VERSION "dbc-export 1 2025.20.8"

NS_ :

BS_:

BU_: ADSP APB APP APS APSB BB BMS CC CMP CMPD CP DAS DI DIF DIR DPB EPAS3P EPAS3S EPASTP EPASTS EPBL EPBR ESP GTW HVP IBST ICR IDB OCS1P ODIN PARK PCS PLG PM PMF PMR PTC RADC RCM RCM2 RCU SCCM SDCR TAS TCU TPMS TRCM UDS UI UIS UMC USM VC VCFRONT VCLEFT VCRIGHT VCSEC

BO_ 2013 VCLEFT_alertLog: 8 VCLEFT
 SG_ VCLEFT_alertID M : 0|10@1+ (1,0) [0|1023] "" Vector__XXX
 SG_ VCLEFT_a404_rightSteeringWheelSw m404 : 17|1@1+ (1,0) [0|1] "" Vector__XXX
 SG_ VCLEFT_a405_leftSteeringWheelSwi m405 : 16|1@1+ (1,0) [0|1] "" Vector__XXX
 SG_ VCLEFT_a405_rightSteeringWheelSw m405 : 17|1@1+ (1,0) [0|1] "" Vector__XXX
 SG_ VCLEFT_a406_leftSteeringWheelSwi m406 : 16|1@1+ (1,0) [0|1] "" Vector__XXX
 SG_ VCLEFT_a406_rightSteeringWheelSw m406 : 17|1@1+ (1,0) [0|1] "" Vector__XXX
 SG_ VCLEFT_a407_leftSteeringWheelSwi m407 : 16|1@1+ (1,0) [0|1] "" Vector__XXX
 SG_ VCLEFT_a407_rightSteeringWheelSw m407 : 17|1@1+ (1,0) [0|1] "" Vector__XXX
 SG_ VCLEFT_a409_leftScrollWheelFault m409 : 16|1@1+ (1,0) [0|1] "" Vector__XXX
 SG_ VCLEFT_a409_rightScrollWheelFaul m409 : 17|1@1+ (1,0) [0|1] "" Vector__XXX
 SG_ VCLEFT_a409_rightScrollWheelPrev m409 : 18|1@1+ (1,0) [0|1] "" Vector__XXX
 SG_ VCLEFT_a409_rightScrollWheelChal m409 : 24|16@1+ (1,0) [0|65535] "" Vector__XXX
 SG_ VCLEFT_a409_rightScrollWheelRaw0 m409 : 40|8@1+ (1,0) [0|255] "" Vector__XXX
 SG_ VCLEFT_a409_rightScrollWheelRaw1 m409 : 48|8@1+ (1,0) [0|255] "" Vector__XXX
 SG_ VCLEFT_a410_leftScrollWheelFault m410 : 16|1@1+ (1,0) [0|1] "" Vector__XXX
 SG_ VCLEFT_a410_rightScrollWheelFaul m410 : 17|1@1+ (1,0) [0|1] "" Vector__XXX
 SG_ VCLEFT_a411_leftScrollWheelFault m411 : 16|1@1+ (1,0) [0|1] "" Vector__XXX
 SG_ VCLEFT_a411_rightScrollWheelFaul m411 : 17|1@1+ (1,0) [0|1] "" Vector__XXX
 SG_ VCLEFT_a412_outputFaulted m412 : 16|1@1+ (1,0) [0|1] "" Vector__XXX
 SG_ VCLEFT_a412_currentSenseFaulted m412 : 17|1@1+ (1,0) [0|1] "" Vector__XXX
 SG_ VCLEFT_a412_tempSenseFaulted m412 : 18|1@1+ (1,0) [0|1] "" Vector__XXX
 SG_ VCLEFT_a412_underCurrent m412 : 19|1@1+ (1,0) [0|1] "" Vector__XXX
 SG_ VCLEFT_a412_overCurrent m412 : 20|1@1+ (1,0) [0|1] "" Vector__XXX
 SG_ VCLEFT_a412_overTemperature m412 : 21|1@1+ (1,0) [0|1] "" Vector__XXX
 SG_ VCLEFT_a414_leftHapticMotorFault m414 : 16|1@1+ (1,0) [0|1] "" Vector__XXX
 SG_ VCLEFT_a414_rightHapticMotorFaul m414 : 17|1@1+ (1,0) [0|1] "" Vector__XXX
 SG_ VCLEFT_a415_leftVbatUndervoltage m415 : 16|1@1+ (1,0) [0|1] "" Vector__XXX
 SG_ VCLEFT_a415_rightVbatUndervoltag m415 : 17|1@1+ (1,0) [0|1] "" Vector__XXX
 SG_ VCLEFT_a415_leftVbatOvervoltageF m415 : 18|1@1+ (1,0) [0|1] "" Vector__XXX
 SG_ VCLEFT_a415_rightVbatOvervoltage m415 : 19|1@1+ (1,0) [0|1] "" Vector__XXX
 SG_ VCLEFT_a417_leftDomeTouch m417 : 16|1@1+ (1,0) [0|1] "" Vector__XXX
 SG_ VCLEFT_a417_parkButtonTouch m417 : 17|1@1+ (1,0) [0|1] "" Vector__XXX
 SG_ VCLEFT_a417_reverseButtonTouch m417 : 18|1@1+ (1,0) [0|1] "" Vector__XXX
 SG_ VCLEFT_a417_hazardButtonTouch m417 : 19|1@1+ (1,0) [0|1] "" Vector__XXX
 SG_ VCLEFT_a417_neutralButtonTouch m417 : 20|1@1+ (1,0) [0|1] "" Vector__XXX
 SG_ VCLEFT_a417_driveButtonTouch m417 : 21|1@1+ (1,0) [0|1] "" Vector__XXX
 SG_ VCLEFT_a417_rightDomeTouch m417 : 22|1@1+ (1,0) [0|1] "" Vector__XXX
 SG_ VCLEFT_a419_leftDomeTouch m419 : 16|1@1+ (1,0) [0|1] "" Vector__XXX
 SG_ VCLEFT_a419_parkButtonTouch m419 : 17|1@1+ (1,0) [0|1] "" Vector__XXX
 SG_ VCLEFT_a419_reverseButtonTouch m419 : 18|1@1+ (1,0) [0|1] "" Vector__XXX
 SG_ VCLEFT_a419_hazardButtonTouch m419 : 19|1@1+ (1,0) [0|1] "" Vector__XXX
 SG_ VCLEFT_a419_neutralButtonTouch m419 : 20|1@1+ (1,0) [0|1] "" Vector__XXX
 SG_ VCLEFT_a419_driveButtonTouch m419 : 21|1@1+ (1,0) [0|1] "" Vector__XXX
 SG_ VCLEFT_a419_rightDomeTouch m419 : 22|1@1+ (1,0) [0|1] "" Vector__XXX
 SG_ VCLEFT_a420_leftDomeTouch m420 : 16|1@1+ (1,0) [0|1] "" Vector__XXX
 SG_ VCLEFT_a420_parkButtonTouch m420 : 17|1@1+ (1,0) [0|1] "" Vector__XXX
 SG_ VCLEFT_a420_reverseButtonTouch m420 : 18|1@1+ (1,0) [0|1] "" Vector__XXX
 SG_ VCLEFT_a420_hazardButtonTouch m420 : 19|1@1+ (1,0) [0|1] "" Vector__XXX
 SG_ VCLEFT_a420_neutralButtonTouch m420 : 20|1@1+ (1,0) [0|1] "" Vector__XXX
 SG_ VCLEFT_a420_driveButtonTouch m420 : 21|1@1+ (1,0) [0|1] "" Vector__XXX
 SG_ VCLEFT_a420_rightDomeTouch m420 : 22|1@1+ (1,0) [0|1] "" Vector__XXX
 SG_ VCLEFT_a421_parkButtonForce m421 : 16|1@1+ (1,0) [0|1] "" Vector__XXX
 SG_ VCLEFT_a421_reverseButtonForce m421 : 17|1@1+ (1,0) [0|1] "" Vector__XXX
 SG_ VCLEFT_a421_hazardButtonForce m421 : 18|1@1+ (1,0) [0|1] "" Vector__XXX
 SG_ VCLEFT_a421_neutralButtonForce m421 : 19|1@1+ (1,0) [0|1] "" Vector__XXX
 SG_ VCLEFT_a421_driveButtonForce m421 : 20|1@1+ (1,0) [0|1] "" Vector__XXX
 SG_ VCLEFT_a424_parkButtonLED m424 : 16|1@1+ (1,0) [0|1] "" Vector__XXX
 SG_ VCLEFT_a424_reverseButtonLED m424 : 17|1@1+ (1,0) [0|1] "" Vector__XXX
 SG_ VCLEFT_a424_neutralButtonLED m424 : 18|1@1+ (1,0) [0|1] "" Vector__XXX
 SG_ VCLEFT_a424_driveButtonLED m424 : 19|1@1+ (1,0) [0|1] "" Vector__XXX
 SG_ VCLEFT_a424_commonButtonLED m424 : 20|1@1+ (1,0) [0|1] "" Vector__XXX
 SG_ VCLEFT_a425_leftVisorLightStatus m425 : 16|1@1+ (1,0) [0|1] "" Vector__XXX
 SG_ VCLEFT_a425_rightVisorLightStatu m425 : 17|1@1+ (1,0) [0|1] "" Vector__XXX
 SG_ VCLEFT_a426_seatMotorCalibrated m426 : 16|1@1+ (1,0) [0|1] "" Vector__XXX
 SG_ VCLEFT_a426_seatMotorCurrent m426 : 17|12@1- (0.01,0) [-20.48|20.47] "A" Vector__XXX
 SG_ VCLEFT_a426_seatMotorPosReal m426 : 32|12@1- (1,0) [-2048|2047] "mm" Vector__XXX
 SG_ VCLEFT_a426_seatMotorState m426 : 44|3@1+ (1,0) [0|7] "" Vector__XXX
 SG_ VCLEFT_a426_seatSwitchBack m426 : 48|2@1+ (1,0) [1|3] "" Vector__XXX
 SG_ VCLEFT_a426_seatSwitchForward m426 : 50|2@1+ (1,0) [1|3] "" Vector__XXX
 SG_ VCLEFT_a426_cabinTmp m426 : 52|12@1- (0.1,0) [-204.8|204.7] "degC" Vector__XXX
 SG_ VCLEFT_a427_seatMotorCalibrated m427 : 16|1@1+ (1,0) [0|1] "" Vector__XXX
 SG_ VCLEFT_a427_seatMotorCurrent m427 : 17|12@1- (0.01,0) [-20.48|20.47] "A" Vector__XXX
 SG_ VCLEFT_a427_seatMotorPosReal m427 : 32|12@1- (1,0) [-2048|2047] "mm" Vector__XXX
 SG_ VCLEFT_a427_seatMotorState m427 : 44|3@1+ (1,0) [0|7] "" Vector__XXX
 SG_ VCLEFT_a427_seatSwitchBack m427 : 48|2@1+ (1,0) [1|3] "" Vector__XXX
 SG_ VCLEFT_a427_seatSwitchForward m427 : 50|2@1+ (1,0) [1|3] "" Vector__XXX
 SG_ VCLEFT_a427_cabinTmp m427 : 52|12@1- (0.1,0) [-204.8|204.7] "degC" Vector__XXX
 SG_ VCLEFT_a428_seatMotorCalibrated m428 : 16|1@1+ (1,0) [0|1] "" Vector__XXX
 SG_ VCLEFT_a428_seatMotorCurrent m428 : 17|12@1- (0.01,0) [-20.48|20.47] "A" Vector__XXX
 SG_ VCLEFT_a428_seatMotorPosReal m428 : 32|12@1- (1,0) [-2048|2047] "mm" Vector__XXX
 SG_ VCLEFT_a428_seatMotorState m428 : 44|3@1+ (1,0) [0|7] "" Vector__XXX
 SG_ VCLEFT_a428_seatSwitchBack m428 : 48|2@1+ (1,0) [1|3] "" Vector__XXX
 SG_ VCLEFT_a428_seatSwitchForward m428 : 50|2@1+ (1,0) [1|3] "" Vector__XXX
 SG_ VCLEFT_a428_cabinTmp m428 : 52|12@1- (0.1,0) [-204.8|204.7] "degC" Vector__XXX
 SG_ VCLEFT_a429_seatMotorCalibrated m429 : 16|1@1+ (1,0) [0|1] "" Vector__XXX
 SG_ VCLEFT_a429_seatMotorCurrent m429 : 17|12@1- (0.01,0) [-20.48|20.47] "A" Vector__XXX
 SG_ VCLEFT_a429_seatMotorPosReal m429 : 32|12@1- (1,0) [-2048|2047] "mm" Vector__XXX
 SG_ VCLEFT_a429_seatMotorState m429 : 44|3@1+ (1,0) [0|7] "" Vector__XXX
 SG_ VCLEFT_a429_seatSwitchBack m429 : 48|2@1+ (1,0) [1|3] "" Vector__XXX
 SG_ VCLEFT_a429_seatSwitchForward m429 : 50|2@1+ (1,0) [1|3] "" Vector__XXX
 SG_ VCLEFT_a429_cabinTmp m429 : 52|12@1- (0.1,0) [-204.8|204.7] "degC" Vector__XXX
 SG_ VCLEFT_a430_leftRearDomeLightPow m430 : 16|1@1+ (1,0) [0|1] "" Vector__XXX
 SG_ VCLEFT_a430_rightRearDomeLightPo m430 : 17|1@1+ (1,0) [0|1] "" Vector__XXX
 SG_ VCLEFT_a431_dcdcVoltageFailure m431 : 16|1@1+ (1,0) [0|1] "" Vector__XXX
 SG_ VCLEFT_a431_overVoltageDetected m431 : 17|1@1+ (1,0) [0|1] "" Vector__XXX
 SG_ VCLEFT_a431_underVoltageDetected m431 : 18|1@1+ (1,0) [0|1] "" Vector__XXX
 SG_ VCLEFT_a431_brownoutDetected m431 : 19|1@1+ (1,0) [0|1] "" Vector__XXX
 SG_ VCLEFT_a444_retriesAvailable m444 : 16|8@1+ (1,0) [0|255] "" Vector__XXX
 SG_ VCLEFT_a444_channel m444 : 24|8@1+ (1,0) [0|255] "" Vector__XXX
 SG_ VCLEFT_a444_watchdog m444 : 32|1@1+ (1,0) [0|1] "" Vector__XXX
 SG_ VCLEFT_a444_gateDriver m444 : 33|1@1+ (1,0) [0|1] "" Vector__XXX
 SG_ VCLEFT_a444_overcurrent m444 : 34|1@1+ (1,0) [0|1] "" Vector__XXX
 SG_ VCLEFT_a444_supplyUndervoltage m444 : 35|1@1+ (1,0) [0|1] "" Vector__XXX
 SG_ VCLEFT_a444_cpUndervoltage m444 : 36|1@1+ (1,0) [0|1] "" Vector__XXX
 SG_ VCLEFT_a444_overTempShutdown m444 : 37|1@1+ (1,0) [0|1] "" Vector__XXX
 SG_ VCLEFT_a444_overTempWarning m444 : 38|1@1+ (1,0) [0|1] "" Vector__XXX
 SG_ VCLEFT_a444_highSide2GateDriver m444 : 39|1@1+ (1,0) [0|1] "" Vector__XXX
 SG_ VCLEFT_a444_lowSide2GateDriver m444 : 40|1@1+ (1,0) [0|1] "" Vector__XXX
 SG_ VCLEFT_a444_highSide1GateDriver m444 : 41|1@1+ (1,0) [0|1] "" Vector__XXX
 SG_ VCLEFT_a444_lowSide1GateDriver m444 : 42|1@1+ (1,0) [0|1] "" Vector__XXX
 SG_ VCLEFT_a444_highSide2OverCurent m444 : 43|1@1+ (1,0) [0|1] "" Vector__XXX
 SG_ VCLEFT_a444_lowSide2OverCurent m444 : 44|1@1+ (1,0) [0|1] "" Vector__XXX
 SG_ VCLEFT_a444_highSide1OverCurent m444 : 45|1@1+ (1,0) [0|1] "" Vector__XXX
 SG_ VCLEFT_a444_lowSide1OverCurent m444 : 46|1@1+ (1,0) [0|1] "" Vector__XXX
 SG_ VCLEFT_a444_spiInit m444 : 47|1@1+ (1,0) [0|1] "" Vector__XXX
 SG_ VCLEFT_a444_spiPeriodicCheck m444 : 48|1@1+ (1,0) [0|1] "" Vector__XXX
 SG_ VCLEFT_a444_spiFault m444 : 49|1@1+ (1,0) [0|1] "" Vector__XXX
 SG_ VCLEFT_a444_voltageMonitor m444 : 50|1@1+ (1,0) [0|1] "" Vector__XXX
 SG_ VCLEFT_a444_enableLow m444 : 51|1@1+ (1,0) [0|1] "" Vector__XXX
 SG_ VCLEFT_a447_endstopPositionMM m447 : 16|16@1- (0.01,0) [-327.68|327.67] "mm" Vector__XXX
 SG_ VCLEFT_a447_motorType m447 : 32|2@1+ (1,0) [0|3] "" Vector__XXX
 SG_ VCLEFT_a448_endstopPositionMM m448 : 16|16@1- (0.01,0) [-327.68|327.67] "mm" Vector__XXX
 SG_ VCLEFT_a448_motorType m448 : 32|2@1+ (1,0) [0|3] "" Vector__XXX
 SG_ VCLEFT_a453_liftgatePosition m453 : 16|7@1- (1,43) [-21|106] "deg" Vector__XXX
 SG_ VCLEFT_a455_liftgateState m455 : 16|4@1+ (1,0) [0|15] "" Vector__XXX
 SG_ VCLEFT_a466_hvac2RLeftAirwaveVer m466 : 16|1@1+ (1,0) [0|1] "" Vector__XXX
 SG_ VCLEFT_a469_hvac2RLeftAirwaveLat m469 : 16|1@1+ (1,0) [0|1] "" Vector__XXX
 SG_ VCLEFT_a472_hvac2RRightAirwaveVe m472 : 16|1@1+ (1,0) [0|1] "" Vector__XXX
 SG_ VCLEFT_a475_hvac2RRightAirwaveLa m475 : 16|1@1+ (1,0) [0|1] "" Vector__XXX
 SG_ VCLEFT_a480_reset m480 : 16|1@1+ (1,0) [0|1] "" Vector__XXX
 SG_ VCLEFT_a480_spiError m480 : 17|1@1+ (1,0) [0|1] "" Vector__XXX
 SG_ VCLEFT_a480_autoOn m480 : 18|1@1+ (1,0) [0|1] "" Vector__XXX
 SG_ VCLEFT_a480_diagnosticBit m480 : 19|1@1+ (1,0) [0|1] "" Vector__XXX
 SG_ VCLEFT_a480_deviceError m480 : 20|1@1+ (1,0) [0|1] "" Vector__XXX
 SG_ VCLEFT_a480_overcurrent m480 : 21|1@1+ (1,0) [0|1] "" Vector__XXX
 SG_ VCLEFT_a480_unexpectedLock m480 : 22|1@1+ (1,0) [0|1] "" Vector__XXX
 SG_ VCLEFT_a480_disableOutputFault m480 : 23|1@1+ (1,0) [0|1] "" Vector__XXX
 SG_ VCLEFT_a480_vsUndervoltage m480 : 24|1@1+ (1,0) [0|1] "" Vector__XXX
 SG_ VCLEFT_a480_hardShort m480 : 25|1@1+ (1,0) [0|1] "" Vector__XXX
 SG_ VCLEFT_a480_vdsMax m480 : 26|1@1+ (1,0) [0|1] "" Vector__XXX
 SG_ VCLEFT_a480_bypassSaturation m480 : 27|1@1+ (1,0) [0|1] "" Vector__XXX
 SG_ VCLEFT_a480_fuseLatch m480 : 28|1@1+ (1,0) [0|1] "" Vector__XXX
 SG_ VCLEFT_a480_deviceOvertemperatur m480 : 29|1@1+ (1,0) [0|1] "" Vector__XXX
 SG_ VCLEFT_a480_ntcOvertemperature m480 : 30|1@1+ (1,0) [0|1] "" Vector__XXX
 SG_ VCLEFT_a480_vgsLow m480 : 31|1@1+ (1,0) [0|1] "" Vector__XXX
 SG_ VCLEFT_a480_chargePumpLow m480 : 32|1@1+ (1,0) [0|1] "" Vector__XXX
 SG_ VCLEFT_a480_watchdog m480 : 33|1@1+ (1,0) [0|1] "" Vector__XXX
 SG_ VCLEFT_a480_spiNotDone m480 : 34|1@1+ (1,0) [0|1] "" Vector__XXX
 SG_ VCLEFT_a480_configIncorrect m480 : 35|1@1+ (1,0) [0|1] "" Vector__XXX
 SG_ VCLEFT_a480_bufferFull m480 : 36|1@1+ (1,0) [0|1] "" Vector__XXX
 SG_ VCLEFT_a480_hitAlertRateLimit m480 : 37|1@1+ (1,0) [0|1] "" Vector__XXX
 SG_ VCLEFT_a480_hwlo m480 : 38|1@1+ (1,0) [0|1] "" Vector__XXX
 SG_ VCLEFT_a480_enable m480 : 39|1@1+ (1,0) [0|1] "" Vector__XXX
 SG_ VCLEFT_a482_channel m482 : 16|6@1+ (1,0) [0|63] "" Vector__XXX
 SG_ VCLEFT_a482_spiFault m482 : 22|1@1+ (1,0) [0|1] "" Vector__XXX
 SG_ VCLEFT_a482_resetBar m482 : 23|1@1+ (1,0) [0|1] "" Vector__XXX
 SG_ VCLEFT_a482_overTempShutdown m482 : 24|1@1+ (1,0) [0|1] "" Vector__XXX
 SG_ VCLEFT_a482_thermalWarning m482 : 25|1@1+ (1,0) [0|1] "" Vector__XXX
 SG_ VCLEFT_a482_underOrOverVoltageOr m482 : 26|1@1+ (1,0) [0|1] "" Vector__XXX
 SG_ VCLEFT_a482_underloadDetected m482 : 27|1@1+ (1,0) [0|1] "" Vector__XXX
 SG_ VCLEFT_a500_channel m500 : 16|8@1+ (1,0) [0|255] "" Vector__XXX
 SG_ VCLEFT_a500_mismatchedState m500 : 24|3@1+ (1,0) [0|7] "" Vector__XXX
 SG_ VCLEFT_a520_epbConfig m520 : 16|4@1+ (1,0) [0|15] "" Vector__XXX
 SG_ VCLEFT_a520_gtwEpbConfig m520 : 20|4@1+ (1,0) [0|15] "" Vector__XXX
 SG_ VCLEFT_a523_channel m523 : 16|8@1+ (1,0) [0|255] "" Vector__XXX
 SG_ VCLEFT_a523_control2Byte1 m523 : 24|8@1+ (1,0) [0|255] "" Vector__XXX
 SG_ VCLEFT_a523_control2Byte2 m523 : 32|8@1+ (1,0) [0|255] "" Vector__XXX
 SG_ VCLEFT_a523_control2Byte3 m523 : 40|8@1+ (1,0) [0|255] "" Vector__XXX
 SG_ VCLEFT_a523_control3Byte2 m523 : 48|8@1+ (1,0) [0|255] "" Vector__XXX
 SG_ VCLEFT_a523_control3Byte3 m523 : 56|8@1+ (1,0) [0|255] "" Vector__XXX
 SG_ VCLEFT_a525_GTW_twelveVBatteryTy m525 : 16|3@1+ (1,0) [0|7] "" Vector__XXX
 SG_ VCLEFT_a525_newLVBatteryType m525 : 19|3@1+ (1,0) [0|7] "" Vector__XXX
 SG_ VCLEFT_a525_initialLVBatteryType m525 : 24|3@1+ (1,0) [0|7] "" Vector__XXX
 SG_ VCLEFT_a525_serviceMode m525 : 27|1@1+ (1,0) [0|1] "" Vector__XXX
 SG_ VCLEFT_a525_factoryGated m525 : 28|1@1+ (1,0) [0|1] "" Vector__XXX
 SG_ VCLEFT_a525_frunkOpen m525 : 29|1@1+ (1,0) [0|1] "" Vector__XXX
 SG_ VCLEFT_a536_trunkFoldFlatSwitchS m536 : 16|2@1+ (1,0) [1|3] "" Vector__XXX
 SG_ VCLEFT_a536_trunkFoldFlatLeftSwi m536 : 18|10@1+ (0.00488758552819,0) [0|4.99999999534] "V" Vector__XXX
 SG_ VCLEFT_a545_GTW_twelveVBatteryTy m545 : 16|3@1+ (1,0) [0|7] "" Vector__XXX
 SG_ VCLEFT_a545_newLVBatteryType m545 : 19|3@1+ (1,0) [0|7] "" Vector__XXX
 SG_ VCLEFT_a545_serviceMode m545 : 22|1@1+ (1,0) [0|1] "" Vector__XXX
 SG_ VCLEFT_a545_factoryGated m545 : 23|1@1+ (1,0) [0|1] "" Vector__XXX
 SG_ VCLEFT_a545_frunkOpen m545 : 24|1@1+ (1,0) [0|1] "" Vector__XXX
 SG_ VCLEFT_a551_restrictDoorReleaseS m551 : 16|1@1+ (1,0) [0|1] "" Vector__XXX
 SG_ VCLEFT_a551_interiorReleaseReqCo m551 : 24|8@1+ (1,0) [0|255] "" Vector__XXX
 SG_ VCLEFT_a551_lastRequestSourceFro m551 : 32|3@1+ (1,0) [0|7] "" Vector__XXX
 SG_ VCLEFT_a551_restrictDoorRel_0001 m551 : 35|1@1+ (1,0) [0|1] "" Vector__XXX
 SG_ VCLEFT_a551_interiorRelease_0001 m551 : 40|8@1+ (1,0) [0|255] "" Vector__XXX
 SG_ VCLEFT_a551_lastRequestSourceRea m551 : 48|3@1+ (1,0) [0|7] "" Vector__XXX
 SG_ VCLEFT_a555_heaterPWMCommand m555 : 16|8@1+ (1,0) [0|255] "" Vector__XXX
 SG_ VCLEFT_a555_ntcTemperature m555 : 24|8@1+ (1,0) [0|255] "" Vector__XXX
 SG_ VCLEFT_a560_isRearwardEndstopUnc m560 : 16|1@1+ (1,0) [0|1] "" Vector__XXX
 SG_ VCLEFT_a560_isAbsPosSensorUncali m560 : 17|1@1+ (1,0) [0|1] "" Vector__XXX
 SG_ VCLEFT_a560_seatState m560 : 18|4@1+ (1,0) [0|14] "" Vector__XXX
 SG_ VCLEFT_a560_motorType m560 : 22|1@1+ (1,0) [0|1] "" Vector__XXX
 SG_ VCLEFT_a560_absPosSensState m560 : 24|2@1+ (1,0) [0|3] "" Vector__XXX
 SG_ VCLEFT_a563_calibrated m563 : 16|1@1+ (1,0) [0|1] "" Vector__XXX
 SG_ VCLEFT_a563_angle m563 : 17|8@1- (0.5,59) [-5|122.5] "deg" Vector__XXX
 SG_ VCLEFT_a563_seatStatePrev m563 : 25|4@1+ (1,0) [0|14] "" Vector__XXX
 SG_ VCLEFT_a563_obstacleDetectReason m563 : 29|4@1+ (1,0) [0|15] "" Vector__XXX
 SG_ VCLEFT_a563_accelLookbackTripDep m563 : 33|7@1+ (1,0) [0|127] "" Vector__XXX
 SG_ VCLEFT_a563_duty m563 : 40|8@1- (1,0) [-128|127] "%" Vector__XXX
 SG_ VCLEFT_a563_currentAbsFilt m563 : 48|8@1+ (0.25,0) [0|63.75] "A" Vector__XXX
 SG_ VCLEFT_a563_motorType m563 : 56|1@1+ (1,0) [0|1] "" Vector__XXX
 SG_ VCLEFT_a563_absolutePosSensorFor m563 : 57|1@1+ (1,0) [0|1] "" Vector__XXX
 SG_ VCLEFT_a563_cabinTemp m563 : 58|6@1- (2,20) [-44|82] "degC" Vector__XXX
 SG_ VCLEFT_a567_isRearwardEndstopUnc m567 : 16|1@1+ (1,0) [0|1] "" Vector__XXX
 SG_ VCLEFT_a567_isAbsPosSensorUncali m567 : 17|1@1+ (1,0) [0|1] "" Vector__XXX
 SG_ VCLEFT_a568_seatState m568 : 16|4@1+ (1,0) [0|14] "" Vector__XXX
 SG_ VCLEFT_a570_seatHeatCurrent m570 : 16|12@1+ (0.01,0) [0|40.95] "A" Vector__XXX
 SG_ VCLEFT_a570_seatHeatTmp m570 : 28|12@1- (0.05,0) [-102.4|102.35] "degC" Vector__XXX
 SG_ VCLEFT_a571_seatHeatCurrent m571 : 16|12@1+ (0.01,0) [0|40.95] "A" Vector__XXX
 SG_ VCLEFT_a571_seatHeatTmp m571 : 28|12@1- (0.05,0) [-102.4|102.35] "degC" Vector__XXX
 SG_ VCLEFT_a572_seatHeatCurrent m572 : 16|12@1+ (0.01,0) [0|40.95] "A" Vector__XXX
 SG_ VCLEFT_a572_seatHeatTmp m572 : 28|12@1- (0.05,0) [-102.4|102.35] "degC" Vector__XXX
 SG_ VCLEFT_a573_seatHeatCurrent m573 : 16|12@1+ (0.01,0) [0|40.95] "A" Vector__XXX
 SG_ VCLEFT_a573_seatHeatTmp m573 : 28|12@1- (0.05,0) [-102.4|102.35] "degC" Vector__XXX
 SG_ VCLEFT_a577_outputFaulted m577 : 16|1@1+ (1,0) [0|1] "" Vector__XXX
 SG_ VCLEFT_a577_currentSenseFaulted m577 : 17|1@1+ (1,0) [0|1] "" Vector__XXX
 SG_ VCLEFT_a577_tempSenseFaulted m577 : 18|1@1+ (1,0) [0|1] "" Vector__XXX
 SG_ VCLEFT_a577_underCurrent m577 : 19|1@1+ (1,0) [0|1] "" Vector__XXX
 SG_ VCLEFT_a577_overCurrent m577 : 20|1@1+ (1,0) [0|1] "" Vector__XXX
 SG_ VCLEFT_a577_overTemperature m577 : 21|1@1+ (1,0) [0|1] "" Vector__XXX
 SG_ VCLEFT_a578_openCircuitDashFL m578 : 16|1@1+ (1,0) [0|1] "" Vector__XXX
 SG_ VCLEFT_a578_shortCircuitDashFL m578 : 17|1@1+ (1,0) [0|1] "" Vector__XXX
 SG_ VCLEFT_a578_miaDashFL m578 : 18|1@1+ (1,0) [0|1] "" Vector__XXX
 SG_ VCLEFT_a578_openCircuitDashFR m578 : 19|1@1+ (1,0) [0|1] "" Vector__XXX
 SG_ VCLEFT_a578_shortCircuitDashFR m578 : 20|1@1+ (1,0) [0|1] "" Vector__XXX
 SG_ VCLEFT_a578_miaDashFR m578 : 21|1@1+ (1,0) [0|1] "" Vector__XXX
 SG_ VCLEFT_a578_openCircuitDoorFL m578 : 22|1@1+ (1,0) [0|1] "" Vector__XXX
 SG_ VCLEFT_a578_shortCircuitDoorFL m578 : 23|1@1+ (1,0) [0|1] "" Vector__XXX
 SG_ VCLEFT_a578_miaDoorFL m578 : 24|1@1+ (1,0) [0|1] "" Vector__XXX
 SG_ VCLEFT_a578_openCircuitDoorRL m578 : 25|1@1+ (1,0) [0|1] "" Vector__XXX
 SG_ VCLEFT_a578_shortCircuitDoorRL m578 : 26|1@1+ (1,0) [0|1] "" Vector__XXX
 SG_ VCLEFT_a578_miaDoorRL m578 : 27|1@1+ (1,0) [0|1] "" Vector__XXX
 SG_ VCLEFT_a579_gtwConfigType m579 : 16|3@1+ (1,0) [0|7] "" Vector__XXX
 SG_ VCLEFT_a579_installedHwid m579 : 24|32@1+ (1,0) [0|4294967295] "" Vector__XXX
 SG_ VCLEFT_a580_gtwConfigType m580 : 16|3@1+ (1,0) [0|7] "" Vector__XXX
 SG_ VCLEFT_a580_installedHwid m580 : 24|32@1+ (1,0) [0|4294967295] "" Vector__XXX
 SG_ VCLEFT_a581_outputFaulted m581 : 16|1@1+ (1,0) [0|1] "" Vector__XXX
 SG_ VCLEFT_a581_currentSenseFaulted m581 : 17|1@1+ (1,0) [0|1] "" Vector__XXX
 SG_ VCLEFT_a581_tempSenseFaulted m581 : 18|1@1+ (1,0) [0|1] "" Vector__XXX
 SG_ VCLEFT_a581_underCurrent m581 : 19|1@1+ (1,0) [0|1] "" Vector__XXX
 SG_ VCLEFT_a581_overCurrent m581 : 20|1@1+ (1,0) [0|1] "" Vector__XXX
 SG_ VCLEFT_a581_overTemperature m581 : 21|1@1+ (1,0) [0|1] "" Vector__XXX
 SG_ VCLEFT_a585_ambientTemp m585 : 16|8@1+ (0.5,-40) [-39.5|87.5] "degC" Vector__XXX
 SG_ VCLEFT_a586_ambientTemp m586 : 16|8@1+ (0.5,-40) [-39.5|87.5] "degC" Vector__XXX
 SG_ VCLEFT_a599_GTW_twelveVBatteryTy m599 : 16|3@1+ (1,0) [0|7] "" Vector__XXX
 SG_ VCLEFT_a599_newLVBatteryType m599 : 19|3@1+ (1,0) [0|7] "" Vector__XXX
 SG_ VCLEFT_a599_initialLVBatteryType m599 : 24|3@1+ (1,0) [0|7] "" Vector__XXX
 SG_ VCLEFT_a599_serviceMode m599 : 27|1@1+ (1,0) [0|1] "" Vector__XXX
 SG_ VCLEFT_a599_factoryGated m599 : 28|1@1+ (1,0) [0|1] "" Vector__XXX
 SG_ VCLEFT_a599_frunkOpen m599 : 29|1@1+ (1,0) [0|1] "" Vector__XXX
 SG_ VCLEFT_a617_VEH_VC_infoMessage m617 : 16|1@1+ (1,0) [0|1] "" Vector__XXX
 SG_ VCLEFT_a617_BDY_defogInfoMessage m617 : 17|1@1+ (1,0) [0|1] "" Vector__XXX
 SG_ VCLEFT_a617_VEH_defogInfoMessage m617 : 18|1@1+ (1,0) [0|1] "" Vector__XXX
 SG_ VCLEFT_a617_VEH_thermalStatus m617 : 19|1@1+ (1,0) [0|1] "" Vector__XXX

BO_ 864 VCLEFT_alertMatrix: 8 VCLEFT
 SG_ VCLEFT_matrixIndex M : 0|4@1+ (1,0) [0|15] "" Vector__XXX
 SG_ VCLEFT_a001_WatchdogReset m0 : 4|1@1+ (1,0) [0|1] "" Vector__XXX
 SG_ VCLEFT_a002_PowerLossReset m0 : 5|1@1+ (1,0) [0|1] "" Vector__XXX
 SG_ VCLEFT_a003_SWAssertion m0 : 6|1@1+ (1,0) [0|1] "" Vector__XXX
 SG_ VCLEFT_a005_CANTXError m0 : 8|1@1+ (1,0) [0|1] "" Vector__XXX
 SG_ VCLEFT_a006_CANTX_cyclicError m0 : 9|1@1+ (1,0) [0|1] "" Vector__XXX
 SG_ VCLEFT_a010_ExtSupplyVoltError m0 : 13|1@1+ (1,0) [0|1] "" Vector__XXX
 SG_ VCLEFT_a012_CPUReset m0 : 15|1@1+ (1,0) [0|1] "" Vector__XXX
 SG_ VCLEFT_a013_AlertManagerFault m0 : 16|1@1+ (1,0) [0|1] "" Vector__XXX
 SG_ VCLEFT_a015_NVMMError m0 : 18|1@1+ (1,0) [0|1] "" Vector__XXX
 SG_ VCLEFT_a016_NVMMRecordError m0 : 19|1@1+ (1,0) [0|1] "" Vector__XXX
 SG_ VCLEFT_a017_NVMMStatusDbg m0 : 20|1@1+ (1,0) [0|1] "" Vector__XXX
 SG_ VCLEFT_a021_TaskSchedulerError m0 : 24|1@1+ (1,0) [0|1] "" Vector__XXX
 SG_ VCLEFT_a022_TaskInitError m0 : 25|1@1+ (1,0) [0|1] "" Vector__XXX
 SG_ VCLEFT_a029_CoreDump m0 : 32|1@1+ (1,0) [0|1] "" Vector__XXX
 SG_ VCLEFT_a030_ECULogUploadRequest m0 : 33|1@1+ (1,0) [0|1] "" Vector__XXX
 SG_ VCLEFT_a031_UDSActive m0 : 34|1@1+ (1,0) [0|1] "" Vector__XXX
 SG_ VCLEFT_a041_HighCPULoad m0 : 44|1@1+ (1,0) [0|1] "" Vector__XXX
 SG_ VCLEFT_a042_HighStackUsage m0 : 45|1@1+ (1,0) [0|1] "" Vector__XXX
 SG_ VCLEFT_a043_Task1msError m0 : 46|1@1+ (1,0) [0|1] "" Vector__XXX
 SG_ VCLEFT_a044_Task10msError m0 : 47|1@1+ (1,0) [0|1] "" Vector__XXX
 SG_ VCLEFT_a045_Task100msError m0 : 48|1@1+ (1,0) [0|1] "" Vector__XXX
 SG_ VCLEFT_a046_Task1000msError m0 : 49|1@1+ (1,0) [0|1] "" Vector__XXX
 SG_ VCLEFT_a057_HVP_MIA m0 : 60|1@1+ (1,0) [0|1] "" Vector__XXX
 SG_ VCLEFT_a058_inputRHighSyncDebug m0 : 61|1@1+ (1,0) [0|1] "" Vector__XXX
 SG_ VCLEFT_a059_inputResistanceHigh m0 : 62|1@1+ (1,0) [0|1] "" Vector__XXX
 SG_ VCLEFT_a060_engineeringBuild m0 : 63|1@1+ (1,0) [0|1] "" Vector__XXX
 SG_ VCLEFT_a061_XCPConnected m1 : 4|1@1+ (1,0) [0|1] "" Vector__XXX
 SG_ VCLEFT_a062_XCPWasConnected m1 : 5|1@1+ (1,0) [0|1] "" Vector__XXX
 SG_ VCLEFT_a063_SwitchFault m1 : 6|1@1+ (1,0) [0|1] "" Vector__XXX
 SG_ VCLEFT_a064_busSleepReqTimeout m1 : 7|1@1+ (1,0) [0|1] "" Vector__XXX
 SG_ VCLEFT_a065_emiosIsrRateLimitedD m1 : 8|1@1+ (1,0) [0|1] "" Vector__XXX
 SG_ VCLEFT_a066_emiosIsrShortPeriodD m1 : 9|1@1+ (1,0) [0|1] "" Vector__XXX
 SG_ VCLEFT_a082_VCRIGHT_IPC_MIA m1 : 25|1@1+ (1,0) [0|1] "" Vector__XXX
 SG_ VCLEFT_a083_VCLEFT_IPC_MIA m1 : 26|1@1+ (1,0) [0|1] "" Vector__XXX
 SG_ VCLEFT_a084_TPMS_MIA m1 : 27|1@1+ (1,0) [0|1] "" Vector__XXX
 SG_ VCLEFT_a085_CCCM_MIA m1 : 28|1@1+ (1,0) [0|1] "" Vector__XXX
 SG_ VCLEFT_a086_VCBATT_MIA m1 : 29|1@1+ (1,0) [0|1] "" Vector__XXX
 SG_ VCLEFT_a087_DIREL_MIA m1 : 30|1@1+ (1,0) [0|1] "" Vector__XXX
 SG_ VCLEFT_a088_DIRER_MIA m1 : 31|1@1+ (1,0) [0|1] "" Vector__XXX
 SG_ VCLEFT_a089_IBST_MIA m1 : 32|1@1+ (1,0) [0|1] "" Vector__XXX
 SG_ VCLEFT_a090_APS_MIA m1 : 33|1@1+ (1,0) [0|1] "" Vector__XXX
 SG_ VCLEFT_a091_CMPD_MIA m1 : 34|1@1+ (1,0) [0|1] "" Vector__XXX
 SG_ VCLEFT_a092_VCSEATD_MIA m1 : 35|1@1+ (1,0) [0|1] "" Vector__XXX
 SG_ VCLEFT_a093_VCSEATP_MIA m1 : 36|1@1+ (1,0) [0|1] "" Vector__XXX
 SG_ VCLEFT_a094_EPAS3P_MIA m1 : 37|1@1+ (1,0) [0|1] "" Vector__XXX
 SG_ VCLEFT_a095_CHG_MIA m1 : 38|1@1+ (1,0) [0|1] "" Vector__XXX
 SG_ VCLEFT_a096_OCS1P_MIA m1 : 39|1@1+ (1,0) [0|1] "" Vector__XXX
 SG_ VCLEFT_a097_CMP_MIA m1 : 40|1@1+ (1,0) [0|1] "" Vector__XXX
 SG_ VCLEFT_a098_DIR_MIA m1 : 41|1@1+ (1,0) [0|1] "" Vector__XXX
 SG_ VCLEFT_a099_PARK_MIA m1 : 42|1@1+ (1,0) [0|1] "" Vector__XXX
 SG_ VCLEFT_a100_CANbus_MIA m1 : 43|1@1+ (1,0) [0|1] "" Vector__XXX
 SG_ VCLEFT_a101_PM_MIA m1 : 44|1@1+ (1,0) [0|1] "" Vector__XXX
 SG_ VCLEFT_a102_PTC_MIA m1 : 45|1@1+ (1,0) [0|1] "" Vector__XXX
 SG_ VCLEFT_a103_CP_MIA m1 : 46|1@1+ (1,0) [0|1] "" Vector__XXX
 SG_ VCLEFT_a104_DAS_MIA m1 : 47|1@1+ (1,0) [0|1] "" Vector__XXX
 SG_ VCLEFT_a105_TAS_MIA m1 : 48|1@1+ (1,0) [0|1] "" Vector__XXX
 SG_ VCLEFT_a106_PCS_MIA m1 : 49|1@1+ (1,0) [0|1] "" Vector__XXX
 SG_ VCLEFT_a107_BMS_MIA m1 : 50|1@1+ (1,0) [0|1] "" Vector__XXX
 SG_ VCLEFT_a108_DIF_MIA m1 : 51|1@1+ (1,0) [0|1] "" Vector__XXX
 SG_ VCLEFT_a109_RCM_MIA m1 : 52|1@1+ (1,0) [0|1] "" Vector__XXX
 SG_ VCLEFT_a110_GTW_MIA m1 : 53|1@1+ (1,0) [0|1] "" Vector__XXX
 SG_ VCLEFT_a111_EPBR_MIA m1 : 54|1@1+ (1,0) [0|1] "" Vector__XXX
 SG_ VCLEFT_a112_EPBL_MIA m1 : 55|1@1+ (1,0) [0|1] "" Vector__XXX
 SG_ VCLEFT_a113_UI_MIA m1 : 56|1@1+ (1,0) [0|1] "" Vector__XXX
 SG_ VCLEFT_a114_ESP_MIA m1 : 57|1@1+ (1,0) [0|1] "" Vector__XXX
 SG_ VCLEFT_a115_VCSEC_MIA m1 : 58|1@1+ (1,0) [0|1] "" Vector__XXX
 SG_ VCLEFT_a116_VCRIGHT_MIA m1 : 59|1@1+ (1,0) [0|1] "" Vector__XXX
 SG_ VCLEFT_a117_VCLEFT_MIA m1 : 60|1@1+ (1,0) [0|1] "" Vector__XXX
 SG_ VCLEFT_a118_VCFRONT_MIA m1 : 61|1@1+ (1,0) [0|1] "" Vector__XXX
 SG_ VCLEFT_a119_SCCM_MIA m1 : 62|1@1+ (1,0) [0|1] "" Vector__XXX
 SG_ VCLEFT_a120_DI_DRIVE_MIA m1 : 63|1@1+ (1,0) [0|1] "" Vector__XXX
 SG_ VCLEFT_a121_ETC_MIA m2 : 4|1@1+ (1,0) [0|1] "" Vector__XXX
 SG_ VCLEFT_a122_ICR_MIA m2 : 5|1@1+ (1,0) [0|1] "" Vector__XXX
 SG_ VCLEFT_a123_AID_MIA m2 : 6|1@1+ (1,0) [0|1] "" Vector__XXX
 SG_ VCLEFT_a124_BB_MIA m2 : 7|1@1+ (1,0) [0|1] "" Vector__XXX
 SG_ VCLEFT_a125_RCU_MIA m2 : 8|1@1+ (1,0) [0|1] "" Vector__XXX
 SG_ VCLEFT_a129_blowerICLatchFault m2 : 12|1@1+ (1,0) [0|1] "" Vector__XXX
 SG_ VCLEFT_a130_blowerICWarning m2 : 13|1@1+ (1,0) [0|1] "" Vector__XXX
 SG_ VCLEFT_a131_blowerICTransFault m2 : 14|1@1+ (1,0) [0|1] "" Vector__XXX
 SG_ VCLEFT_a132_blowerSoftStall m2 : 15|1@1+ (1,0) [0|1] "" Vector__XXX
 SG_ VCLEFT_a133_blowerLowRPMCBang m2 : 16|1@1+ (1,0) [0|1] "" Vector__XXX
 SG_ VCLEFT_a134_SteerColUpDownUnCal m2 : 17|1@1+ (1,0) [0|1] "" Vector__XXX
 SG_ VCLEFT_a135_SteerColInOutUnCal m2 : 18|1@1+ (1,0) [0|1] "" Vector__XXX
 SG_ VCLEFT_a136_brakeSwitchMismatch m2 : 19|1@1+ (1,0) [0|1] "" Vector__XXX
 SG_ VCLEFT_a137_VCSECPowerCycled m2 : 20|1@1+ (1,0) [0|1] "" Vector__XXX
 SG_ VCLEFT_a138_consoleDoorAssist m2 : 21|1@1+ (1,0) [0|1] "" Vector__XXX
 SG_ VCLEFT_a139_BLERearPowerCycled m2 : 22|1@1+ (1,0) [0|1] "" Vector__XXX
 SG_ VCLEFT_a140_BLELeftPowerCycled m2 : 23|1@1+ (1,0) [0|1] "" Vector__XXX
 SG_ VCLEFT_a141_12VAuxPowerTrip m2 : 24|1@1+ (1,0) [0|1] "" Vector__XXX
 SG_ VCLEFT_a143_mirrorManuallyFolded m2 : 26|1@1+ (1,0) [0|1] "" Vector__XXX
 SG_ VCLEFT_a145_brakeSwitchStuck m2 : 28|1@1+ (1,0) [0|1] "" Vector__XXX
 SG_ VCLEFT_a148_brakePressInputMisma m2 : 31|1@1+ (1,0) [0|1] "" Vector__XXX
 SG_ VCLEFT_a150_windowPinchFront m2 : 33|1@1+ (1,0) [0|1] "" Vector__XXX
 SG_ VCLEFT_a151_windowPinchRear m2 : 34|1@1+ (1,0) [0|1] "" Vector__XXX
 SG_ VCLEFT_a152_windowUncalFront m2 : 35|1@1+ (1,0) [0|1] "" Vector__XXX
 SG_ VCLEFT_a153_windowUncalRear m2 : 36|1@1+ (1,0) [0|1] "" Vector__XXX
 SG_ VCLEFT_a154_windowThermalFront m2 : 37|1@1+ (1,0) [0|1] "" Vector__XXX
 SG_ VCLEFT_a155_windowThermalRear m2 : 38|1@1+ (1,0) [0|1] "" Vector__XXX
 SG_ VCLEFT_a156_windowNoInputFront m2 : 39|1@1+ (1,0) [0|1] "" Vector__XXX
 SG_ VCLEFT_a157_windowNoInputRear m2 : 40|1@1+ (1,0) [0|1] "" Vector__XXX
 SG_ VCLEFT_a158_windowPinchOverideF m2 : 41|1@1+ (1,0) [0|1] "" Vector__XXX
 SG_ VCLEFT_a159_windowPinchOverideR m2 : 42|1@1+ (1,0) [0|1] "" Vector__XXX
 SG_ VCLEFT_a160_windowUndercurrentF m2 : 43|1@1+ (1,0) [0|1] "" Vector__XXX
 SG_ VCLEFT_a161_windowUndercurrentR m2 : 44|1@1+ (1,0) [0|1] "" Vector__XXX
 SG_ VCLEFT_a162_windowEncoderStallF m2 : 45|1@1+ (1,0) [0|1] "" Vector__XXX
 SG_ VCLEFT_a163_windowEncoderStallR m2 : 46|1@1+ (1,0) [0|1] "" Vector__XXX
 SG_ VCLEFT_a164_windowFactoryTest m2 : 47|1@1+ (1,0) [0|1] "" Vector__XXX
 SG_ VCLEFT_a165_windowFactoryTest2 m2 : 48|1@1+ (1,0) [0|1] "" Vector__XXX
 SG_ VCLEFT_a166_windowDebug m2 : 49|1@1+ (1,0) [0|1] "" Vector__XXX
 SG_ VCLEFT_a167_windowDebugPinchF m2 : 50|1@1+ (1,0) [0|1] "" Vector__XXX
 SG_ VCLEFT_a168_windowDebugPinchR m2 : 51|1@1+ (1,0) [0|1] "" Vector__XXX
 SG_ VCLEFT_a169_windowCurrentPeakF m2 : 52|1@1+ (1,0) [0|1] "" Vector__XXX
 SG_ VCLEFT_a170_windowCurrentPeakR m2 : 53|1@1+ (1,0) [0|1] "" Vector__XXX
 SG_ VCLEFT_a172_SPI_MIA m2 : 55|1@1+ (1,0) [0|1] "" Vector__XXX
 SG_ VCLEFT_a173_windowBtnDoorOpen m2 : 56|1@1+ (1,0) [0|1] "" Vector__XXX
 SG_ VCLEFT_a175_windowSealDefectFron m2 : 58|1@1+ (1,0) [0|1] "" Vector__XXX
 SG_ VCLEFT_a176_windowSealDefectRear m2 : 59|1@1+ (1,0) [0|1] "" Vector__XXX
 SG_ VCLEFT_a180_frontDoorLatchRehome m2 : 63|1@1+ (1,0) [0|1] "" Vector__XXX
 SG_ VCLEFT_a181_rearDoorLatchRehome m3 : 4|1@1+ (1,0) [0|1] "" Vector__XXX
 SG_ VCLEFT_a182_emergencyLatchRel m3 : 5|1@1+ (1,0) [0|1] "" Vector__XXX
 SG_ VCLEFT_a183_doorStateFactoryTest m3 : 6|1@1+ (1,0) [0|1] "" Vector__XXX
 SG_ VCLEFT_a185_summonAborted m3 : 8|1@1+ (1,0) [0|1] "" Vector__XXX
 SG_ VCLEFT_a186_latchReleaseFailedF m3 : 9|1@1+ (1,0) [0|1] "" Vector__XXX
 SG_ VCLEFT_a187_latchReleaseFailedR m3 : 10|1@1+ (1,0) [0|1] "" Vector__XXX
 SG_ VCLEFT_a188_latchUnableToRearmF m3 : 11|1@1+ (1,0) [0|1] "" Vector__XXX
 SG_ VCLEFT_a189_latchUnableToRearmR m3 : 12|1@1+ (1,0) [0|1] "" Vector__XXX
 SG_ VCLEFT_a190_eFuseMgmtVbatFused m3 : 13|1@1+ (1,0) [0|1] "" Vector__XXX
 SG_ VCLEFT_a191_TLCOvercurrent m3 : 14|1@1+ (1,0) [0|1] "" Vector__XXX
 SG_ VCLEFT_a192_blowerGeneralFault m3 : 15|1@1+ (1,0) [0|1] "" Vector__XXX
 SG_ VCLEFT_a193_blowerMIA m3 : 16|1@1+ (1,0) [0|1] "" Vector__XXX
 SG_ VCLEFT_a194_blowerUnidentified m3 : 17|1@1+ (1,0) [0|1] "" Vector__XXX
 SG_ VCLEFT_a195_blowerIdentification m3 : 18|1@1+ (1,0) [0|1] "" Vector__XXX
 SG_ VCLEFT_a196_VEHCANOverterminate m3 : 19|1@1+ (1,0) [0|1] "" Vector__XXX
 SG_ VCLEFT_a197_VEHCANUndertrminate m3 : 20|1@1+ (1,0) [0|1] "" Vector__XXX
 SG_ VCLEFT_a200_motorPhantomEncoder m3 : 23|1@1+ (1,0) [0|1] "" Vector__XXX
 SG_ VCLEFT_a201_motorDutyEncDisabl m3 : 24|1@1+ (1,0) [0|1] "" Vector__XXX
 SG_ VCLEFT_a202_epbmUnderIStatic m3 : 25|1@1+ (1,0) [0|1] "" Vector__XXX
 SG_ VCLEFT_a203_epbmOverIStatic m3 : 26|1@1+ (1,0) [0|1] "" Vector__XXX
 SG_ VCLEFT_a204_epbmUnderIDyn m3 : 27|1@1+ (1,0) [0|1] "" Vector__XXX
 SG_ VCLEFT_a205_epbmOverIDyn m3 : 28|1@1+ (1,0) [0|1] "" Vector__XXX
 SG_ VCLEFT_a206_epbWrongDirection m3 : 29|1@1+ (1,0) [0|1] "" Vector__XXX
 SG_ VCLEFT_a207_epbmEnableWrong m3 : 30|1@1+ (1,0) [0|1] "" Vector__XXX
 SG_ VCLEFT_a208_epbFaulted m3 : 31|1@1+ (1,0) [0|1] "" Vector__XXX
 SG_ VCLEFT_a209_epbStateMisTime m3 : 32|1@1+ (1,0) [0|1] "" Vector__XXX
 SG_ VCLEFT_a210_epbStateTime m3 : 33|1@1+ (1,0) [0|1] "" Vector__XXX
 SG_ VCLEFT_a211_epbmUnderIStaticNew m3 : 34|1@1+ (1,0) [0|1] "" Vector__XXX
 SG_ VCLEFT_a212_epbmOverIStaticNew m3 : 35|1@1+ (1,0) [0|1] "" Vector__XXX
 SG_ VCLEFT_a213_epbmUnderIDynNew m3 : 36|1@1+ (1,0) [0|1] "" Vector__XXX
 SG_ VCLEFT_a214_epbmOverIDynNew m3 : 37|1@1+ (1,0) [0|1] "" Vector__XXX
 SG_ VCLEFT_a215_currentDesyncWarning m3 : 38|1@1+ (1,0) [0|1] "" Vector__XXX
 SG_ VCLEFT_a216_SPI_MIA_debugData1 m3 : 39|1@1+ (1,0) [0|1] "" Vector__XXX
 SG_ VCLEFT_a217_SPI_MIA_debugData2 m3 : 40|1@1+ (1,0) [0|1] "" Vector__XXX
 SG_ VCLEFT_a218_motorDriverFault m3 : 41|1@1+ (1,0) [0|1] "" Vector__XXX
 SG_ VCLEFT_a219_motorCurrentDropout m3 : 42|1@1+ (1,0) [0|1] "" Vector__XXX
 SG_ VCLEFT_a224_seatEncStallTrack m3 : 47|1@1+ (1,0) [0|1] "" Vector__XXX
 SG_ VCLEFT_a225_seatEncStallBack m3 : 48|1@1+ (1,0) [0|1] "" Vector__XXX
 SG_ VCLEFT_a226_seatEncStallTilt m3 : 49|1@1+ (1,0) [0|1] "" Vector__XXX
 SG_ VCLEFT_a227_seatEncStallLift m3 : 50|1@1+ (1,0) [0|1] "" Vector__XXX
 SG_ VCLEFT_a228_seatEncOverTrack m3 : 51|1@1+ (1,0) [0|1] "" Vector__XXX
 SG_ VCLEFT_a229_seatEncOverBack m3 : 52|1@1+ (1,0) [0|1] "" Vector__XXX
 SG_ VCLEFT_a230_seatEncOverTilt m3 : 53|1@1+ (1,0) [0|1] "" Vector__XXX
 SG_ VCLEFT_a231_seatEncOverLift m3 : 54|1@1+ (1,0) [0|1] "" Vector__XXX
 SG_ VCLEFT_a232_seatCurrUnderTrack m3 : 55|1@1+ (1,0) [0|1] "" Vector__XXX
 SG_ VCLEFT_a233_seatCurrUnderBack m3 : 56|1@1+ (1,0) [0|1] "" Vector__XXX
 SG_ VCLEFT_a234_seatCurrUnderTilt m3 : 57|1@1+ (1,0) [0|1] "" Vector__XXX
 SG_ VCLEFT_a235_seatCurrUnderLift m3 : 58|1@1+ (1,0) [0|1] "" Vector__XXX
 SG_ VCLEFT_a236_lumbarOverPresA m3 : 59|1@1+ (1,0) [0|1] "" Vector__XXX
 SG_ VCLEFT_a237_lumbarOverPresB m3 : 60|1@1+ (1,0) [0|1] "" Vector__XXX
 SG_ VCLEFT_a238_lumbarValveMIA m3 : 61|1@1+ (1,0) [0|1] "" Vector__XXX
 SG_ VCLEFT_a239_seatHeatIFront m3 : 62|1@1+ (1,0) [0|1] "" Vector__XXX
 SG_ VCLEFT_a240_seatHeatShortFront m3 : 63|1@1+ (1,0) [0|1] "" Vector__XXX
 SG_ VCLEFT_a241_seatHeatMIAFront m4 : 4|1@1+ (1,0) [0|1] "" Vector__XXX
 SG_ VCLEFT_a242_seatHeatIRearL m4 : 5|1@1+ (1,0) [0|1] "" Vector__XXX
 SG_ VCLEFT_a243_seatHeatShortRearL m4 : 6|1@1+ (1,0) [0|1] "" Vector__XXX
 SG_ VCLEFT_a244_seatHeatMIARearL m4 : 7|1@1+ (1,0) [0|1] "" Vector__XXX
 SG_ VCLEFT_a245_seatHeatIRearC m4 : 8|1@1+ (1,0) [0|1] "" Vector__XXX
 SG_ VCLEFT_a246_seatHeatShortRearC m4 : 9|1@1+ (1,0) [0|1] "" Vector__XXX
 SG_ VCLEFT_a247_seatHeatMIARearC m4 : 10|1@1+ (1,0) [0|1] "" Vector__XXX
 SG_ VCLEFT_a248_seatHeatIRearR m4 : 11|1@1+ (1,0) [0|1] "" Vector__XXX
 SG_ VCLEFT_a249_seatHeatShortRearR m4 : 12|1@1+ (1,0) [0|1] "" Vector__XXX
 SG_ VCLEFT_a250_seatHeatMIARearR m4 : 13|1@1+ (1,0) [0|1] "" Vector__XXX
 SG_ VCLEFT_a251_seatUncalTrack m4 : 14|1@1+ (1,0) [0|1] "" Vector__XXX
 SG_ VCLEFT_a252_seatUncalBack m4 : 15|1@1+ (1,0) [0|1] "" Vector__XXX
 SG_ VCLEFT_a253_seatUncalTilt m4 : 16|1@1+ (1,0) [0|1] "" Vector__XXX
 SG_ VCLEFT_a254_seatUncalLift m4 : 17|1@1+ (1,0) [0|1] "" Vector__XXX
 SG_ VCLEFT_a257_USBMIA m4 : 20|1@1+ (1,0) [0|1] "" Vector__XXX
 SG_ VCLEFT_a259_latchDisarmDelayF m4 : 22|1@1+ (1,0) [0|1] "" Vector__XXX
 SG_ VCLEFT_a260_latchDisarmDelayR m4 : 23|1@1+ (1,0) [0|1] "" Vector__XXX
 SG_ VCLEFT_a261_emergencyLatchRelRea m4 : 24|1@1+ (1,0) [0|1] "" Vector__XXX
 SG_ VCLEFT_a263_seatTrackStallDebug m4 : 26|1@1+ (1,0) [0|1] "" Vector__XXX
 SG_ VCLEFT_a264_seatBackStallDebug m4 : 27|1@1+ (1,0) [0|1] "" Vector__XXX
 SG_ VCLEFT_a265_seatTiltStallDebug m4 : 28|1@1+ (1,0) [0|1] "" Vector__XXX
 SG_ VCLEFT_a266_seatLiftStallDebug m4 : 29|1@1+ (1,0) [0|1] "" Vector__XXX
 SG_ VCLEFT_a267_seatTrackHCEncStlDbg m4 : 30|1@1+ (1,0) [0|1] "" Vector__XXX
 SG_ VCLEFT_a268_seatBackHCEncStlDbg m4 : 31|1@1+ (1,0) [0|1] "" Vector__XXX
 SG_ VCLEFT_a269_seatTiltHCEncStlDbg m4 : 32|1@1+ (1,0) [0|1] "" Vector__XXX
 SG_ VCLEFT_a270_seatLiftHCEncStlDbg m4 : 33|1@1+ (1,0) [0|1] "" Vector__XXX
 SG_ VCLEFT_a272_vhclPwrStateMsmtch m4 : 35|1@1+ (1,0) [0|1] "" Vector__XXX
 SG_ VCLEFT_a273_handleStuckActiveF m4 : 36|1@1+ (1,0) [0|1] "" Vector__XXX
 SG_ VCLEFT_a274_handleStuckActiveR m4 : 37|1@1+ (1,0) [0|1] "" Vector__XXX
 SG_ VCLEFT_a275_leftTurnLightFault m4 : 38|1@1+ (1,0) [0|1] "" Vector__XXX
 SG_ VCLEFT_a276_mirrorDebug m4 : 39|1@1+ (1,0) [0|1] "" Vector__XXX
 SG_ VCLEFT_a277_BLELeftUnderVoltage m4 : 40|1@1+ (1,0) [0|1] "" Vector__XXX
 SG_ VCLEFT_a278_BLERearUnderVoltage m4 : 41|1@1+ (1,0) [0|1] "" Vector__XXX
 SG_ VCLEFT_a279_VCSECUnderVoltage m4 : 42|1@1+ (1,0) [0|1] "" Vector__XXX
 SG_ VCLEFT_a280_latchDidNotDisarmF m4 : 43|1@1+ (1,0) [0|1] "" Vector__XXX
 SG_ VCLEFT_a281_latchDidNotDisarmR m4 : 44|1@1+ (1,0) [0|1] "" Vector__XXX
 SG_ VCLEFT_a282_latchUnexpectedArmF m4 : 45|1@1+ (1,0) [0|1] "" Vector__XXX
 SG_ VCLEFT_a283_latchUnexpectedArmR m4 : 46|1@1+ (1,0) [0|1] "" Vector__XXX
 SG_ VCLEFT_a284_blowerFbkSanity m4 : 47|1@1+ (1,0) [0|1] "" Vector__XXX
 SG_ VCLEFT_a285_blowerChipComms m4 : 48|1@1+ (1,0) [0|1] "" Vector__XXX
 SG_ VCLEFT_a286_windowSpeedInvalidF m4 : 49|1@1+ (1,0) [0|1] "" Vector__XXX
 SG_ VCLEFT_a287_windowSpeedInvalidR m4 : 50|1@1+ (1,0) [0|1] "" Vector__XXX
 SG_ VCLEFT_a288_handlePWMPeriodF m4 : 51|1@1+ (1,0) [0|1] "" Vector__XXX
 SG_ VCLEFT_a289_handlePWMPeriodR m4 : 52|1@1+ (1,0) [0|1] "" Vector__XXX
 SG_ VCLEFT_a290_occupancyFaultedFron m4 : 53|1@1+ (1,0) [0|1] "" Vector__XXX
 SG_ VCLEFT_a291_buckleFaultedFront m4 : 54|1@1+ (1,0) [0|1] "" Vector__XXX
 SG_ VCLEFT_a292_occupancyFaultedRear m4 : 55|1@1+ (1,0) [0|1] "" Vector__XXX
 SG_ VCLEFT_a293_occupancyFaultedRear m4 : 56|1@1+ (1,0) [0|1] "" Vector__XXX
 SG_ VCLEFT_a294_occupancyFaultedRear m4 : 57|1@1+ (1,0) [0|1] "" Vector__XXX
 SG_ VCLEFT_a295_buckleFaultedRearL m4 : 58|1@1+ (1,0) [0|1] "" Vector__XXX
 SG_ VCLEFT_a296_buckleFaultedRearC m4 : 59|1@1+ (1,0) [0|1] "" Vector__XXX
 SG_ VCLEFT_a297_seatBelowMinPumpTmp m4 : 60|1@1+ (1,0) [0|1] "" Vector__XXX
 SG_ VCLEFT_a299_swcMIA m4 : 62|1@1+ (1,0) [0|1] "" Vector__XXX
 SG_ VCLEFT_a300_swcUnderVoltage m4 : 63|1@1+ (1,0) [0|1] "" Vector__XXX
 SG_ VCLEFT_a301_swcOverVoltage m5 : 4|1@1+ (1,0) [0|1] "" Vector__XXX
 SG_ VCLEFT_a302_blowerGeneralFault m5 : 5|1@1+ (1,0) [0|1] "" Vector__XXX
 SG_ VCLEFT_a303_eFuseMgmtWindowLift m5 : 6|1@1+ (1,0) [0|1] "" Vector__XXX
 SG_ VCLEFT_a304_frontIntHandleShorte m5 : 7|1@1+ (1,0) [0|1] "" Vector__XXX
 SG_ VCLEFT_a305_rearIntHandleShorted m5 : 8|1@1+ (1,0) [0|1] "" Vector__XXX
 SG_ VCLEFT_a306_handleDisconnectedF m5 : 9|1@1+ (1,0) [0|1] "" Vector__XXX
 SG_ VCLEFT_a307_handleDisconnectedR m5 : 10|1@1+ (1,0) [0|1] "" Vector__XXX
 SG_ VCLEFT_a308_sirenMIA m5 : 11|1@1+ (1,0) [0|1] "" Vector__XXX
 SG_ VCLEFT_a309_brakeSwitchFaulted m5 : 12|1@1+ (1,0) [0|1] "" Vector__XXX
 SG_ VCLEFT_a310_mirrorFoldStall m5 : 13|1@1+ (1,0) [0|1] "" Vector__XXX
 SG_ VCLEFT_a311_leftBrakeLightFault m5 : 14|1@1+ (1,0) [0|1] "" Vector__XXX
 SG_ VCLEFT_a312_leftTailLightFault m5 : 15|1@1+ (1,0) [0|1] "" Vector__XXX
 SG_ VCLEFT_a313_leftFootwellLightFau m5 : 16|1@1+ (1,0) [0|1] "" Vector__XXX
 SG_ VCLEFT_a314_leftMapPocketLightFa m5 : 17|1@1+ (1,0) [0|1] "" Vector__XXX
 SG_ VCLEFT_a315_leftInteriorTrunkLig m5 : 18|1@1+ (1,0) [0|1] "" Vector__XXX
 SG_ VCLEFT_a316_mirrorPrematureFoldS m5 : 19|1@1+ (1,0) [0|1] "" Vector__XXX
 SG_ VCLEFT_a317_epbmLimpModeEnabled m5 : 20|1@1+ (1,0) [0|1] "" Vector__XXX
 SG_ VCLEFT_a318_trailerIncorrectConf m5 : 21|1@1+ (1,0) [0|1] "" Vector__XXX
 SG_ VCLEFT_a319_brakePressPrimaryInp m5 : 22|1@1+ (1,0) [0|1] "" Vector__XXX
 SG_ VCLEFT_a320_windowReportCrackedA m5 : 23|1@1+ (1,0) [0|1] "" Vector__XXX
 SG_ VCLEFT_a321_windowRezeroedDebugF m5 : 24|1@1+ (1,0) [0|1] "" Vector__XXX
 SG_ VCLEFT_a322_windowRezeroedDebugR m5 : 25|1@1+ (1,0) [0|1] "" Vector__XXX
 SG_ VCLEFT_a323_mirrorCalibrated m5 : 26|1@1+ (1,0) [0|1] "" Vector__XXX
 SG_ VCLEFT_a324_mirrorHeatFault m5 : 27|1@1+ (1,0) [0|1] "" Vector__XXX
 SG_ VCLEFT_a325_hghtSnsrUnplgdFL m5 : 28|1@1+ (1,0) [0|1] "" Vector__XXX
 SG_ VCLEFT_a326_hghtSnsrUnplgdRL m5 : 29|1@1+ (1,0) [0|1] "" Vector__XXX
 SG_ VCLEFT_a327_hghtSnsrFaultFL m5 : 30|1@1+ (1,0) [0|1] "" Vector__XXX
 SG_ VCLEFT_a328_hghtSnsrFaultRL m5 : 31|1@1+ (1,0) [0|1] "" Vector__XXX
 SG_ VCLEFT_a329_noRideHeightCalib m5 : 32|1@1+ (1,0) [0|1] "" Vector__XXX
 SG_ VCLEFT_a330_shortDropFailedF m5 : 33|1@1+ (1,0) [0|1] "" Vector__XXX
 SG_ VCLEFT_a331_shortDropFailedR m5 : 34|1@1+ (1,0) [0|1] "" Vector__XXX
 SG_ VCLEFT_a332_intrusionSensorMIA m5 : 35|1@1+ (1,0) [0|1] "" Vector__XXX
 SG_ VCLEFT_a333_overheadConsoleMIA m5 : 36|1@1+ (1,0) [0|1] "" Vector__XXX
 SG_ VCLEFT_a334_overheadConsoleInter m5 : 37|1@1+ (1,0) [0|1] "" Vector__XXX
 SG_ VCLEFT_a335_intrusionSensorInter m5 : 38|1@1+ (1,0) [0|1] "" Vector__XXX
 SG_ VCLEFT_a336_windowDropRevThermal m5 : 39|1@1+ (1,0) [0|1] "" Vector__XXX
 SG_ VCLEFT_a337_windowDropRevThermal m5 : 40|1@1+ (1,0) [0|1] "" Vector__XXX
 SG_ VCLEFT_a338_trailerLightControll m5 : 41|1@1+ (1,0) [0|1] "" Vector__XXX
 SG_ VCLEFT_a339_trailerLeftTurnLight m5 : 42|1@1+ (1,0) [0|1] "" Vector__XXX
 SG_ VCLEFT_a340_trailerRightTurnLigh m5 : 43|1@1+ (1,0) [0|1] "" Vector__XXX
 SG_ VCLEFT_a341_trailerLightFault m5 : 44|1@1+ (1,0) [0|1] "" Vector__XXX
 SG_ VCLEFT_a342_trailerLightControll m5 : 45|1@1+ (1,0) [0|1] "" Vector__XXX
 SG_ VCLEFT_a345_chargePortPowerCycli m5 : 48|1@1+ (1,0) [0|1] "" Vector__XXX
 SG_ VCLEFT_a346_eFuseMgmtVbatFused2 m5 : 49|1@1+ (1,0) [0|1] "" Vector__XXX
 SG_ VCLEFT_a347_nonContMonitorCleare m5 : 50|1@1+ (1,0) [0|1] "" Vector__XXX
 SG_ VCLEFT_a348_CPSleepOvercurrent m5 : 51|1@1+ (1,0) [0|1] "" Vector__XXX
 SG_ VCLEFT_a349_CPSleepUndervoltage m5 : 52|1@1+ (1,0) [0|1] "" Vector__XXX
 SG_ VCLEFT_a350_ensOutOfRange m5 : 53|1@1+ (1,0) [0|1] "" Vector__XXX
 SG_ VCLEFT_a351_debugLiftgateCurrent m5 : 54|1@1+ (1,0) [0|1] "" Vector__XXX
 SG_ VCLEFT_a352_liftgateClosingLatch m5 : 55|1@1+ (1,0) [0|1] "" Vector__XXX
 SG_ VCLEFT_a353_eFuseMgmtSteeringCol m5 : 56|1@1+ (1,0) [0|1] "" Vector__XXX
 SG_ VCLEFT_a354_eFuseMgmtLiftGate m5 : 57|1@1+ (1,0) [0|1] "" Vector__XXX
 SG_ VCLEFT_a355_liftgateUnexpectedSt m5 : 58|1@1+ (1,0) [0|1] "" Vector__XXX
 SG_ VCLEFT_a356_liftgateFactoryTest m5 : 59|1@1+ (1,0) [0|1] "" Vector__XXX
 SG_ VCLEFT_a357_liftgateUncalibrated m5 : 60|1@1+ (1,0) [0|1] "" Vector__XXX
 SG_ VCLEFT_a358_debugLiftgateCurrent m5 : 61|1@1+ (1,0) [0|1] "" Vector__XXX
 SG_ VCLEFT_a359_liftgateLatchExitNoP m5 : 62|1@1+ (1,0) [0|1] "" Vector__XXX
 SG_ VCLEFT_a360_detectedStationaryWh m5 : 63|1@1+ (1,0) [0|1] "" Vector__XXX
 SG_ VCLEFT_a361_stationaryThresholds m6 : 4|1@1+ (1,0) [0|1] "" Vector__XXX
 SG_ VCLEFT_a362_movingThresholdsInco m6 : 5|1@1+ (1,0) [0|1] "" Vector__XXX
 SG_ VCLEFT_a363_liftgateOpenAngleSet m6 : 6|1@1+ (1,0) [0|1] "" Vector__XXX
 SG_ VCLEFT_a365_pitchUnlatchDisabled m6 : 8|1@1+ (1,0) [0|1] "" Vector__XXX
 SG_ VCLEFT_a366_liftgateLatchEntryDB m6 : 9|1@1+ (1,0) [0|1] "" Vector__XXX
 SG_ VCLEFT_a370_seat2RowPitchUnlatch m6 : 13|1@1+ (1,0) [0|1] "" Vector__XXX
 SG_ VCLEFT_a371_seat2RowTrackUnlatch m6 : 14|1@1+ (1,0) [0|1] "" Vector__XXX
 SG_ VCLEFT_a372_seat2RowBackrestUnla m6 : 15|1@1+ (1,0) [0|1] "" Vector__XXX
 SG_ VCLEFT_a373_windowSwOpenReqInDog m6 : 16|1@1+ (1,0) [0|1] "" Vector__XXX
 SG_ VCLEFT_a374_trailerLightFaultMod m6 : 17|1@1+ (1,0) [0|1] "" Vector__XXX
 SG_ VCLEFT_a375_windowPinchOverrideN m6 : 18|1@1+ (1,0) [0|1] "" Vector__XXX
 SG_ VCLEFT_a376_seat2RowBridgeCurren m6 : 19|1@1+ (1,0) [0|1] "" Vector__XXX
 SG_ VCLEFT_a380_steerColThermalLimit m6 : 23|1@1+ (1,0) [0|1] "" Vector__XXX
 SG_ VCLEFT_a381_pitchEstimation1 m6 : 24|1@1+ (1,0) [0|1] "" Vector__XXX
 SG_ VCLEFT_a382_pitchEstimation2 m6 : 25|1@1+ (1,0) [0|1] "" Vector__XXX
 SG_ VCLEFT_a383_steerColInOutMotorSt m6 : 26|1@1+ (1,0) [0|1] "" Vector__XXX
 SG_ VCLEFT_a384_steerColUpDownMotorS m6 : 27|1@1+ (1,0) [0|1] "" Vector__XXX
 SG_ VCLEFT_a385_steerColInOutMotorUn m6 : 28|1@1+ (1,0) [0|1] "" Vector__XXX
 SG_ VCLEFT_a386_steerColUpDownMotorU m6 : 29|1@1+ (1,0) [0|1] "" Vector__XXX
 SG_ VCLEFT_a387_steerColInOutMotorEn m6 : 30|1@1+ (1,0) [0|1] "" Vector__XXX
 SG_ VCLEFT_a388_steerColUpDownMotorE m6 : 31|1@1+ (1,0) [0|1] "" Vector__XXX
 SG_ VCLEFT_a389_steerColInOutEncoder m6 : 32|1@1+ (1,0) [0|1] "" Vector__XXX
 SG_ VCLEFT_a390_steerColUpDownEncode m6 : 33|1@1+ (1,0) [0|1] "" Vector__XXX
 SG_ VCLEFT_a391_pitchEstimationImpla m6 : 34|1@1+ (1,0) [0|1] "" Vector__XXX
 SG_ VCLEFT_a392_pitchEstimationGPSIm m6 : 35|1@1+ (1,0) [0|1] "" Vector__XXX
 SG_ VCLEFT_a393_pitchEstimationNoGPS m6 : 36|1@1+ (1,0) [0|1] "" Vector__XXX
 SG_ VCLEFT_a394_swsTouchTooNegativeD m6 : 37|1@1+ (1,0) [0|1] "" Vector__XXX
 SG_ VCLEFT_a395_swsTouchAdcCheckFail m6 : 38|1@1+ (1,0) [0|1] "" Vector__XXX
 SG_ VCLEFT_a396_swsTouchStuckFault m6 : 39|1@1+ (1,0) [0|1] "" Vector__XXX
 SG_ VCLEFT_a397_swsTouchOutOfRangeFa m6 : 40|1@1+ (1,0) [0|1] "" Vector__XXX
 SG_ VCLEFT_a398_swsTouchNvmFault m6 : 41|1@1+ (1,0) [0|1] "" Vector__XXX
 SG_ VCLEFT_a399_swsTouchNoisyBaselin m6 : 42|1@1+ (1,0) [0|1] "" Vector__XXX
 SG_ VCLEFT_a400_swsTouchDebouncedPro m6 : 43|1@1+ (1,0) [0|1] "" Vector__XXX
 SG_ VCLEFT_a401_swsForceTestPatternV m6 : 44|1@1+ (1,0) [0|1] "" Vector__XXX
 SG_ VCLEFT_a402_swsForceOutOfRange m6 : 45|1@1+ (1,0) [0|1] "" Vector__XXX
 SG_ VCLEFT_a403_swsForceAdcCheckFail m6 : 46|1@1+ (1,0) [0|1] "" Vector__XXX
 SG_ VCLEFT_a404_swsForceI2cError m6 : 47|1@1+ (1,0) [0|1] "" Vector__XXX
 SG_ VCLEFT_a405_swsForceCalibrationF m6 : 48|1@1+ (1,0) [0|1] "" Vector__XXX
 SG_ VCLEFT_a406_swsForceParametersFa m6 : 49|1@1+ (1,0) [0|1] "" Vector__XXX
 SG_ VCLEFT_a407_swsForceNvmFault m6 : 50|1@1+ (1,0) [0|1] "" Vector__XXX
 SG_ VCLEFT_a408_swsForceTouchSensorF m6 : 51|1@1+ (1,0) [0|1] "" Vector__XXX
 SG_ VCLEFT_a409_swsScrollWheelPushFa m6 : 52|1@1+ (1,0) [0|1] "" Vector__XXX
 SG_ VCLEFT_a410_swsScrollWheelTiltFa m6 : 53|1@1+ (1,0) [0|1] "" Vector__XXX
 SG_ VCLEFT_a411_swsScrollWheelScroll m6 : 54|1@1+ (1,0) [0|1] "" Vector__XXX
 SG_ VCLEFT_a412_leftBrakeTailLightFa m6 : 55|1@1+ (1,0) [0|1] "" Vector__XXX
 SG_ VCLEFT_a414_swsHapticMotorFault m6 : 57|1@1+ (1,0) [0|1] "" Vector__XXX
 SG_ VCLEFT_a415_swsMiscFault m6 : 58|1@1+ (1,0) [0|1] "" Vector__XXX
 SG_ VCLEFT_a416_fohmTouchAdcCheckFai m6 : 59|1@1+ (1,0) [0|1] "" Vector__XXX
 SG_ VCLEFT_a417_fohmTouchOutOfRangeF m6 : 60|1@1+ (1,0) [0|1] "" Vector__XXX
 SG_ VCLEFT_a418_fohmTouchVarianceFai m6 : 61|1@1+ (1,0) [0|1] "" Vector__XXX
 SG_ VCLEFT_a419_fohmTouchStuck m6 : 62|1@1+ (1,0) [0|1] "" Vector__XXX
 SG_ VCLEFT_a420_fohmTouchSensorsImpl m6 : 63|1@1+ (1,0) [0|1] "" Vector__XXX
 SG_ VCLEFT_a421_fohmForceOutOfRangeF m7 : 4|1@1+ (1,0) [0|1] "" Vector__XXX
 SG_ VCLEFT_a423_fohmForceI2cError m7 : 6|1@1+ (1,0) [0|1] "" Vector__XXX
 SG_ VCLEFT_a424_fohmAmberLEDFault m7 : 7|1@1+ (1,0) [0|1] "" Vector__XXX
 SG_ VCLEFT_a425_fohmVanityPowerSuppl m7 : 8|1@1+ (1,0) [0|1] "" Vector__XXX
 SG_ VCLEFT_a426_seatAbuseMotorWarn m7 : 9|1@1+ (1,0) [0|1] "" Vector__XXX
 SG_ VCLEFT_a427_seatAbuseMotorStop m7 : 10|1@1+ (1,0) [0|1] "" Vector__XXX
 SG_ VCLEFT_a428_seatAbuseBufferWarn m7 : 11|1@1+ (1,0) [0|1] "" Vector__XXX
 SG_ VCLEFT_a429_seatAbuseBufferFull m7 : 12|1@1+ (1,0) [0|1] "" Vector__XXX
 SG_ VCLEFT_a430_fohmRearDomeLightPow m7 : 13|1@1+ (1,0) [0|1] "" Vector__XXX
 SG_ VCLEFT_a431_fohmVbatFault m7 : 14|1@1+ (1,0) [0|1] "" Vector__XXX
 SG_ VCLEFT_a432_fohmMiscFault m7 : 15|1@1+ (1,0) [0|1] "" Vector__XXX
 SG_ VCLEFT_a433_fohmForceCalibration m7 : 16|1@1+ (1,0) [0|1] "" Vector__XXX
 SG_ VCLEFT_a434_swsScrollWheelPushDa m7 : 17|1@1+ (1,0) [0|1] "" Vector__XXX
 SG_ VCLEFT_a435_swsNoReasonTouchFaul m7 : 18|1@1+ (1,0) [0|1] "" Vector__XXX
 SG_ VCLEFT_a436_swsNoReasonForceFaul m7 : 19|1@1+ (1,0) [0|1] "" Vector__XXX
 SG_ VCLEFT_a437_hvacRearLeftVertical m7 : 20|1@1+ (1,0) [0|1] "" Vector__XXX
 SG_ VCLEFT_a438_hvacRearLeftLateralD m7 : 21|1@1+ (1,0) [0|1] "" Vector__XXX
 SG_ VCLEFT_a439_hvacRearRightVertica m7 : 22|1@1+ (1,0) [0|1] "" Vector__XXX
 SG_ VCLEFT_a440_hvacRearRightLateral m7 : 23|1@1+ (1,0) [0|1] "" Vector__XXX
 SG_ VCLEFT_a441_prndMIA m7 : 24|1@1+ (1,0) [0|1] "" Vector__XXX
 SG_ VCLEFT_a442_swsLongTouchEvent m7 : 25|1@1+ (1,0) [0|1] "" Vector__XXX
 SG_ VCLEFT_a444_drv8703Fault m7 : 27|1@1+ (1,0) [0|1] "" Vector__XXX
 SG_ VCLEFT_a445_drv8703SpiFaultDBG m7 : 28|1@1+ (1,0) [0|1] "" Vector__XXX
 SG_ VCLEFT_a446_trailerAuxReversePow m7 : 29|1@1+ (1,0) [0|1] "" Vector__XXX
 SG_ VCLEFT_a447_steeringColInOutEnds m7 : 30|1@1+ (1,0) [0|1] "" Vector__XXX
 SG_ VCLEFT_a448_steeringColUpDownEnd m7 : 31|1@1+ (1,0) [0|1] "" Vector__XXX
 SG_ VCLEFT_a451_wirelessChargerMIA m7 : 34|1@1+ (1,0) [0|1] "" Vector__XXX
 SG_ VCLEFT_a453_liftgatePinchDetecte m7 : 36|1@1+ (1,0) [0|1] "" Vector__XXX
 SG_ VCLEFT_a454_wirelessChargerFault m7 : 37|1@1+ (1,0) [0|1] "" Vector__XXX
 SG_ VCLEFT_a455_liftgateUnexpectedSh m7 : 38|1@1+ (1,0) [0|1] "" Vector__XXX
 SG_ VCLEFT_a460_etcDebug m7 : 43|1@1+ (1,0) [0|1] "" Vector__XXX
 SG_ VCLEFT_a466_hvac2RLeftAirwaveVer m7 : 49|1@1+ (1,0) [0|1] "" Vector__XXX
 SG_ VCLEFT_a467_hvac2RLeftAirwaveVer m7 : 50|1@1+ (1,0) [0|1] "" Vector__XXX
 SG_ VCLEFT_a468_hvac2RLeftAirwaveVer m7 : 51|1@1+ (1,0) [0|1] "" Vector__XXX
 SG_ VCLEFT_a469_hvac2RLeftAirwaveLat m7 : 52|1@1+ (1,0) [0|1] "" Vector__XXX
 SG_ VCLEFT_a470_hvac2RLeftAirwaveLat m7 : 53|1@1+ (1,0) [0|1] "" Vector__XXX
 SG_ VCLEFT_a471_hvac2RLeftAirwaveLat m7 : 54|1@1+ (1,0) [0|1] "" Vector__XXX
 SG_ VCLEFT_a472_hvac2RRightAirwaveVe m7 : 55|1@1+ (1,0) [0|1] "" Vector__XXX
 SG_ VCLEFT_a473_hvac2RRightAirwaveVe m7 : 56|1@1+ (1,0) [0|1] "" Vector__XXX
 SG_ VCLEFT_a474_hvac2RRightAirwaveVe m7 : 57|1@1+ (1,0) [0|1] "" Vector__XXX
 SG_ VCLEFT_a475_hvac2RRightAirwaveLa m7 : 58|1@1+ (1,0) [0|1] "" Vector__XXX
 SG_ VCLEFT_a476_hvac2RRightAirwaveLa m7 : 59|1@1+ (1,0) [0|1] "" Vector__XXX
 SG_ VCLEFT_a477_hvac2RRightAirwaveLa m7 : 60|1@1+ (1,0) [0|1] "" Vector__XXX
 SG_ VCLEFT_a478_BPillarCameraHeaterF m7 : 61|1@1+ (1,0) [0|1] "" Vector__XXX
 SG_ VCLEFT_a480_vnf1048Fault m7 : 63|1@1+ (1,0) [0|1] "" Vector__XXX
 SG_ VCLEFT_a481_vnf1048SelfTestFailu m8 : 4|1@1+ (1,0) [0|1] "" Vector__XXX
 SG_ VCLEFT_a482_NCV77XXFault m8 : 5|1@1+ (1,0) [0|1] "" Vector__XXX
 SG_ VCLEFT_a490_vehicleOccupiedOnOTA m8 : 13|1@1+ (1,0) [0|1] "" Vector__XXX
 SG_ VCLEFT_a498_canAuthenticationFai m8 : 21|1@1+ (1,0) [0|1] "" Vector__XXX
 SG_ VCLEFT_a499_epbmInvalidateCdp m8 : 22|1@1+ (1,0) [0|1] "" Vector__XXX
 SG_ VCLEFT_a500_eFuseASICStateMismat m8 : 23|1@1+ (1,0) [0|1] "" Vector__XXX
 SG_ VCLEFT_a501_vnf1048Configuration m8 : 24|1@1+ (1,0) [0|1] "" Vector__XXX
 SG_ VCLEFT_a520_configMismatch m8 : 43|1@1+ (1,0) [0|1] "" Vector__XXX
 SG_ VCLEFT_a521_seatHeatPadUnexpecte m8 : 44|1@1+ (1,0) [0|1] "" Vector__XXX
 SG_ VCLEFT_a522_trailerLightUnexpect m8 : 45|1@1+ (1,0) [0|1] "" Vector__XXX
 SG_ VCLEFT_a523_eFuseThresholdsIncor m8 : 46|1@1+ (1,0) [0|1] "" Vector__XXX
 SG_ VCLEFT_a525_LVBatterySWMisconfig m8 : 48|1@1+ (1,0) [0|1] "" Vector__XXX
 SG_ VCLEFT_a526_pcbaOverTemperature m8 : 49|1@1+ (1,0) [0|1] "" Vector__XXX
 SG_ VCLEFT_a527_continuousFeedUnexpe m8 : 50|1@1+ (1,0) [0|1] "" Vector__XXX
 SG_ VCLEFT_a528_unableToRunStuckOnTe m8 : 51|1@1+ (1,0) [0|1] "" Vector__XXX
 SG_ VCLEFT_a536_trunkFoldFlatSwitchF m8 : 59|1@1+ (1,0) [0|1] "" Vector__XXX
 SG_ VCLEFT_a545_LVBatteryTypeUnknown m9 : 8|1@1+ (1,0) [0|1] "" Vector__XXX
 SG_ VCLEFT_a546_mirrorFoldTypeChange m9 : 9|1@1+ (1,0) [0|1] "" Vector__XXX
 SG_ VCLEFT_a550_ambientTempDelta m9 : 13|1@1+ (1,0) [0|1] "" Vector__XXX
 SG_ VCLEFT_a551_interiorDoorRequestI m9 : 14|1@1+ (1,0) [0|1] "" Vector__XXX
 SG_ VCLEFT_a554_RCM2_MIA m9 : 17|1@1+ (1,0) [0|1] "" Vector__XXX
 SG_ VCLEFT_a555_steeringWheelHeaterC m9 : 18|1@1+ (1,0) [0|1] "" Vector__XXX
 SG_ VCLEFT_a560_2RowSeatUncalibrated m9 : 23|1@1+ (1,0) [0|1] "" Vector__XXX
 SG_ VCLEFT_a561_2RowSeatPositionNons m9 : 24|1@1+ (1,0) [0|1] "" Vector__XXX
 SG_ VCLEFT_a562_2RowSeatAbsPosOffset m9 : 25|1@1+ (1,0) [0|1] "" Vector__XXX
 SG_ VCLEFT_a563_2RowSeatObstacleDete m9 : 26|1@1+ (1,0) [0|1] "" Vector__XXX
 SG_ VCLEFT_a564_2RowSeatTempHigh m9 : 27|1@1+ (1,0) [0|1] "" Vector__XXX
 SG_ VCLEFT_a565_2RowSeatAbsPosSensor m9 : 28|1@1+ (1,0) [0|1] "" Vector__XXX
 SG_ VCLEFT_a566_2RowSeatStatsFromLas m9 : 29|1@1+ (1,0) [0|1] "" Vector__XXX
 SG_ VCLEFT_a567_2RowSeatRequestWhile m9 : 30|1@1+ (1,0) [0|1] "" Vector__XXX
 SG_ VCLEFT_a568_2RowSeatClashAvoidan m9 : 31|1@1+ (1,0) [0|1] "" Vector__XXX
 SG_ VCLEFT_a569_2RowSeatOverfolded m9 : 32|1@1+ (1,0) [0|1] "" Vector__XXX
 SG_ VCLEFT_a570_seatHeatDisabledF m9 : 33|1@1+ (1,0) [0|1] "" Vector__XXX
 SG_ VCLEFT_a571_seatHeatDisabledRear m9 : 34|1@1+ (1,0) [0|1] "" Vector__XXX
 SG_ VCLEFT_a572_seatHeatDisabledRear m9 : 35|1@1+ (1,0) [0|1] "" Vector__XXX
 SG_ VCLEFT_a573_seatHeatDisabledRear m9 : 36|1@1+ (1,0) [0|1] "" Vector__XXX
 SG_ VCLEFT_a576_liftgateStrutPositio m9 : 39|1@1+ (1,0) [0|1] "" Vector__XXX
 SG_ VCLEFT_a577_bsiHardwareIssue m9 : 40|1@1+ (1,0) [0|1] "" Vector__XXX
 SG_ VCLEFT_a578_RGBLightFault m9 : 41|1@1+ (1,0) [0|1] "" Vector__XXX
 SG_ VCLEFT_a579_leftSteeringWheelCtr m9 : 42|1@1+ (1,0) [0|1] "" Vector__XXX
 SG_ VCLEFT_a580_rightSteeringWheelCt m9 : 43|1@1+ (1,0) [0|1] "" Vector__XXX
 SG_ VCLEFT_a581_reverseLightFault m9 : 44|1@1+ (1,0) [0|1] "" Vector__XXX
 SG_ VCLEFT_a583_doorRemoteUnlatchedF m9 : 46|1@1+ (1,0) [0|1] "" Vector__XXX
 SG_ VCLEFT_a584_doorRemoteUnlatchedR m9 : 47|1@1+ (1,0) [0|1] "" Vector__XXX
 SG_ VCLEFT_a585_doorRemoteUnlatchFai m9 : 48|1@1+ (1,0) [0|1] "" Vector__XXX
 SG_ VCLEFT_a586_doorRemoteUnlatchFai m9 : 49|1@1+ (1,0) [0|1] "" Vector__XXX
 SG_ VCLEFT_a599_LVBatteryTypeUnsuppo m9 : 62|1@1+ (1,0) [0|1] "" Vector__XXX
 SG_ VCLEFT_a617_APP_MIA m10 : 20|1@1+ (1,0) [0|1] "" Vector__XXX

BO_ 258 VCLEFT_doorStatus: 8 VCLEFT
 SG_ VCLEFT_doorClosureStatusFront : 0|4@1+ (1,0) [1|15] "" Vector__XXX
 SG_ VCLEFT_doorClosureStatusRear : 4|4@1+ (1,0) [1|15] "" Vector__XXX
 SG_ VCLEFT_frontLatchSwitch : 8|1@1+ (1,0) [0|1] "" Vector__XXX
 SG_ VCLEFT_rearLatchSwitch : 9|1@1+ (1,0) [0|1] "" Vector__XXX
 SG_ VCLEFT_frontHandlePulled : 10|1@1+ (1,0) [0|1] "" Vector__XXX
 SG_ VCLEFT_rearHandlePulled : 11|1@1+ (1,0) [0|1] "" Vector__XXX
 SG_ VCLEFT_frontRelActuatorSwitch : 12|1@1+ (1,0) [0|1] "" Vector__XXX
 SG_ VCLEFT_rearRelActuatorSwitch : 13|1@1+ (1,0) [0|1] "" Vector__XXX
 SG_ VCLEFT_frontLatchStatus : 14|4@1+ (1,0) [1|15] "" Vector__XXX
 SG_ VCLEFT_rearLatchStatus : 18|4@1+ (1,0) [1|15] "" Vector__XXX
 SG_ VCLEFT_lastDoorReqSourceFront : 22|3@1+ (1,0) [0|7] "" Vector__XXX
 SG_ VCLEFT_lastDoorReqSourceRear : 25|3@1+ (1,0) [0|7] "" Vector__XXX
 SG_ VCLEFT_frontIntSwitchPressed : 31|1@1+ (1,0) [0|1] "" Vector__XXX
 SG_ VCLEFT_rearIntSwitchPressed : 32|1@1+ (1,0) [0|1] "" Vector__XXX
 SG_ VCLEFT_mirrorTiltXPosition : 33|8@1+ (0.02,0) [0|5] "V" Vector__XXX
 SG_ VCLEFT_mirrorTiltYPosition : 41|8@1+ (0.02,0) [0|5] "V" Vector__XXX
 SG_ VCLEFT_mirrorState : 49|3@1+ (1,0) [0|7] "" Vector__XXX
 SG_ VCLEFT_mirrorFoldState : 52|3@1+ (1,0) [0|7] "" Vector__XXX
 SG_ VCLEFT_mirrorRecallState : 55|3@1+ (1,0) [0|7] "" Vector__XXX
 SG_ VCLEFT_mirrorHeatState : 58|3@1+ (1,0) [1|7] "" Vector__XXX
 SG_ VCLEFT_rearHandlePulledPersist : 61|1@1+ (1,0) [0|1] "" Vector__XXX
 SG_ VCLEFT_frontHandlePulledPersist : 62|1@1+ (1,0) [0|1] "" Vector__XXX
 SG_ VCLEFT_mirrorDipped : 63|1@1+ (1,0) [0|1] "" Vector__XXX

BO_ 626 VCLEFT_epbmDebug: 8 VCLEFT
 SG_ VCLEFT_epbmDebugIndex M : 0|1@1+ (1,0) [0|1] "" Vector__XXX
 SG_ VCLEFT_epbmCaliperState m0 : 1|3@1+ (1,0) [0|7] "" Vector__XXX
 SG_ VCLEFT_epbmMotorEnabled m0 : 4|1@1+ (1,0) [0|1] "" Vector__XXX
 SG_ VCLEFT_epbMotorCurrent m0 : 5|11@1+ (0.01,0) [0|20.47] "A" Vector__XXX
 SG_ VCLEFT_epbmApplyVoltage m0 : 16|11@1+ (0.01,0) [0|20.47] "A" Vector__XXX
 SG_ VCLEFT_epbmReleaseVoltage m0 : 27|11@1+ (0.01,0) [0|20.47] "A" Vector__XXX
 SG_ VCLEFT_summonFaultReason m0 : 40|5@1+ (1,0) [0|31] "" Vector__XXX
 SG_ VCLEFT_epbSummonState m0 : 45|3@1+ (1,0) [0|7] "" Vector__XXX
 SG_ VCLEFT_epbmSummonState m0 : 48|3@1+ (1,0) [0|7] "" Vector__XXX
 SG_ VCLEFT_epbUnitStatus m0 : 51|5@1+ (1,0) [0|31] "" Vector__XXX
 SG_ VCLEFT_epbmFaultStatus m0 : 56|2@1+ (1,0) [0|3] "" Vector__XXX
 SG_ VCLEFT_epbFaultStatus m0 : 58|2@1+ (1,0) [0|3] "" Vector__XXX
 SG_ VCLEFT_epbmSystemStatus m0 : 60|4@1+ (1,0) [0|15] "" Vector__XXX

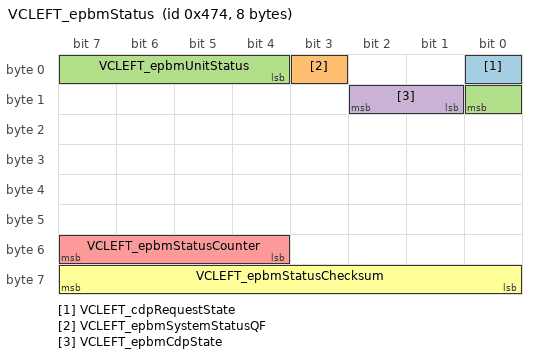
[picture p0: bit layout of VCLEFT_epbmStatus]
BO_ 1140 VCLEFT_epbmStatus: 8 VCLEFT
 SG_ VCLEFT_cdpRequestState : 0|1@1+ (1,0) [0|1] "" Vector__XXX
 SG_ VCLEFT_epbmSystemStatusQF : 3|1@1+ (1,0) [0|1] "" Vector__XXX
 SG_ VCLEFT_epbmUnitStatus : 4|5@1+ (1,0) [0|31] "" Vector__XXX
 SG_ VCLEFT_epbmCdpState : 9|2@1+ (1,0) [0|3] "" Vector__XXX
 SG_ VCLEFT_epbmStatusCounter : 52|4@1+ (1,0) [0|15] "" Vector__XXX
 SG_ VCLEFT_epbmStatusChecksum : 56|8@1+ (1,0) [0|255] "" Vector__XXX

BO_ 770 VCLEFT_info: 8 VCLEFT
 SG_ VCLEFT_infoIndex M : 0|8@1+ (1,0) [0|255] "" Vector__XXX
 SG_ VCLEFT_infoBuildType m10 : 8|3@1+ (1,0) [0|7] "" Vector__XXX
 SG_ VCLEFT_infoBuildConfigId m10 : 16|16@1+ (1,0) [0|65535] "" Vector__XXX
 SG_ VCLEFT_infoHardwareId m10 : 32|16@1+ (1,0) [0|65535] "" Vector__XXX
 SG_ VCLEFT_infoComponentId m10 : 48|16@1+ (1,0) [0|65535] "" Vector__XXX
 SG_ VCLEFT_infoPcbaId m11 : 8|8@1+ (1,0) [0|255] "" Vector__XXX
 SG_ VCLEFT_infoAssemblyId m11 : 16|8@1+ (1,0) [0|254] "" Vector__XXX
 SG_ VCLEFT_infoUsageId m11 : 24|16@1+ (1,0) [0|65535] "" Vector__XXX
 SG_ VCLEFT_infoSubUsageId m11 : 40|16@1+ (1,0) [0|65535] "" Vector__XXX
 SG_ VCLEFT_infoAppCrc m13 : 8|32@1+ (1,0) [0|4294967295] "" Vector__XXX
 SG_ VCLEFT_infoAppGitHash m17 : 8|56@1+ (1,0) [0|7.20575940379e+16] "" Vector__XXX
 SG_ VCLEFT_infoBootGitHash m18 : 8|56@1+ (1,0) [0|7.20575940379e+16] "" Vector__XXX
 SG_ VCLEFT_infoPlatformType m19 : 8|8@1+ (1,0) [0|255] "" Vector__XXX
 SG_ VCLEFT_infoBootUdsProtoVersion m20 : 8|16@1+ (1,0) [0|65535] "" Vector__XXX
 SG_ VCLEFT_infoBootCrc m20 : 24|32@1+ (1,0) [0|4294967295] "" Vector__XXX

BO_TX_BU_ 864 : VCLEFT;
BO_TX_BU_ 258 : VCLEFT;
BO_TX_BU_ 626 : VCLEFT;
BO_TX_BU_ 1140 : VCLEFT;
BO_TX_BU_ 770 : VCLEFT;
CM_ SG_ 2013 VCLEFT_a404_rightSteeringWheelSw "Left body controller: a404 right steering wheel switch";
CM_ SG_ 2013 VCLEFT_a405_leftSteeringWheelSwi "Left body controller: a405 left steering wheel switch";
CM_ SG_ 2013 VCLEFT_a405_rightSteeringWheelSw "Left body controller: a405 right steering wheel switch";
CM_ SG_ 2013 VCLEFT_a406_leftSteeringWheelSwi "Left body controller: a406 left steering wheel switch";
CM_ SG_ 2013 VCLEFT_a406_rightSteeringWheelSw "Left body controller: a406 right steering wheel switch";
CM_ SG_ 2013 VCLEFT_a407_leftSteeringWheelSwi "Left body controller: a407 left steering wheel switch";
CM_ SG_ 2013 VCLEFT_a407_rightSteeringWheelSw "Left body controller: a407 right steering wheel switch";
CM_ SG_ 2013 VCLEFT_a409_leftScrollWheelFault "Left body controller: a409 left scroll wheel fault";
CM_ SG_ 2013 VCLEFT_a409_rightScrollWheelFaul "Left body controller: a409 right scroll wheel fault";
CM_ SG_ 2013 VCLEFT_a409_rightScrollWheelPrev "Left body controller: a409 right scroll wheel previous";
CM_ SG_ 2013 VCLEFT_a409_rightScrollWheelChal "Left body controller: a409 right scroll wheel challenge";
CM_ SG_ 2013 VCLEFT_a409_rightScrollWheelRaw0 "Left body controller: a409 right scroll wheel raw0";
CM_ SG_ 2013 VCLEFT_a409_rightScrollWheelRaw1 "Left body controller: a409 right scroll wheel raw1";
CM_ SG_ 2013 VCLEFT_a410_leftScrollWheelFault "Left body controller: a410 left scroll wheel fault";
CM_ SG_ 2013 VCLEFT_a410_rightScrollWheelFaul "Left body controller: a410 right scroll wheel fault";
CM_ SG_ 2013 VCLEFT_a411_leftScrollWheelFault "Left body controller: a411 left scroll wheel fault";
CM_ SG_ 2013 VCLEFT_a411_rightScrollWheelFaul "Left body controller: a411 right scroll wheel fault";
CM_ SG_ 2013 VCLEFT_a412_outputFaulted "Left body controller: a412 output faulted";
CM_ SG_ 2013 VCLEFT_a412_currentSenseFaulted "Left body controller: a412 current sense faulted";
CM_ SG_ 2013 VCLEFT_a412_tempSenseFaulted "Left body controller: a412 temp sense faulted";
CM_ SG_ 2013 VCLEFT_a412_underCurrent "Left body controller: a412 under current";
CM_ SG_ 2013 VCLEFT_a412_overCurrent "Left body controller: a412 over current";
CM_ SG_ 2013 VCLEFT_a412_overTemperature "Left body controller: a412 over temperature";
CM_ SG_ 2013 VCLEFT_a414_leftHapticMotorFault "Left body controller: a414 left haptic motor fault";
CM_ SG_ 2013 VCLEFT_a414_rightHapticMotorFaul "Left body controller: a414 right haptic motor fault";
CM_ SG_ 2013 VCLEFT_a415_leftVbatUndervoltage "Left body controller: a415 left vbat undervoltage fault";
CM_ SG_ 2013 VCLEFT_a415_rightVbatUndervoltag "Left body controller: a415 right vbat undervoltage fault";
CM_ SG_ 2013 VCLEFT_a415_leftVbatOvervoltageF "Left body controller: a415 left vbat overvoltage fault";
CM_ SG_ 2013 VCLEFT_a415_rightVbatOvervoltage "Left body controller: a415 right vbat overvoltage fault";
CM_ SG_ 2013 VCLEFT_a417_leftDomeTouch "Left body controller: a417 left dome touch";
CM_ SG_ 2013 VCLEFT_a417_parkButtonTouch "Left body controller: a417 park button touch";
CM_ SG_ 2013 VCLEFT_a417_reverseButtonTouch "Left body controller: a417 reverse button touch";
CM_ SG_ 2013 VCLEFT_a417_hazardButtonTouch "Left body controller: a417 hazard button touch";
CM_ SG_ 2013 VCLEFT_a417_neutralButtonTouch "Left body controller: a417 neutral button touch";
CM_ SG_ 2013 VCLEFT_a417_driveButtonTouch "Left body controller: a417 drive button touch";
CM_ SG_ 2013 VCLEFT_a417_rightDomeTouch "Left body controller: a417 right dome touch";
CM_ SG_ 2013 VCLEFT_a419_leftDomeTouch "Left body controller: a419 left dome touch";
CM_ SG_ 2013 VCLEFT_a419_parkButtonTouch "Left body controller: a419 park button touch";
CM_ SG_ 2013 VCLEFT_a419_reverseButtonTouch "Left body controller: a419 reverse button touch";
CM_ SG_ 2013 VCLEFT_a419_hazardButtonTouch "Left body controller: a419 hazard button touch";
CM_ SG_ 2013 VCLEFT_a419_neutralButtonTouch "Left body controller: a419 neutral button touch";
CM_ SG_ 2013 VCLEFT_a419_driveButtonTouch "Left body controller: a419 drive button touch";
CM_ SG_ 2013 VCLEFT_a419_rightDomeTouch "Left body controller: a419 right dome touch";
CM_ SG_ 2013 VCLEFT_a420_leftDomeTouch "Left body controller: a420 left dome touch";
CM_ SG_ 2013 VCLEFT_a420_parkButtonTouch "Left body controller: a420 park button touch";
CM_ SG_ 2013 VCLEFT_a420_reverseButtonTouch "Left body controller: a420 reverse button touch";
CM_ SG_ 2013 VCLEFT_a420_hazardButtonTouch "Left body controller: a420 hazard button touch";
CM_ SG_ 2013 VCLEFT_a420_neutralButtonTouch "Left body controller: a420 neutral button touch";
CM_ SG_ 2013 VCLEFT_a420_driveButtonTouch "Left body controller: a420 drive button touch";
CM_ SG_ 2013 VCLEFT_a420_rightDomeTouch "Left body controller: a420 right dome touch";
CM_ SG_ 2013 VCLEFT_a421_parkButtonForce "Left body controller: a421 park button force";
CM_ SG_ 2013 VCLEFT_a421_reverseButtonForce "Left body controller: a421 reverse button force";
CM_ SG_ 2013 VCLEFT_a421_hazardButtonForce "Left body controller: a421 hazard button force";
CM_ SG_ 2013 VCLEFT_a421_neutralButtonForce "Left body controller: a421 neutral button force";
CM_ SG_ 2013 VCLEFT_a421_driveButtonForce "Left body controller: a421 drive button force";
CM_ SG_ 2013 VCLEFT_a424_parkButtonLED "Left body controller: a424 park button LED";
CM_ SG_ 2013 VCLEFT_a424_reverseButtonLED "Left body controller: a424 reverse button LED";
CM_ SG_ 2013 VCLEFT_a424_neutralButtonLED "Left body controller: a424 neutral button LED";
CM_ SG_ 2013 VCLEFT_a424_driveButtonLED "Left body controller: a424 drive button LED";
CM_ SG_ 2013 VCLEFT_a424_commonButtonLED "Left body controller: a424 common button LED";
CM_ SG_ 2013 VCLEFT_a425_leftVisorLightStatus "Left body controller: a425 left visor light status";
CM_ SG_ 2013 VCLEFT_a425_rightVisorLightStatu "Left body controller: a425 right visor light status";
CM_ SG_ 2013 VCLEFT_a426_seatMotorCalibrated "Left body controller: a426 seat motor calibrated";
CM_ SG_ 2013 VCLEFT_a426_seatMotorCurrent "Left body controller: a426 seat motor current";
CM_ SG_ 2013 VCLEFT_a426_seatMotorPosReal "Left body controller: a426 seat motor pos real";
CM_ SG_ 2013 VCLEFT_a426_seatMotorState "Left body controller: a426 seat motor state";
CM_ SG_ 2013 VCLEFT_a426_seatSwitchBack "Left body controller: a426 seat switch back; raw 0 = signal not available (SNA)";
CM_ SG_ 2013 VCLEFT_a426_seatSwitchForward "Left body controller: a426 seat switch forward; raw 0 = signal not available (SNA)";
CM_ SG_ 2013 VCLEFT_a426_cabinTmp "Left body controller: a426 cabin tmp";
CM_ SG_ 2013 VCLEFT_a427_seatMotorCalibrated "Left body controller: a427 seat motor calibrated";
CM_ SG_ 2013 VCLEFT_a427_seatMotorCurrent "Left body controller: a427 seat motor current";
CM_ SG_ 2013 VCLEFT_a427_seatMotorPosReal "Left body controller: a427 seat motor pos real";
CM_ SG_ 2013 VCLEFT_a427_seatMotorState "Left body controller: a427 seat motor state";
CM_ SG_ 2013 VCLEFT_a427_seatSwitchBack "Left body controller: a427 seat switch back; raw 0 = signal not available (SNA)";
CM_ SG_ 2013 VCLEFT_a427_seatSwitchForward "Left body controller: a427 seat switch forward; raw 0 = signal not available (SNA)";
CM_ SG_ 2013 VCLEFT_a427_cabinTmp "Left body controller: a427 cabin tmp";
CM_ SG_ 2013 VCLEFT_a428_seatMotorCalibrated "Left body controller: a428 seat motor calibrated";
CM_ SG_ 2013 VCLEFT_a428_seatMotorCurrent "Left body controller: a428 seat motor current";
CM_ SG_ 2013 VCLEFT_a428_seatMotorPosReal "Left body controller: a428 seat motor pos real";
CM_ SG_ 2013 VCLEFT_a428_seatMotorState "Left body controller: a428 seat motor state";
CM_ SG_ 2013 VCLEFT_a428_seatSwitchBack "Left body controller: a428 seat switch back; raw 0 = signal not available (SNA)";
CM_ SG_ 2013 VCLEFT_a428_seatSwitchForward "Left body controller: a428 seat switch forward; raw 0 = signal not available (SNA)";
CM_ SG_ 2013 VCLEFT_a428_cabinTmp "Left body controller: a428 cabin tmp";
CM_ SG_ 2013 VCLEFT_a429_seatMotorCalibrated "Left body controller: a429 seat motor calibrated";
CM_ SG_ 2013 VCLEFT_a429_seatMotorCurrent "Left body controller: a429 seat motor current";
CM_ SG_ 2013 VCLEFT_a429_seatMotorPosReal "Left body controller: a429 seat motor pos real";
CM_ SG_ 2013 VCLEFT_a429_seatMotorState "Left body controller: a429 seat motor state";
CM_ SG_ 2013 VCLEFT_a429_seatSwitchBack "Left body controller: a429 seat switch back; raw 0 = signal not available (SNA)";
CM_ SG_ 2013 VCLEFT_a429_seatSwitchForward "Left body controller: a429 seat switch forward; raw 0 = signal not available (SNA)";
CM_ SG_ 2013 VCLEFT_a429_cabinTmp "Left body controller: a429 cabin tmp";
CM_ SG_ 2013 VCLEFT_a430_leftRearDomeLightPow "Left body controller: a430 left rear dome light power supply status";
CM_ SG_ 2013 VCLEFT_a430_rightRearDomeLightPo "Left body controller: a430 right rear dome light power supply status";
CM_ SG_ 2013 VCLEFT_a431_dcdcVoltageFailure "Left body controller: a431 dcdc voltage failure";
CM_ SG_ 2013 VCLEFT_a431_overVoltageDetected "Left body controller: a431 over voltage detected";
CM_ SG_ 2013 VCLEFT_a431_underVoltageDetected "Left body controller: a431 under voltage detected";
CM_ SG_ 2013 VCLEFT_a431_brownoutDetected "Left body controller: a431 brownout detected";
CM_ SG_ 2013 VCLEFT_a444_retriesAvailable "Left body controller: a444 retries available";
CM_ SG_ 2013 VCLEFT_a444_channel "Left body controller: a444 channel";
CM_ SG_ 2013 VCLEFT_a444_watchdog "Left body controller: a444 watchdog";
CM_ SG_ 2013 VCLEFT_a444_gateDriver "Left body controller: a444 gate driver";
CM_ SG_ 2013 VCLEFT_a444_overcurrent "Left body controller: a444 overcurrent";
CM_ SG_ 2013 VCLEFT_a444_supplyUndervoltage "Left body controller: a444 supply undervoltage";
CM_ SG_ 2013 VCLEFT_a444_cpUndervoltage "Left body controller: a444 cp undervoltage";
CM_ SG_ 2013 VCLEFT_a444_overTempShutdown "Left body controller: a444 over temp shutdown";
CM_ SG_ 2013 VCLEFT_a444_overTempWarning "Left body controller: a444 over temp warning";
CM_ SG_ 2013 VCLEFT_a444_highSide2GateDriver "Left body controller: a444 high side2 gate driver";
CM_ SG_ 2013 VCLEFT_a444_lowSide2GateDriver "Left body controller: a444 low side2 gate driver";
CM_ SG_ 2013 VCLEFT_a444_highSide1GateDriver "Left body controller: a444 high side1 gate driver";
CM_ SG_ 2013 VCLEFT_a444_lowSide1GateDriver "Left body controller: a444 low side1 gate driver";
CM_ SG_ 2013 VCLEFT_a444_highSide2OverCurent "Left body controller: a444 high side2 over curent";
CM_ SG_ 2013 VCLEFT_a444_lowSide2OverCurent "Left body controller: a444 low side2 over curent";
CM_ SG_ 2013 VCLEFT_a444_highSide1OverCurent "Left body controller: a444 high side1 over curent";
CM_ SG_ 2013 VCLEFT_a444_lowSide1OverCurent "Left body controller: a444 low side1 over curent";
CM_ SG_ 2013 VCLEFT_a444_spiInit "Left body controller: a444 spi init";
CM_ SG_ 2013 VCLEFT_a444_spiPeriodicCheck "Left body controller: a444 spi periodic check";
CM_ SG_ 2013 VCLEFT_a444_spiFault "Left body controller: a444 spi fault";
CM_ SG_ 2013 VCLEFT_a444_voltageMonitor "Left body controller: a444 voltage monitor";
CM_ SG_ 2013 VCLEFT_a444_enableLow "Left body controller: a444 enable low";
CM_ SG_ 2013 VCLEFT_a447_endstopPositionMM "Left body controller: a447 endstop position MM";
CM_ SG_ 2013 VCLEFT_a447_motorType "Left body controller: a447 motor type";
CM_ SG_ 2013 VCLEFT_a448_endstopPositionMM "Left body controller: a448 endstop position MM";
CM_ SG_ 2013 VCLEFT_a448_motorType "Left body controller: a448 motor type";
CM_ SG_ 2013 VCLEFT_a453_liftgatePosition "Left body controller: a453 liftgate position";
CM_ SG_ 2013 VCLEFT_a455_liftgateState "Left body controller: a455 liftgate state";
CM_ SG_ 2013 VCLEFT_a466_hvac2RLeftAirwaveVer "Left body controller: a466 hvac2 r left airwave vertical stall";
CM_ SG_ 2013 VCLEFT_a469_hvac2RLeftAirwaveLat "Left body controller: a469 hvac2 r left airwave lateral stall";
CM_ SG_ 2013 VCLEFT_a472_hvac2RRightAirwaveVe "Left body controller: a472 hvac2 r right airwave vertical stall";
CM_ SG_ 2013 VCLEFT_a475_hvac2RRightAirwaveLa "Left body controller: a475 hvac2 r right airwave lateral stall";
CM_ SG_ 2013 VCLEFT_a480_reset "Left body controller: a480 reset";
CM_ SG_ 2013 VCLEFT_a480_spiError "Left body controller: a480 spi error";
CM_ SG_ 2013 VCLEFT_a480_autoOn "Left body controller: a480 auto on";
CM_ SG_ 2013 VCLEFT_a480_diagnosticBit "Left body controller: a480 diagnostic bit";
CM_ SG_ 2013 VCLEFT_a480_deviceError "Left body controller: a480 device error";
CM_ SG_ 2013 VCLEFT_a480_overcurrent "Left body controller: a480 overcurrent";
CM_ SG_ 2013 VCLEFT_a480_unexpectedLock "Left body controller: a480 unexpected lock";
CM_ SG_ 2013 VCLEFT_a480_disableOutputFault "Left body controller: a480 disable output fault";
CM_ SG_ 2013 VCLEFT_a480_vsUndervoltage "Left body controller: a480 vs undervoltage";
CM_ SG_ 2013 VCLEFT_a480_hardShort "Left body controller: a480 hard short";
CM_ SG_ 2013 VCLEFT_a480_vdsMax "Left body controller: a480 vds max";
CM_ SG_ 2013 VCLEFT_a480_bypassSaturation "Left body controller: a480 bypass saturation";
CM_ SG_ 2013 VCLEFT_a480_fuseLatch "Left body controller: a480 fuse latch";
CM_ SG_ 2013 VCLEFT_a480_deviceOvertemperatur "Left body controller: a480 device overtemperature";
CM_ SG_ 2013 VCLEFT_a480_ntcOvertemperature "Left body controller: a480 ntc overtemperature";
CM_ SG_ 2013 VCLEFT_a480_vgsLow "Left body controller: a480 vgs low";
CM_ SG_ 2013 VCLEFT_a480_chargePumpLow "Left body controller: a480 charge pump low";
CM_ SG_ 2013 VCLEFT_a480_watchdog "Left body controller: a480 watchdog";
CM_ SG_ 2013 VCLEFT_a480_spiNotDone "Left body controller: a480 spi not done";
CM_ SG_ 2013 VCLEFT_a480_configIncorrect "Left body controller: a480 config incorrect";
CM_ SG_ 2013 VCLEFT_a480_bufferFull "Left body controller: a480 buffer full";
CM_ SG_ 2013 VCLEFT_a480_hitAlertRateLimit "Left body controller: a480 hit alert rate limit";
CM_ SG_ 2013 VCLEFT_a480_hwlo "Left body controller: a480 hwlo";
CM_ SG_ 2013 VCLEFT_a480_enable "Left body controller: a480 enable";
CM_ SG_ 2013 VCLEFT_a482_channel "Left body controller: a482 channel";
CM_ SG_ 2013 VCLEFT_a482_spiFault "Left body controller: a482 spi fault";
CM_ SG_ 2013 VCLEFT_a482_resetBar "Left body controller: a482 reset bar";
CM_ SG_ 2013 VCLEFT_a482_overTempShutdown "Left body controller: a482 over temp shutdown";
CM_ SG_ 2013 VCLEFT_a482_thermalWarning "Left body controller: a482 thermal warning";
CM_ SG_ 2013 VCLEFT_a482_underOrOverVoltageOr "Left body controller: a482 under or over voltage or over current";
CM_ SG_ 2013 VCLEFT_a482_underloadDetected "Left body controller: a482 underload detected";
CM_ SG_ 2013 VCLEFT_a500_channel "Left body controller: a500 channel";
CM_ SG_ 2013 VCLEFT_a500_mismatchedState "Left body controller: a500 mismatched state";
CM_ SG_ 2013 VCLEFT_a520_epbConfig "Left body controller: a520 epb config";
CM_ SG_ 2013 VCLEFT_a520_gtwEpbConfig "Left body controller: a520 gtw epb config";
CM_ SG_ 2013 VCLEFT_a523_channel "Left body controller: a523 channel";
CM_ SG_ 2013 VCLEFT_a523_control2Byte1 "Left body controller: a523 control2 byte1";
CM_ SG_ 2013 VCLEFT_a523_control2Byte2 "Left body controller: a523 control2 byte2";
CM_ SG_ 2013 VCLEFT_a523_control2Byte3 "Left body controller: a523 control2 byte3";
CM_ SG_ 2013 VCLEFT_a523_control3Byte2 "Left body controller: a523 control3 byte2";
CM_ SG_ 2013 VCLEFT_a523_control3Byte3 "Left body controller: a523 control3 byte3";
CM_ SG_ 2013 VCLEFT_a525_GTW_twelveVBatteryTy "Left body controller: a525 GTW twelve v battery type";
CM_ SG_ 2013 VCLEFT_a525_newLVBatteryType "Left body controller: a525 new LV battery type";
CM_ SG_ 2013 VCLEFT_a525_initialLVBatteryType "Left body controller: a525 initial LV battery type";
CM_ SG_ 2013 VCLEFT_a525_serviceMode "Signal reported by Left body controller";
CM_ SG_ 2013 VCLEFT_a525_factoryGated "Left body controller: a525 factory gated";
CM_ SG_ 2013 VCLEFT_a525_frunkOpen "Left body controller: a525 frunk open";
CM_ SG_ 2013 VCLEFT_a536_trunkFoldFlatSwitchS "Left body controller: a536 trunk fold flat switch state; raw 0 = signal not available (SNA)";
CM_ SG_ 2013 VCLEFT_a536_trunkFoldFlatLeftSwi "Left body controller: a536 trunk fold flat left switch voltage";
CM_ SG_ 2013 VCLEFT_a545_GTW_twelveVBatteryTy "Left body controller: a545 GTW twelve v battery type";
CM_ SG_ 2013 VCLEFT_a545_newLVBatteryType "Left body controller: a545 new LV battery type";
CM_ SG_ 2013 VCLEFT_a545_serviceMode "Signal reported by Left body controller";
CM_ SG_ 2013 VCLEFT_a545_factoryGated "Left body controller: a545 factory gated";
CM_ SG_ 2013 VCLEFT_a545_frunkOpen "Left body controller: a545 frunk open";
CM_ SG_ 2013 VCLEFT_a551_restrictDoorReleaseS "Left body controller: a551 restrict door release signal front";
CM_ SG_ 2013 VCLEFT_a551_interiorReleaseReqCo "Left body controller: a551 interior release req count front";
CM_ SG_ 2013 VCLEFT_a551_lastRequestSourceFro "Left body controller: a551 last request source front";
CM_ SG_ 2013 VCLEFT_a551_restrictDoorRel_0001 "Left body controller: a551 restrict door release signal rear";
CM_ SG_ 2013 VCLEFT_a551_interiorRelease_0001 "Left body controller: a551 interior release req count rear";
CM_ SG_ 2013 VCLEFT_a551_lastRequestSourceRea "Left body controller: a551 last request source rear";
CM_ SG_ 2013 VCLEFT_a555_heaterPWMCommand "Left body controller: a555 heater PWM command";
CM_ SG_ 2013 VCLEFT_a555_ntcTemperature "Left body controller: a555 ntc temperature";
CM_ SG_ 2013 VCLEFT_a560_isRearwardEndstopUnc "Left body controller: a560 is rearward endstop uncalibrated";
CM_ SG_ 2013 VCLEFT_a560_isAbsPosSensorUncali "Left body controller: a560 is abs pos sensor uncalibrated";
CM_ SG_ 2013 VCLEFT_a560_seatState "Left body controller: a560 seat state; raw 15 = signal not available (SNA)";
CM_ SG_ 2013 VCLEFT_a560_motorType "Left body controller: a560 motor type";
CM_ SG_ 2013 VCLEFT_a560_absPosSensState "Left body controller: a560 abs pos sens state";
CM_ SG_ 2013 VCLEFT_a563_calibrated "Left body controller: a563 calibrated";
CM_ SG_ 2013 VCLEFT_a563_angle "Left body controller: a563 angle";
CM_ SG_ 2013 VCLEFT_a563_seatStatePrev "Left body controller: a563 seat state prev; raw 15 = signal not available (SNA)";
CM_ SG_ 2013 VCLEFT_a563_obstacleDetectReason "Left body controller: a563 obstacle detect reason";
CM_ SG_ 2013 VCLEFT_a563_accelLookbackTripDep "Left body controller: a563 accel lookback trip depth";
CM_ SG_ 2013 VCLEFT_a563_duty "Left body controller: a563 duty";
CM_ SG_ 2013 VCLEFT_a563_currentAbsFilt "Left body controller: a563 current abs filt";
CM_ SG_ 2013 VCLEFT_a563_motorType "Left body controller: a563 motor type";
CM_ SG_ 2013 VCLEFT_a563_absolutePosSensorFor "Left body controller: a563 absolute pos sensor forward";
CM_ SG_ 2013 VCLEFT_a563_cabinTemp "Left body controller: a563 cabin temp";
CM_ SG_ 2013 VCLEFT_a567_isRearwardEndstopUnc "Left body controller: a567 is rearward endstop uncalibrated";
CM_ SG_ 2013 VCLEFT_a567_isAbsPosSensorUncali "Left body controller: a567 is abs pos sensor uncalibrated";
CM_ SG_ 2013 VCLEFT_a568_seatState "Left body controller: a568 seat state; raw 15 = signal not available (SNA)";
CM_ SG_ 2013 VCLEFT_a570_seatHeatCurrent "Left body controller: a570 seat heat current";
CM_ SG_ 2013 VCLEFT_a570_seatHeatTmp "Left body controller: a570 seat heat tmp";
CM_ SG_ 2013 VCLEFT_a571_seatHeatCurrent "Left body controller: a571 seat heat current";
CM_ SG_ 2013 VCLEFT_a571_seatHeatTmp "Left body controller: a571 seat heat tmp";
CM_ SG_ 2013 VCLEFT_a572_seatHeatCurrent "Left body controller: a572 seat heat current";
CM_ SG_ 2013 VCLEFT_a572_seatHeatTmp "Left body controller: a572 seat heat tmp";
CM_ SG_ 2013 VCLEFT_a573_seatHeatCurrent "Left body controller: a573 seat heat current";
CM_ SG_ 2013 VCLEFT_a573_seatHeatTmp "Left body controller: a573 seat heat tmp";
CM_ SG_ 2013 VCLEFT_a577_outputFaulted "Left body controller: a577 output faulted";
CM_ SG_ 2013 VCLEFT_a577_currentSenseFaulted "Left body controller: a577 current sense faulted";
CM_ SG_ 2013 VCLEFT_a577_tempSenseFaulted "Left body controller: a577 temp sense faulted";
CM_ SG_ 2013 VCLEFT_a577_underCurrent "Left body controller: a577 under current";
CM_ SG_ 2013 VCLEFT_a577_overCurrent "Left body controller: a577 over current";
CM_ SG_ 2013 VCLEFT_a577_overTemperature "Left body controller: a577 over temperature";
CM_ SG_ 2013 VCLEFT_a578_openCircuitDashFL "Left body controller: a578 open circuit dash FL";
CM_ SG_ 2013 VCLEFT_a578_shortCircuitDashFL "Left body controller: a578 short circuit dash FL";
CM_ SG_ 2013 VCLEFT_a578_miaDashFL "Left body controller: a578 mia dash FL";
CM_ SG_ 2013 VCLEFT_a578_openCircuitDashFR "Left body controller: a578 open circuit dash FR";
CM_ SG_ 2013 VCLEFT_a578_shortCircuitDashFR "Left body controller: a578 short circuit dash FR";
CM_ SG_ 2013 VCLEFT_a578_miaDashFR "Left body controller: a578 mia dash FR";
CM_ SG_ 2013 VCLEFT_a578_openCircuitDoorFL "Left body controller: a578 open circuit door FL";
CM_ SG_ 2013 VCLEFT_a578_shortCircuitDoorFL "Left body controller: a578 short circuit door FL";
CM_ SG_ 2013 VCLEFT_a578_miaDoorFL "Left body controller: a578 mia door FL";
CM_ SG_ 2013 VCLEFT_a578_openCircuitDoorRL "Left body controller: a578 open circuit door RL";
CM_ SG_ 2013 VCLEFT_a578_shortCircuitDoorRL "Left body controller: a578 short circuit door RL";
CM_ SG_ 2013 VCLEFT_a578_miaDoorRL "Left body controller: a578 mia door RL";
CM_ SG_ 2013 VCLEFT_a579_gtwConfigType "Left body controller: a579 gtw config type";
CM_ SG_ 2013 VCLEFT_a579_installedHwid "Left body controller: a579 installed hwid";
CM_ SG_ 2013 VCLEFT_a580_gtwConfigType "Left body controller: a580 gtw config type";
CM_ SG_ 2013 VCLEFT_a580_installedHwid "Left body controller: a580 installed hwid";
CM_ SG_ 2013 VCLEFT_a581_outputFaulted "Left body controller: a581 output faulted";
CM_ SG_ 2013 VCLEFT_a581_currentSenseFaulted "Left body controller: a581 current sense faulted";
CM_ SG_ 2013 VCLEFT_a581_tempSenseFaulted "Left body controller: a581 temp sense faulted";
CM_ SG_ 2013 VCLEFT_a581_underCurrent "Left body controller: a581 under current";
CM_ SG_ 2013 VCLEFT_a581_overCurrent "Left body controller: a581 over current";
CM_ SG_ 2013 VCLEFT_a581_overTemperature "Left body controller: a581 over temperature";
CM_ SG_ 2013 VCLEFT_a585_ambientTemp "Left body controller: a585 ambient temp; raw 0 = signal not available (SNA)";
CM_ SG_ 2013 VCLEFT_a586_ambientTemp "Left body controller: a586 ambient temp; raw 0 = signal not available (SNA)";
CM_ SG_ 2013 VCLEFT_a599_GTW_twelveVBatteryTy "Left body controller: a599 GTW twelve v battery type";
CM_ SG_ 2013 VCLEFT_a599_newLVBatteryType "Left body controller: a599 new LV battery type";
CM_ SG_ 2013 VCLEFT_a599_initialLVBatteryType "Left body controller: a599 initial LV battery type";
CM_ SG_ 2013 VCLEFT_a599_serviceMode "Signal reported by Left body controller";
CM_ SG_ 2013 VCLEFT_a599_factoryGated "Left body controller: a599 factory gated";
CM_ SG_ 2013 VCLEFT_a599_frunkOpen "Left body controller: a599 frunk open";
CM_ SG_ 2013 VCLEFT_a617_VEH_VC_infoMessage "Left body controller: a617 VEH VC info message";
CM_ SG_ 2013 VCLEFT_a617_BDY_defogInfoMessage "Left body controller: a617 BDY defog info message";
CM_ SG_ 2013 VCLEFT_a617_VEH_defogInfoMessage "Left body controller: a617 VEH defog info message";
CM_ SG_ 2013 VCLEFT_a617_VEH_thermalStatus "Left body controller: a617 VEH thermal status";
CM_ BO_ 864 "Left body controller message: alert matrix";
CM_ SG_ 864 VCLEFT_matrixIndex "Left body controller: matrix index";
CM_ SG_ 864 VCLEFT_a001_WatchdogReset "Left body controller: a001 watchdog reset";
CM_ SG_ 864 VCLEFT_a002_PowerLossReset "Left body controller: a002 power loss reset";
CM_ SG_ 864 VCLEFT_a003_SWAssertion "Left body controller: a003 SW assertion";
CM_ SG_ 864 VCLEFT_a005_CANTXError "Left body controller: a005 CANTX error";
CM_ SG_ 864 VCLEFT_a006_CANTX_cyclicError "Left body controller: a006 CANTX cyclic error";
CM_ SG_ 864 VCLEFT_a010_ExtSupplyVoltError "Left body controller: a010 ext supply volt error";
CM_ SG_ 864 VCLEFT_a012_CPUReset "Left body controller: a012 CPU reset";
CM_ SG_ 864 VCLEFT_a013_AlertManagerFault "Left body controller: a013 alert manager fault";
CM_ SG_ 864 VCLEFT_a015_NVMMError "Left body controller: a015 NVMM error";
CM_ SG_ 864 VCLEFT_a016_NVMMRecordError "Left body controller: a016 NVMM record error";
CM_ SG_ 864 VCLEFT_a017_NVMMStatusDbg "Left body controller: a017 NVMM status dbg";
CM_ SG_ 864 VCLEFT_a021_TaskSchedulerError "Left body controller: a021 task scheduler error";
CM_ SG_ 864 VCLEFT_a022_TaskInitError "Left body controller: a022 task init error";
CM_ SG_ 864 VCLEFT_a029_CoreDump "Left body controller: a029 core dump";
CM_ SG_ 864 VCLEFT_a030_ECULogUploadRequest "Left body controller: a030 ECU log upload request";
CM_ SG_ 864 VCLEFT_a031_UDSActive "Left body controller: a031 UDS active";
CM_ SG_ 864 VCLEFT_a041_HighCPULoad "Left body controller: a041 high CPU load";
CM_ SG_ 864 VCLEFT_a042_HighStackUsage "Left body controller: a042 high stack usage";
CM_ SG_ 864 VCLEFT_a043_Task1msError "Left body controller: a043 task1ms error";
CM_ SG_ 864 VCLEFT_a044_Task10msError "Left body controller: a044 task10ms error";
CM_ SG_ 864 VCLEFT_a045_Task100msError "Left body controller: a045 task100ms error";
CM_ SG_ 864 VCLEFT_a046_Task1000msError "Left body controller: a046 task1000ms error";
CM_ SG_ 864 VCLEFT_a057_HVP_MIA "Left body controller: a057 HVP MIA";
CM_ SG_ 864 VCLEFT_a058_inputRHighSyncDebug "Left body controller: a058 input r high sync debug";
CM_ SG_ 864 VCLEFT_a059_inputResistanceHigh "Left body controller: a059 input resistance high";
CM_ SG_ 864 VCLEFT_a060_engineeringBuild "Left body controller: a060 engineering build";
CM_ SG_ 864 VCLEFT_a061_XCPConnected "Left body controller: a061 XCP connected";
CM_ SG_ 864 VCLEFT_a062_XCPWasConnected "Left body controller: a062 XCP was connected";
CM_ SG_ 864 VCLEFT_a063_SwitchFault "Left body controller: a063 switch fault";
CM_ SG_ 864 VCLEFT_a064_busSleepReqTimeout "Left body controller: a064 bus sleep req timeout";
CM_ SG_ 864 VCLEFT_a065_emiosIsrRateLimitedD "Left body controller: a065 emios isr rate limited dbg";
CM_ SG_ 864 VCLEFT_a066_emiosIsrShortPeriodD "Left body controller: a066 emios isr short period detected dbg";
CM_ SG_ 864 VCLEFT_a082_VCRIGHT_IPC_MIA "Left body controller: a082 VCRIGHT IPC MIA";
CM_ SG_ 864 VCLEFT_a083_VCLEFT_IPC_MIA "Left body controller: a083 VCLEFT IPC MIA";
CM_ SG_ 864 VCLEFT_a084_TPMS_MIA "Left body controller: a084 TPMS MIA";
CM_ SG_ 864 VCLEFT_a085_CCCM_MIA "Left body controller: a085 CCCM MIA";
CM_ SG_ 864 VCLEFT_a086_VCBATT_MIA "Left body controller: a086 VCBATT MIA";
CM_ SG_ 864 VCLEFT_a087_DIREL_MIA "Left body controller: a087 DIREL MIA";
CM_ SG_ 864 VCLEFT_a088_DIRER_MIA "Left body controller: a088 DIRER MIA";
CM_ SG_ 864 VCLEFT_a089_IBST_MIA "Left body controller: a089 IBST MIA";
CM_ SG_ 864 VCLEFT_a090_APS_MIA "Left body controller: a090 APS MIA";
CM_ SG_ 864 VCLEFT_a091_CMPD_MIA "Left body controller: a091 CMPD MIA";
CM_ SG_ 864 VCLEFT_a092_VCSEATD_MIA "Left body controller: a092 VCSEATD MIA";
CM_ SG_ 864 VCLEFT_a093_VCSEATP_MIA "Left body controller: a093 VCSEATP MIA";
CM_ SG_ 864 VCLEFT_a094_EPAS3P_MIA "Left body controller: a094 EPAS3 p MIA";
CM_ SG_ 864 VCLEFT_a095_CHG_MIA "Left body controller: a095 CHG MIA";
CM_ SG_ 864 VCLEFT_a096_OCS1P_MIA "Left body controller: a096 OCS1 p MIA";
CM_ SG_ 864 VCLEFT_a097_CMP_MIA "Left body controller: a097 CMP MIA";
CM_ SG_ 864 VCLEFT_a098_DIR_MIA "Left body controller: a098 DIR MIA";
CM_ SG_ 864 VCLEFT_a099_PARK_MIA "Left body controller: a099 PARK MIA";
CM_ SG_ 864 VCLEFT_a100_CANbus_MIA "Left body controller: a100 CA nbus MIA";
CM_ SG_ 864 VCLEFT_a101_PM_MIA "Left body controller: a101 PM MIA";
CM_ SG_ 864 VCLEFT_a102_PTC_MIA "Left body controller: a102 PTC MIA";
CM_ SG_ 864 VCLEFT_a103_CP_MIA "Left body controller: a103 CP MIA";
CM_ SG_ 864 VCLEFT_a104_DAS_MIA "Left body controller: a104 DAS MIA";
CM_ SG_ 864 VCLEFT_a105_TAS_MIA "Left body controller: a105 TAS MIA";
CM_ SG_ 864 VCLEFT_a106_PCS_MIA "Left body controller: a106 PCS MIA";
CM_ SG_ 864 VCLEFT_a107_BMS_MIA "Left body controller: a107 BMS MIA";
CM_ SG_ 864 VCLEFT_a108_DIF_MIA "Left body controller: a108 DIF MIA";
CM_ SG_ 864 VCLEFT_a109_RCM_MIA "Left body controller: a109 RCM MIA";
CM_ SG_ 864 VCLEFT_a110_GTW_MIA "Left body controller: a110 GTW MIA";
CM_ SG_ 864 VCLEFT_a111_EPBR_MIA "Left body controller: a111 EPBR MIA";
CM_ SG_ 864 VCLEFT_a112_EPBL_MIA "Left body controller: a112 EPBL MIA";
CM_ SG_ 864 VCLEFT_a113_UI_MIA "Left body controller: a113 UI MIA";
CM_ SG_ 864 VCLEFT_a114_ESP_MIA "Left body controller: a114 ESP MIA";
CM_ SG_ 864 VCLEFT_a115_VCSEC_MIA "Left body controller: a115 VCSEC MIA";
CM_ SG_ 864 VCLEFT_a116_VCRIGHT_MIA "Left body controller: a116 VCRIGHT MIA";
CM_ SG_ 864 VCLEFT_a117_VCLEFT_MIA "Left body controller: a117 VCLEFT MIA";
CM_ SG_ 864 VCLEFT_a118_VCFRONT_MIA "Left body controller: a118 VCFRONT MIA";
CM_ SG_ 864 VCLEFT_a119_SCCM_MIA "Left body controller: a119 SCCM MIA";
CM_ SG_ 864 VCLEFT_a120_DI_DRIVE_MIA "Left body controller: a120 DI DRIVE MIA";
CM_ SG_ 864 VCLEFT_a121_ETC_MIA "Left body controller: a121 ETC MIA";
CM_ SG_ 864 VCLEFT_a122_ICR_MIA "Left body controller: a122 ICR MIA";
CM_ SG_ 864 VCLEFT_a123_AID_MIA "Left body controller: a123 AID MIA";
CM_ SG_ 864 VCLEFT_a124_BB_MIA "Left body controller: a124 BB MIA";
CM_ SG_ 864 VCLEFT_a125_RCU_MIA "Left body controller: a125 RCU MIA";
CM_ SG_ 864 VCLEFT_a129_blowerICLatchFault "Left body controller: a129 blower IC latch fault";
CM_ SG_ 864 VCLEFT_a130_blowerICWarning "Left body controller: a130 blower IC warning";
CM_ SG_ 864 VCLEFT_a131_blowerICTransFault "Left body controller: a131 blower IC trans fault";
CM_ SG_ 864 VCLEFT_a132_blowerSoftStall "Left body controller: a132 blower soft stall";
CM_ SG_ 864 VCLEFT_a133_blowerLowRPMCBang "Left body controller: a133 blower low RPMC bang";
CM_ SG_ 864 VCLEFT_a134_SteerColUpDownUnCal "Left body controller: a134 steer col up down un cal";
CM_ SG_ 864 VCLEFT_a135_SteerColInOutUnCal "Left body controller: a135 steer col in out un cal";
CM_ SG_ 864 VCLEFT_a136_brakeSwitchMismatch "Left body controller: a136 brake switch mismatch";
CM_ SG_ 864 VCLEFT_a137_VCSECPowerCycled "Left body controller: a137 VCSEC power cycled";
CM_ SG_ 864 VCLEFT_a138_consoleDoorAssist "Left body controller: a138 console door assist";
CM_ SG_ 864 VCLEFT_a139_BLERearPowerCycled "Left body controller: a139 BLE rear power cycled";
CM_ SG_ 864 VCLEFT_a140_BLELeftPowerCycled "Left body controller: a140 BLE left power cycled";
CM_ SG_ 864 VCLEFT_a141_12VAuxPowerTrip "Left body controller: a141 12 v aux power trip";
CM_ SG_ 864 VCLEFT_a143_mirrorManuallyFolded "Left body controller: a143 mirror manually folded";
CM_ SG_ 864 VCLEFT_a145_brakeSwitchStuck "Left body controller: a145 brake switch stuck";
CM_ SG_ 864 VCLEFT_a148_brakePressInputMisma "Left body controller: a148 brake press input mismatch";
CM_ SG_ 864 VCLEFT_a150_windowPinchFront "Left body controller: a150 window pinch front";
CM_ SG_ 864 VCLEFT_a151_windowPinchRear "Left body controller: a151 window pinch rear";
CM_ SG_ 864 VCLEFT_a152_windowUncalFront "Left body controller: a152 window uncal front";
CM_ SG_ 864 VCLEFT_a153_windowUncalRear "Left body controller: a153 window uncal rear";
CM_ SG_ 864 VCLEFT_a154_windowThermalFront "Left body controller: a154 window thermal front";
CM_ SG_ 864 VCLEFT_a155_windowThermalRear "Left body controller: a155 window thermal rear";
CM_ SG_ 864 VCLEFT_a156_windowNoInputFront "Left body controller: a156 window no input front";
CM_ SG_ 864 VCLEFT_a157_windowNoInputRear "Left body controller: a157 window no input rear";
CM_ SG_ 864 VCLEFT_a158_windowPinchOverideF "Left body controller: a158 window pinch overide f";
CM_ SG_ 864 VCLEFT_a159_windowPinchOverideR "Left body controller: a159 window pinch overide r";
CM_ SG_ 864 VCLEFT_a160_windowUndercurrentF "Left body controller: a160 window undercurrent f";
CM_ SG_ 864 VCLEFT_a161_windowUndercurrentR "Left body controller: a161 window undercurrent r";
CM_ SG_ 864 VCLEFT_a162_windowEncoderStallF "Left body controller: a162 window encoder stall f";
CM_ SG_ 864 VCLEFT_a163_windowEncoderStallR "Left body controller: a163 window encoder stall r";
CM_ SG_ 864 VCLEFT_a164_windowFactoryTest "Left body controller: a164 window factory test";
CM_ SG_ 864 VCLEFT_a165_windowFactoryTest2 "Left body controller: a165 window factory test2";
CM_ SG_ 864 VCLEFT_a166_windowDebug "Left body controller: a166 window debug";
CM_ SG_ 864 VCLEFT_a167_windowDebugPinchF "Left body controller: a167 window debug pinch f";
CM_ SG_ 864 VCLEFT_a168_windowDebugPinchR "Left body controller: a168 window debug pinch r";
CM_ SG_ 864 VCLEFT_a169_windowCurrentPeakF "Left body controller: a169 window current peak f";
CM_ SG_ 864 VCLEFT_a170_windowCurrentPeakR "Left body controller: a170 window current peak r";
CM_ SG_ 864 VCLEFT_a172_SPI_MIA "Left body controller: a172 SPI MIA";
CM_ SG_ 864 VCLEFT_a173_windowBtnDoorOpen "Left body controller: a173 window btn door open";
CM_ SG_ 864 VCLEFT_a175_windowSealDefectFron "Left body controller: a175 window seal defect front";
CM_ SG_ 864 VCLEFT_a176_windowSealDefectRear "Left body controller: a176 window seal defect rear";
CM_ SG_ 864 VCLEFT_a180_frontDoorLatchRehome "Left body controller: a180 front door latch rehome";
CM_ SG_ 864 VCLEFT_a181_rearDoorLatchRehome "Left body controller: a181 rear door latch rehome";
CM_ SG_ 864 VCLEFT_a182_emergencyLatchRel "Left body controller: a182 emergency latch rel";
CM_ SG_ 864 VCLEFT_a183_doorStateFactoryTest "Left body controller: a183 door state factory test";
CM_ SG_ 864 VCLEFT_a185_summonAborted "Left body controller: a185 summon aborted";
CM_ SG_ 864 VCLEFT_a186_latchReleaseFailedF "Left body controller: a186 latch release failed f";
CM_ SG_ 864 VCLEFT_a187_latchReleaseFailedR "Left body controller: a187 latch release failed r";
CM_ SG_ 864 VCLEFT_a188_latchUnableToRearmF "Left body controller: a188 latch unable to rearm f";
CM_ SG_ 864 VCLEFT_a189_latchUnableToRearmR "Left body controller: a189 latch unable to rearm r";
CM_ SG_ 864 VCLEFT_a190_eFuseMgmtVbatFused "Left body controller: a190 e fuse mgmt vbat fused";
CM_ SG_ 864 VCLEFT_a191_TLCOvercurrent "Left body controller: a191 TLC overcurrent";
CM_ SG_ 864 VCLEFT_a192_blowerGeneralFault "Left body controller: a192 blower general fault";
CM_ SG_ 864 VCLEFT_a193_blowerMIA "Left body controller: a193 blower MIA";
CM_ SG_ 864 VCLEFT_a194_blowerUnidentified "Left body controller: a194 blower unidentified";
CM_ SG_ 864 VCLEFT_a195_blowerIdentification "Left body controller: a195 blower identification failed";
CM_ SG_ 864 VCLEFT_a196_VEHCANOverterminate "Left body controller: a196 VEHCAN overterminate";
CM_ SG_ 864 VCLEFT_a197_VEHCANUndertrminate "Left body controller: a197 VEHCAN undertrminate";
CM_ SG_ 864 VCLEFT_a200_motorPhantomEncoder "Left body controller: a200 motor phantom encoder";
CM_ SG_ 864 VCLEFT_a201_motorDutyEncDisabl "Left body controller: a201 motor duty enc disabl";
CM_ SG_ 864 VCLEFT_a202_epbmUnderIStatic "Left body controller: a202 epbm under i static";
CM_ SG_ 864 VCLEFT_a203_epbmOverIStatic "Left body controller: a203 epbm over i static";
CM_ SG_ 864 VCLEFT_a204_epbmUnderIDyn "Left body controller: a204 epbm under i dyn";
CM_ SG_ 864 VCLEFT_a205_epbmOverIDyn "Left body controller: a205 epbm over i dyn";
CM_ SG_ 864 VCLEFT_a206_epbWrongDirection "Left body controller: a206 epb wrong direction";
CM_ SG_ 864 VCLEFT_a207_epbmEnableWrong "Left body controller: a207 epbm enable wrong";
CM_ SG_ 864 VCLEFT_a208_epbFaulted "Left body controller: a208 epb faulted";
CM_ SG_ 864 VCLEFT_a209_epbStateMisTime "Left body controller: a209 epb state mis time";
CM_ SG_ 864 VCLEFT_a210_epbStateTime "Left body controller: a210 epb state time";
CM_ SG_ 864 VCLEFT_a211_epbmUnderIStaticNew "Left body controller: a211 epbm under i static new";
CM_ SG_ 864 VCLEFT_a212_epbmOverIStaticNew "Left body controller: a212 epbm over i static new";
CM_ SG_ 864 VCLEFT_a213_epbmUnderIDynNew "Left body controller: a213 epbm under i dyn new";
CM_ SG_ 864 VCLEFT_a214_epbmOverIDynNew "Left body controller: a214 epbm over i dyn new";
CM_ SG_ 864 VCLEFT_a215_currentDesyncWarning "Left body controller: a215 current desync warning";
CM_ SG_ 864 VCLEFT_a216_SPI_MIA_debugData1 "Left body controller: a216 SPI MIA debug data1";
CM_ SG_ 864 VCLEFT_a217_SPI_MIA_debugData2 "Left body controller: a217 SPI MIA debug data2";
CM_ SG_ 864 VCLEFT_a218_motorDriverFault "Left body controller: a218 motor driver fault";
CM_ SG_ 864 VCLEFT_a219_motorCurrentDropout "Left body controller: a219 motor current dropout";
CM_ SG_ 864 VCLEFT_a224_seatEncStallTrack "Left body controller: a224 seat enc stall track";
CM_ SG_ 864 VCLEFT_a225_seatEncStallBack "Left body controller: a225 seat enc stall back";
CM_ SG_ 864 VCLEFT_a226_seatEncStallTilt "Left body controller: a226 seat enc stall tilt";
CM_ SG_ 864 VCLEFT_a227_seatEncStallLift "Left body controller: a227 seat enc stall lift";
CM_ SG_ 864 VCLEFT_a228_seatEncOverTrack "Left body controller: a228 seat enc over track";
CM_ SG_ 864 VCLEFT_a229_seatEncOverBack "Left body controller: a229 seat enc over back";
CM_ SG_ 864 VCLEFT_a230_seatEncOverTilt "Left body controller: a230 seat enc over tilt";
CM_ SG_ 864 VCLEFT_a231_seatEncOverLift "Left body controller: a231 seat enc over lift";
CM_ SG_ 864 VCLEFT_a232_seatCurrUnderTrack "Left body controller: a232 seat curr under track";
CM_ SG_ 864 VCLEFT_a233_seatCurrUnderBack "Left body controller: a233 seat curr under back";
CM_ SG_ 864 VCLEFT_a234_seatCurrUnderTilt "Left body controller: a234 seat curr under tilt";
CM_ SG_ 864 VCLEFT_a235_seatCurrUnderLift "Left body controller: a235 seat curr under lift";
CM_ SG_ 864 VCLEFT_a236_lumbarOverPresA "Left body controller: a236 lumbar over pres a";
CM_ SG_ 864 VCLEFT_a237_lumbarOverPresB "Left body controller: a237 lumbar over pres b";
CM_ SG_ 864 VCLEFT_a238_lumbarValveMIA "Left body controller: a238 lumbar valve MIA";
CM_ SG_ 864 VCLEFT_a239_seatHeatIFront "Left body controller: a239 seat heat i front";
CM_ SG_ 864 VCLEFT_a240_seatHeatShortFront "Left body controller: a240 seat heat short front";
CM_ SG_ 864 VCLEFT_a241_seatHeatMIAFront "Left body controller: a241 seat heat MIA front";
CM_ SG_ 864 VCLEFT_a242_seatHeatIRearL "Left body controller: a242 seat heat i rear l";
CM_ SG_ 864 VCLEFT_a243_seatHeatShortRearL "Left body controller: a243 seat heat short rear l";
CM_ SG_ 864 VCLEFT_a244_seatHeatMIARearL "Left body controller: a244 seat heat MIA rear l";
CM_ SG_ 864 VCLEFT_a245_seatHeatIRearC "Left body controller: a245 seat heat i rear c";
CM_ SG_ 864 VCLEFT_a246_seatHeatShortRearC "Left body controller: a246 seat heat short rear c";
CM_ SG_ 864 VCLEFT_a247_seatHeatMIARearC "Left body controller: a247 seat heat MIA rear c";
CM_ SG_ 864 VCLEFT_a248_seatHeatIRearR "Left body controller: a248 seat heat i rear r";
CM_ SG_ 864 VCLEFT_a249_seatHeatShortRearR "Left body controller: a249 seat heat short rear r";
CM_ SG_ 864 VCLEFT_a250_seatHeatMIARearR "Left body controller: a250 seat heat MIA rear r";
CM_ SG_ 864 VCLEFT_a251_seatUncalTrack "Left body controller: a251 seat uncal track";
CM_ SG_ 864 VCLEFT_a252_seatUncalBack "Left body controller: a252 seat uncal back";
CM_ SG_ 864 VCLEFT_a253_seatUncalTilt "Left body controller: a253 seat uncal tilt";
CM_ SG_ 864 VCLEFT_a254_seatUncalLift "Left body controller: a254 seat uncal lift";
CM_ SG_ 864 VCLEFT_a257_USBMIA "Left body controller: a257 USBMIA";
CM_ SG_ 864 VCLEFT_a259_latchDisarmDelayF "Left body controller: a259 latch disarm delay f";
CM_ SG_ 864 VCLEFT_a260_latchDisarmDelayR "Left body controller: a260 latch disarm delay r";
CM_ SG_ 864 VCLEFT_a261_emergencyLatchRelRea "Left body controller: a261 emergency latch rel rear";
CM_ SG_ 864 VCLEFT_a263_seatTrackStallDebug "Left body controller: a263 seat track stall debug";
CM_ SG_ 864 VCLEFT_a264_seatBackStallDebug "Left body controller: a264 seat back stall debug";
CM_ SG_ 864 VCLEFT_a265_seatTiltStallDebug "Left body controller: a265 seat tilt stall debug";
CM_ SG_ 864 VCLEFT_a266_seatLiftStallDebug "Left body controller: a266 seat lift stall debug";
CM_ SG_ 864 VCLEFT_a267_seatTrackHCEncStlDbg "Left body controller: a267 seat track HC enc stl dbg";
CM_ SG_ 864 VCLEFT_a268_seatBackHCEncStlDbg "Left body controller: a268 seat back HC enc stl dbg";
CM_ SG_ 864 VCLEFT_a269_seatTiltHCEncStlDbg "Left body controller: a269 seat tilt HC enc stl dbg";
CM_ SG_ 864 VCLEFT_a270_seatLiftHCEncStlDbg "Left body controller: a270 seat lift HC enc stl dbg";
CM_ SG_ 864 VCLEFT_a272_vhclPwrStateMsmtch "Left body controller: a272 vhcl pwr state msmtch";
CM_ SG_ 864 VCLEFT_a273_handleStuckActiveF "Left body controller: a273 handle stuck active f";
CM_ SG_ 864 VCLEFT_a274_handleStuckActiveR "Left body controller: a274 handle stuck active r";
CM_ SG_ 864 VCLEFT_a275_leftTurnLightFault "Left body controller: a275 left turn light fault";
CM_ SG_ 864 VCLEFT_a276_mirrorDebug "Left body controller: a276 mirror debug";
CM_ SG_ 864 VCLEFT_a277_BLELeftUnderVoltage "Left body controller: a277 BLE left under voltage";
CM_ SG_ 864 VCLEFT_a278_BLERearUnderVoltage "Left body controller: a278 BLE rear under voltage";
CM_ SG_ 864 VCLEFT_a279_VCSECUnderVoltage "Left body controller: a279 VCSEC under voltage";
CM_ SG_ 864 VCLEFT_a280_latchDidNotDisarmF "Left body controller: a280 latch did not disarm f";
CM_ SG_ 864 VCLEFT_a281_latchDidNotDisarmR "Left body controller: a281 latch did not disarm r";
CM_ SG_ 864 VCLEFT_a282_latchUnexpectedArmF "Left body controller: a282 latch unexpected arm f";
CM_ SG_ 864 VCLEFT_a283_latchUnexpectedArmR "Left body controller: a283 latch unexpected arm r";
CM_ SG_ 864 VCLEFT_a284_blowerFbkSanity "Left body controller: a284 blower fbk sanity";
CM_ SG_ 864 VCLEFT_a285_blowerChipComms "Left body controller: a285 blower chip comms";
CM_ SG_ 864 VCLEFT_a286_windowSpeedInvalidF "Left body controller: a286 window speed invalid f";
CM_ SG_ 864 VCLEFT_a287_windowSpeedInvalidR "Left body controller: a287 window speed invalid r";
CM_ SG_ 864 VCLEFT_a288_handlePWMPeriodF "Left body controller: a288 handle PWM period f";
CM_ SG_ 864 VCLEFT_a289_handlePWMPeriodR "Left body controller: a289 handle PWM period r";
CM_ SG_ 864 VCLEFT_a290_occupancyFaultedFron "Left body controller: a290 occupancy faulted front";
CM_ SG_ 864 VCLEFT_a291_buckleFaultedFront "Left body controller: a291 buckle faulted front";
CM_ SG_ 864 VCLEFT_a292_occupancyFaultedRear "Left body controller: a292 occupancy faulted rear l";
CM_ SG_ 864 VCLEFT_a293_occupancyFaultedRear "Left body controller: a293 occupancy faulted rear c";
CM_ SG_ 864 VCLEFT_a294_occupancyFaultedRear "Left body controller: a294 occupancy faulted rear r";
CM_ SG_ 864 VCLEFT_a295_buckleFaultedRearL "Left body controller: a295 buckle faulted rear l";
CM_ SG_ 864 VCLEFT_a296_buckleFaultedRearC "Left body controller: a296 buckle faulted rear c";
CM_ SG_ 864 VCLEFT_a297_seatBelowMinPumpTmp "Left body controller: a297 seat below min pump tmp";
CM_ SG_ 864 VCLEFT_a299_swcMIA "Left body controller: a299 swc MIA";
CM_ SG_ 864 VCLEFT_a300_swcUnderVoltage "Left body controller: a300 swc under voltage";
CM_ SG_ 864 VCLEFT_a301_swcOverVoltage "Left body controller: a301 swc over voltage";
CM_ SG_ 864 VCLEFT_a302_blowerGeneralFault "Left body controller: a302 blower general fault";
CM_ SG_ 864 VCLEFT_a303_eFuseMgmtWindowLift "Left body controller: a303 e fuse mgmt window lift";
CM_ SG_ 864 VCLEFT_a304_frontIntHandleShorte "Left body controller: a304 front int handle shorted";
CM_ SG_ 864 VCLEFT_a305_rearIntHandleShorted "Left body controller: a305 rear int handle shorted";
CM_ SG_ 864 VCLEFT_a306_handleDisconnectedF "Left body controller: a306 handle disconnected f";
CM_ SG_ 864 VCLEFT_a307_handleDisconnectedR "Left body controller: a307 handle disconnected r";
CM_ SG_ 864 VCLEFT_a308_sirenMIA "Left body controller: a308 siren MIA";
CM_ SG_ 864 VCLEFT_a309_brakeSwitchFaulted "Left body controller: a309 brake switch faulted";
CM_ SG_ 864 VCLEFT_a310_mirrorFoldStall "Left body controller: a310 mirror fold stall";
CM_ SG_ 864 VCLEFT_a311_leftBrakeLightFault "Left body controller: a311 left brake light fault";
CM_ SG_ 864 VCLEFT_a312_leftTailLightFault "Left body controller: a312 left tail light fault";
CM_ SG_ 864 VCLEFT_a313_leftFootwellLightFau "Left body controller: a313 left footwell light fault";
CM_ SG_ 864 VCLEFT_a314_leftMapPocketLightFa "Left body controller: a314 left map pocket light fault";
CM_ SG_ 864 VCLEFT_a315_leftInteriorTrunkLig "Left body controller: a315 left interior trunk light fault";
CM_ SG_ 864 VCLEFT_a316_mirrorPrematureFoldS "Left body controller: a316 mirror premature fold stall";
CM_ SG_ 864 VCLEFT_a317_epbmLimpModeEnabled "Left body controller: a317 epbm limp mode enabled";
CM_ SG_ 864 VCLEFT_a318_trailerIncorrectConf "Left body controller: a318 trailer incorrect config";
CM_ SG_ 864 VCLEFT_a319_brakePressPrimaryInp "Left body controller: a319 brake press primary input faulted";
CM_ SG_ 864 VCLEFT_a320_windowReportCrackedA "Left body controller: a320 window report cracked at trim clear";
CM_ SG_ 864 VCLEFT_a321_windowRezeroedDebugF "Left body controller: a321 window rezeroed debug f";
CM_ SG_ 864 VCLEFT_a322_windowRezeroedDebugR "Left body controller: a322 window rezeroed debug r";
CM_ SG_ 864 VCLEFT_a323_mirrorCalibrated "Left body controller: a323 mirror calibrated";
CM_ SG_ 864 VCLEFT_a324_mirrorHeatFault "Left body controller: a324 mirror heat fault";
CM_ SG_ 864 VCLEFT_a325_hghtSnsrUnplgdFL "Left body controller: a325 hght snsr unplgd FL";
CM_ SG_ 864 VCLEFT_a326_hghtSnsrUnplgdRL "Left body controller: a326 hght snsr unplgd RL";
CM_ SG_ 864 VCLEFT_a327_hghtSnsrFaultFL "Left body controller: a327 hght snsr fault FL";
CM_ SG_ 864 VCLEFT_a328_hghtSnsrFaultRL "Left body controller: a328 hght snsr fault RL";
CM_ SG_ 864 VCLEFT_a329_noRideHeightCalib "Left body controller: a329 no ride height calib";
CM_ SG_ 864 VCLEFT_a330_shortDropFailedF "Left body controller: a330 short drop failed f";
CM_ SG_ 864 VCLEFT_a331_shortDropFailedR "Left body controller: a331 short drop failed r";
CM_ SG_ 864 VCLEFT_a332_intrusionSensorMIA "Left body controller: a332 intrusion sensor MIA";
CM_ SG_ 864 VCLEFT_a333_overheadConsoleMIA "Left body controller: a333 overhead console MIA";
CM_ SG_ 864 VCLEFT_a334_overheadConsoleInter "Left body controller: a334 overhead console internal fault";
CM_ SG_ 864 VCLEFT_a335_intrusionSensorInter "Left body controller: a335 intrusion sensor internal fault";
CM_ SG_ 864 VCLEFT_a336_windowDropRevThermal "Left body controller: a336 window drop rev thermal f";
CM_ SG_ 864 VCLEFT_a337_windowDropRevThermal "Left body controller: a337 window drop rev thermal r";
CM_ SG_ 864 VCLEFT_a338_trailerLightControll "Left body controller: a338 trailer light controller MIA";
CM_ SG_ 864 VCLEFT_a339_trailerLeftTurnLight "Left body controller: a339 trailer left turn light not detected";
CM_ SG_ 864 VCLEFT_a340_trailerRightTurnLigh "Left body controller: a340 trailer right turn light not detected";
CM_ SG_ 864 VCLEFT_a341_trailerLightFault "Left body controller: a341 trailer light fault";
CM_ SG_ 864 VCLEFT_a342_trailerLightControll "Left body controller: a342 trailer light controller fault";
CM_ SG_ 864 VCLEFT_a345_chargePortPowerCycli "Left body controller: a345 charge port power cycling";
CM_ SG_ 864 VCLEFT_a346_eFuseMgmtVbatFused2 "Left body controller: a346 e fuse mgmt vbat fused2";
CM_ SG_ 864 VCLEFT_a347_nonContMonitorCleare "Left body controller: a347 non cont monitor cleared DBG";
CM_ SG_ 864 VCLEFT_a348_CPSleepOvercurrent "Left body controller: a348 CP sleep overcurrent";
CM_ SG_ 864 VCLEFT_a349_CPSleepUndervoltage "Left body controller: a349 CP sleep undervoltage";
CM_ SG_ 864 VCLEFT_a350_ensOutOfRange "Left body controller: a350 ens out of range";
CM_ SG_ 864 VCLEFT_a351_debugLiftgateCurrent "Left body controller: a351 debug liftgate current spike";
CM_ SG_ 864 VCLEFT_a352_liftgateClosingLatch "Left body controller: a352 liftgate closing latch entry failed";
CM_ SG_ 864 VCLEFT_a353_eFuseMgmtSteeringCol "Left body controller: a353 e fuse mgmt steering column";
CM_ SG_ 864 VCLEFT_a354_eFuseMgmtLiftGate "Left body controller: a354 e fuse mgmt lift gate";
CM_ SG_ 864 VCLEFT_a355_liftgateUnexpectedSt "Left body controller: a355 liftgate unexpected stop";
CM_ SG_ 864 VCLEFT_a356_liftgateFactoryTest "Left body controller: a356 liftgate factory test";
CM_ SG_ 864 VCLEFT_a357_liftgateUncalibrated "Left body controller: a357 liftgate uncalibrated";
CM_ SG_ 864 VCLEFT_a358_debugLiftgateCurrent "Left body controller: a358 debug liftgate current dropout";
CM_ SG_ 864 VCLEFT_a359_liftgateLatchExitNoP "Left body controller: a359 liftgate latch exit no position change";
CM_ SG_ 864 VCLEFT_a360_detectedStationaryWh "Left body controller: a360 detected stationary while moving";
CM_ SG_ 864 VCLEFT_a361_stationaryThresholds "Left body controller: a361 stationary thresholds incorrect";
CM_ SG_ 864 VCLEFT_a362_movingThresholdsInco "Left body controller: a362 moving thresholds incorrect";
CM_ SG_ 864 VCLEFT_a363_liftgateOpenAngleSet "Left body controller: a363 liftgate open angle set req";
CM_ SG_ 864 VCLEFT_a365_pitchUnlatchDisabled "Left body controller: a365 pitch unlatch disabled";
CM_ SG_ 864 VCLEFT_a366_liftgateLatchEntryDB "Left body controller: a366 liftgate latch entry DBG";
CM_ SG_ 864 VCLEFT_a370_seat2RowPitchUnlatch "Left body controller: a370 seat2 row pitch unlatched";
CM_ SG_ 864 VCLEFT_a371_seat2RowTrackUnlatch "Left body controller: a371 seat2 row track unlatched";
CM_ SG_ 864 VCLEFT_a372_seat2RowBackrestUnla "Left body controller: a372 seat2 row backrest unlatched";
CM_ SG_ 864 VCLEFT_a373_windowSwOpenReqInDog "Left body controller: a373 window sw open req in dog mode";
CM_ SG_ 864 VCLEFT_a374_trailerLightFaultMod "Left body controller: a374 trailer light fault model y";
CM_ SG_ 864 VCLEFT_a375_windowPinchOverrideN "Left body controller: a375 window pinch override nudge";
CM_ SG_ 864 VCLEFT_a376_seat2RowBridgeCurren "Left body controller: a376 seat2 row bridge current exceeded";
CM_ SG_ 864 VCLEFT_a380_steerColThermalLimit "Left body controller: a380 steer col thermal limited";
CM_ SG_ 864 VCLEFT_a381_pitchEstimation1 "Left body controller: a381 pitch estimation1";
CM_ SG_ 864 VCLEFT_a382_pitchEstimation2 "Left body controller: a382 pitch estimation2";
CM_ SG_ 864 VCLEFT_a383_steerColInOutMotorSt "Left body controller: a383 steer col in out motor stall current";
CM_ SG_ 864 VCLEFT_a384_steerColUpDownMotorS "Left body controller: a384 steer col up down motor stall current";
CM_ SG_ 864 VCLEFT_a385_steerColInOutMotorUn "Left body controller: a385 steer col in out motor under current";
CM_ SG_ 864 VCLEFT_a386_steerColUpDownMotorU "Left body controller: a386 steer col up down motor under current";
CM_ SG_ 864 VCLEFT_a387_steerColInOutMotorEn "Left body controller: a387 steer col in out motor encoder stalled";
CM_ SG_ 864 VCLEFT_a388_steerColUpDownMotorE "Left body controller: a388 steer col up down motor encoder stalled";
CM_ SG_ 864 VCLEFT_a389_steerColInOutEncoder "Left body controller: a389 steer col in out encoder out of range";
CM_ SG_ 864 VCLEFT_a390_steerColUpDownEncode "Left body controller: a390 steer col up down encoder out of range";
CM_ SG_ 864 VCLEFT_a391_pitchEstimationImpla "Left body controller: a391 pitch estimation implausible";
CM_ SG_ 864 VCLEFT_a392_pitchEstimationGPSIm "Left body controller: a392 pitch estimation GPS improved reinit";
CM_ SG_ 864 VCLEFT_a393_pitchEstimationNoGPS "Left body controller: a393 pitch estimation no GPS fusion";
CM_ SG_ 864 VCLEFT_a394_swsTouchTooNegativeD "Left body controller: a394 sws touch too negative delta";
CM_ SG_ 864 VCLEFT_a395_swsTouchAdcCheckFail "Left body controller: a395 sws touch adc check fail";
CM_ SG_ 864 VCLEFT_a396_swsTouchStuckFault "Left body controller: a396 sws touch stuck fault";
CM_ SG_ 864 VCLEFT_a397_swsTouchOutOfRangeFa "Left body controller: a397 sws touch out of range fault";
CM_ SG_ 864 VCLEFT_a398_swsTouchNvmFault "Left body controller: a398 sws touch nvm fault";
CM_ SG_ 864 VCLEFT_a399_swsTouchNoisyBaselin "Left body controller: a399 sws touch noisy baseline initialization";
CM_ SG_ 864 VCLEFT_a400_swsTouchDebouncedPro "Left body controller: a400 sws touch debounced processing error";
CM_ SG_ 864 VCLEFT_a401_swsForceTestPatternV "Left body controller: a401 sws force test pattern violation";
CM_ SG_ 864 VCLEFT_a402_swsForceOutOfRange "Left body controller: a402 sws force out of range";
CM_ SG_ 864 VCLEFT_a403_swsForceAdcCheckFail "Left body controller: a403 sws force adc check fail";
CM_ SG_ 864 VCLEFT_a404_swsForceI2cError "Left body controller: a404 sws force i2c error";
CM_ SG_ 864 VCLEFT_a405_swsForceCalibrationF "Left body controller: a405 sws force calibration fault";
CM_ SG_ 864 VCLEFT_a406_swsForceParametersFa "Left body controller: a406 sws force parameters fault";
CM_ SG_ 864 VCLEFT_a407_swsForceNvmFault "Left body controller: a407 sws force nvm fault";
CM_ SG_ 864 VCLEFT_a408_swsForceTouchSensorF "Left body controller: a408 sws force touch sensor fault";
CM_ SG_ 864 VCLEFT_a409_swsScrollWheelPushFa "Left body controller: a409 sws scroll wheel push fault";
CM_ SG_ 864 VCLEFT_a410_swsScrollWheelTiltFa "Left body controller: a410 sws scroll wheel tilt fault";
CM_ SG_ 864 VCLEFT_a411_swsScrollWheelScroll "Left body controller: a411 sws scroll wheel scroll fault";
CM_ SG_ 864 VCLEFT_a412_leftBrakeTailLightFa "Left body controller: a412 left brake tail light fault";
CM_ SG_ 864 VCLEFT_a414_swsHapticMotorFault "Left body controller: a414 sws haptic motor fault";
CM_ SG_ 864 VCLEFT_a415_swsMiscFault "Left body controller: a415 sws misc fault";
CM_ SG_ 864 VCLEFT_a416_fohmTouchAdcCheckFai "Left body controller: a416 fohm touch adc check fail";
CM_ SG_ 864 VCLEFT_a417_fohmTouchOutOfRangeF "Left body controller: a417 fohm touch out of range fault";
CM_ SG_ 864 VCLEFT_a418_fohmTouchVarianceFai "Left body controller: a418 fohm touch variance fail";
CM_ SG_ 864 VCLEFT_a419_fohmTouchStuck "Left body controller: a419 fohm touch stuck";
CM_ SG_ 864 VCLEFT_a420_fohmTouchSensorsImpl "Left body controller: a420 fohm touch sensors implausible";
CM_ SG_ 864 VCLEFT_a421_fohmForceOutOfRangeF "Left body controller: a421 fohm force out of range fault";
CM_ SG_ 864 VCLEFT_a423_fohmForceI2cError "Left body controller: a423 fohm force i2c error";
CM_ SG_ 864 VCLEFT_a424_fohmAmberLEDFault "Left body controller: a424 fohm amber LED fault";
CM_ SG_ 864 VCLEFT_a425_fohmVanityPowerSuppl "Left body controller: a425 fohm vanity power supply fault";
CM_ SG_ 864 VCLEFT_a426_seatAbuseMotorWarn "Left body controller: a426 seat abuse motor warn";
CM_ SG_ 864 VCLEFT_a427_seatAbuseMotorStop "Left body controller: a427 seat abuse motor stop";
CM_ SG_ 864 VCLEFT_a428_seatAbuseBufferWarn "Left body controller: a428 seat abuse buffer warn";
CM_ SG_ 864 VCLEFT_a429_seatAbuseBufferFull "Left body controller: a429 seat abuse buffer full";
CM_ SG_ 864 VCLEFT_a430_fohmRearDomeLightPow "Left body controller: a430 fohm rear dome light power supply fault";
CM_ SG_ 864 VCLEFT_a431_fohmVbatFault "Left body controller: a431 fohm vbat fault";
CM_ SG_ 864 VCLEFT_a432_fohmMiscFault "Left body controller: a432 fohm misc fault";
CM_ SG_ 864 VCLEFT_a433_fohmForceCalibration "Left body controller: a433 fohm force calibration invalid";
CM_ SG_ 864 VCLEFT_a434_swsScrollWheelPushDa "Left body controller: a434 sws scroll wheel push data";
CM_ SG_ 864 VCLEFT_a435_swsNoReasonTouchFaul "Left body controller: a435 sws no reason touch fault";
CM_ SG_ 864 VCLEFT_a436_swsNoReasonForceFaul "Left body controller: a436 sws no reason force fault";
CM_ SG_ 864 VCLEFT_a437_hvacRearLeftVertical "Left body controller: a437 hvac rear left vertical driver faulted";
CM_ SG_ 864 VCLEFT_a438_hvacRearLeftLateralD "Left body controller: a438 hvac rear left lateral driver faulted";
CM_ SG_ 864 VCLEFT_a439_hvacRearRightVertica "Left body controller: a439 hvac rear right vertical driver faulted";
CM_ SG_ 864 VCLEFT_a440_hvacRearRightLateral "Left body controller: a440 hvac rear right lateral driver faulted";
CM_ SG_ 864 VCLEFT_a441_prndMIA "Left body controller: a441 prnd MIA";
CM_ SG_ 864 VCLEFT_a442_swsLongTouchEvent "Left body controller: a442 sws long touch event";
CM_ SG_ 864 VCLEFT_a444_drv8703Fault "Left body controller: a444 drv8703 fault";
CM_ SG_ 864 VCLEFT_a445_drv8703SpiFaultDBG "Left body controller: a445 drv8703 spi fault DBG";
CM_ SG_ 864 VCLEFT_a446_trailerAuxReversePow "Left body controller: a446 trailer aux reverse power";
CM_ SG_ 864 VCLEFT_a447_steeringColInOutEnds "Left body controller: a447 steering col in out endstop cal";
CM_ SG_ 864 VCLEFT_a448_steeringColUpDownEnd "Left body controller: a448 steering col up down endstop cal";
CM_ SG_ 864 VCLEFT_a451_wirelessChargerMIA "Left body controller: a451 wireless charger MIA";
CM_ SG_ 864 VCLEFT_a453_liftgatePinchDetecte "Left body controller: a453 liftgate pinch detected";
CM_ SG_ 864 VCLEFT_a454_wirelessChargerFault "Left body controller: a454 wireless charger fault";
CM_ SG_ 864 VCLEFT_a455_liftgateUnexpectedSh "Left body controller: a455 liftgate unexpected shutface sw pressed";
CM_ SG_ 864 VCLEFT_a460_etcDebug "Left body controller: a460 etc debug";
CM_ SG_ 864 VCLEFT_a466_hvac2RLeftAirwaveVer "Left body controller: a466 hvac2 r left airwave vertical fault";
CM_ SG_ 864 VCLEFT_a467_hvac2RLeftAirwaveVer "Left body controller: a467 hvac2 r left airwave vertical warning";
CM_ SG_ 864 VCLEFT_a468_hvac2RLeftAirwaveVer "Left body controller: a468 hvac2 r left airwave vertical uncalib";
CM_ SG_ 864 VCLEFT_a469_hvac2RLeftAirwaveLat "Left body controller: a469 hvac2 r left airwave lateral fault";
CM_ SG_ 864 VCLEFT_a470_hvac2RLeftAirwaveLat "Left body controller: a470 hvac2 r left airwave lateral warning";
CM_ SG_ 864 VCLEFT_a471_hvac2RLeftAirwaveLat "Left body controller: a471 hvac2 r left airwave lateral uncalib";
CM_ SG_ 864 VCLEFT_a472_hvac2RRightAirwaveVe "Left body controller: a472 hvac2 r right airwave vertical fault";
CM_ SG_ 864 VCLEFT_a473_hvac2RRightAirwaveVe "Left body controller: a473 hvac2 r right airwave vertical warning";
CM_ SG_ 864 VCLEFT_a474_hvac2RRightAirwaveVe "Left body controller: a474 hvac2 r right airwave vertical uncalib";
CM_ SG_ 864 VCLEFT_a475_hvac2RRightAirwaveLa "Left body controller: a475 hvac2 r right airwave lateral fault";
CM_ SG_ 864 VCLEFT_a476_hvac2RRightAirwaveLa "Left body controller: a476 hvac2 r right airwave lateral warning";
CM_ SG_ 864 VCLEFT_a477_hvac2RRightAirwaveLa "Left body controller: a477 hvac2 r right airwave lateral uncalib";
CM_ SG_ 864 VCLEFT_a478_BPillarCameraHeaterF "Left body controller: a478 b pillar camera heater fault";
CM_ SG_ 864 VCLEFT_a480_vnf1048Fault "Left body controller: a480 vnf1048 fault";
CM_ SG_ 864 VCLEFT_a481_vnf1048SelfTestFailu "Left body controller: a481 vnf1048 self test failure";
CM_ SG_ 864 VCLEFT_a482_NCV77XXFault "Left body controller: a482 NCV77 XX fault";
CM_ SG_ 864 VCLEFT_a490_vehicleOccupiedOnOTA "Left body controller: a490 vehicle occupied on OTA start";
CM_ SG_ 864 VCLEFT_a498_canAuthenticationFai "Left body controller: a498 can authentication failure";
CM_ SG_ 864 VCLEFT_a499_epbmInvalidateCdp "Left body controller: a499 epbm invalidate cdp";
CM_ SG_ 864 VCLEFT_a500_eFuseASICStateMismat "Left body controller: a500 e fuse ASIC state mismatch";
CM_ SG_ 864 VCLEFT_a501_vnf1048Configuration "Left body controller: a501 vnf1048 configuration mismatch";
CM_ SG_ 864 VCLEFT_a520_configMismatch "Left body controller: a520 config mismatch";
CM_ SG_ 864 VCLEFT_a521_seatHeatPadUnexpecte "Left body controller: a521 seat heat pad unexpected voltage";
CM_ SG_ 864 VCLEFT_a522_trailerLightUnexpect "Left body controller: a522 trailer light unexpected voltage";
CM_ SG_ 864 VCLEFT_a523_eFuseThresholdsIncor "Left body controller: a523 e fuse thresholds incorrect";
CM_ SG_ 864 VCLEFT_a525_LVBatterySWMisconfig "Left body controller: a525 LV battery SW misconfiguration";
CM_ SG_ 864 VCLEFT_a526_pcbaOverTemperature "Left body controller: a526 pcba over temperature";
CM_ SG_ 864 VCLEFT_a527_continuousFeedUnexpe "Left body controller: a527 continuous feed unexpected voltage";
CM_ SG_ 864 VCLEFT_a528_unableToRunStuckOnTe "Left body controller: a528 unable to run stuck on test";
CM_ SG_ 864 VCLEFT_a536_trunkFoldFlatSwitchF "Left body controller: a536 trunk fold flat switch fault";
CM_ SG_ 864 VCLEFT_a545_LVBatteryTypeUnknown "Left body controller: a545 LV battery type unknown";
CM_ SG_ 864 VCLEFT_a546_mirrorFoldTypeChange "Left body controller: a546 mirror fold type changed";
CM_ SG_ 864 VCLEFT_a550_ambientTempDelta "Left body controller: a550 ambient temp delta";
CM_ SG_ 864 VCLEFT_a551_interiorDoorRequestI "Left body controller: a551 interior door request inhibited";
CM_ SG_ 864 VCLEFT_a554_RCM2_MIA "Left body controller: a554 RCM2 MIA";
CM_ SG_ 864 VCLEFT_a555_steeringWheelHeaterC "Left body controller: a555 steering wheel heater compromised";
CM_ SG_ 864 VCLEFT_a560_2RowSeatUncalibrated "Left body controller: a560 2 row seat uncalibrated";
CM_ SG_ 864 VCLEFT_a561_2RowSeatPositionNons "Left body controller: a561 2 row seat position nonsensical";
CM_ SG_ 864 VCLEFT_a562_2RowSeatAbsPosOffset "Left body controller: a562 2 row seat abs pos offset applied";
CM_ SG_ 864 VCLEFT_a563_2RowSeatObstacleDete "Left body controller: a563 2 row seat obstacle detected";
CM_ SG_ 864 VCLEFT_a564_2RowSeatTempHigh "Left body controller: a564 2 row seat temp high";
CM_ SG_ 864 VCLEFT_a565_2RowSeatAbsPosSensor "Left body controller: a565 2 row seat abs pos sensor transition dbg";
CM_ SG_ 864 VCLEFT_a566_2RowSeatStatsFromLas "Left body controller: a566 2 row seat stats from last state dbg";
CM_ SG_ 864 VCLEFT_a567_2RowSeatRequestWhile "Left body controller: a567 2 row seat request while uncalibrated";
CM_ SG_ 864 VCLEFT_a568_2RowSeatClashAvoidan "Left body controller: a568 2 row seat clash avoidance blocked";
CM_ SG_ 864 VCLEFT_a569_2RowSeatOverfolded "Left body controller: a569 2 row seat overfolded";
CM_ SG_ 864 VCLEFT_a570_seatHeatDisabledF "Left body controller: a570 seat heat disabled f";
CM_ SG_ 864 VCLEFT_a571_seatHeatDisabledRear "Left body controller: a571 seat heat disabled rear l";
CM_ SG_ 864 VCLEFT_a572_seatHeatDisabledRear "Left body controller: a572 seat heat disabled rear c";
CM_ SG_ 864 VCLEFT_a573_seatHeatDisabledRear "Left body controller: a573 seat heat disabled rear r";
CM_ SG_ 864 VCLEFT_a576_liftgateStrutPositio "Left body controller: a576 liftgate strut position mismatch";
CM_ SG_ 864 VCLEFT_a577_bsiHardwareIssue "Left body controller: a577 bsi hardware issue";
CM_ SG_ 864 VCLEFT_a578_RGBLightFault "Left body controller: a578 RGB light fault";
CM_ SG_ 864 VCLEFT_a579_leftSteeringWheelCtr "Left body controller: a579 left steering wheel ctrl type mismatch";
CM_ SG_ 864 VCLEFT_a580_rightSteeringWheelCt "Left body controller: a580 right steering wheel ctrl type mismatch";
CM_ SG_ 864 VCLEFT_a581_reverseLightFault "Left body controller: a581 reverse light fault";
CM_ SG_ 864 VCLEFT_a583_doorRemoteUnlatchedF "Left body controller: a583 door remote unlatched front";
CM_ SG_ 864 VCLEFT_a584_doorRemoteUnlatchedR "Left body controller: a584 door remote unlatched rear";
CM_ SG_ 864 VCLEFT_a585_doorRemoteUnlatchFai "Left body controller: a585 door remote unlatch failed front";
CM_ SG_ 864 VCLEFT_a586_doorRemoteUnlatchFai "Left body controller: a586 door remote unlatch failed rear";
CM_ SG_ 864 VCLEFT_a599_LVBatteryTypeUnsuppo "Left body controller: a599 LV battery type unsupported";
CM_ SG_ 864 VCLEFT_a617_APP_MIA "Left body controller: a617 APP MIA";
CM_ BO_ 258 "Left body controller message: door status";
CM_ SG_ 258 VCLEFT_doorClosureStatusFront "Status of the door from a closures perspective; raw 0 = signal not available (SNA)";
CM_ SG_ 258 VCLEFT_doorClosureStatusRear "Status of the door from a closures perspective; raw 0 = signal not available (SNA)";
CM_ SG_ 258 VCLEFT_frontLatchSwitch "State of front left door latch switch representing door open/closed. 0 is open and 1 is closed";
CM_ SG_ 258 VCLEFT_rearLatchSwitch "State of rear left door latch switch representing door open/closed. 0 is open and 1 is closed";
CM_ SG_ 258 VCLEFT_frontHandlePulled "Left body controller: front handle pulled";
CM_ SG_ 258 VCLEFT_rearHandlePulled "Left body controller: rear handle pulled";
CM_ SG_ 258 VCLEFT_frontRelActuatorSwitch "State of front left door latch switch representing latch arm/unarmed. Disarms while door handle is pulled.";
CM_ SG_ 258 VCLEFT_rearRelActuatorSwitch "State of rear left door latch switch representing latch arm/unarmed. Disarms while door handle is pulled";
CM_ SG_ 258 VCLEFT_frontLatchStatus "Status of left front door latch; raw 0 = signal not available (SNA)";
CM_ SG_ 258 VCLEFT_rearLatchStatus "Status of rear left door latch; raw 0 = signal not available (SNA)";
CM_ SG_ 258 VCLEFT_lastDoorReqSourceFront "last source of front door open request";
CM_ SG_ 258 VCLEFT_lastDoorReqSourceRear "last source of rear door open request";
CM_ SG_ 258 VCLEFT_frontIntSwitchPressed "Left body controller: front int switch pressed";
CM_ SG_ 258 VCLEFT_rearIntSwitchPressed "Left body controller: rear int switch pressed";
CM_ SG_ 258 VCLEFT_mirrorTiltXPosition "Value representing left side view mirror tilt horizontal position";
CM_ SG_ 258 VCLEFT_mirrorTiltYPosition "Value representing left side view mirror tilt vertical position";
CM_ SG_ 258 VCLEFT_mirrorState "State of the left side view mirror.";
CM_ SG_ 258 VCLEFT_mirrorFoldState "Fold state for the left side view mirror";
CM_ SG_ 258 VCLEFT_mirrorRecallState "State of Mirror Recall.";
CM_ SG_ 258 VCLEFT_mirrorHeatState "Left body controller: mirror heat state; raw 0 = signal not available (SNA)";
CM_ SG_ 258 VCLEFT_rearHandlePulledPersist "Left body controller: rear handle pulled persist";
CM_ SG_ 258 VCLEFT_frontHandlePulledPersist "Left body controller: front handle pulled persist";
CM_ SG_ 258 VCLEFT_mirrorDipped "Reports if the side view mirrors in are in the dipped position.";
CM_ BO_ 626 "Left body controller message: epbm debug";
CM_ SG_ 626 VCLEFT_epbmDebugIndex "Left body controller: epbm debug index";
CM_ SG_ 626 VCLEFT_epbmCaliperState "Left body controller: epbm caliper state";
CM_ SG_ 626 VCLEFT_epbmMotorEnabled "Left body controller: epbm motor enabled";
CM_ SG_ 626 VCLEFT_epbMotorCurrent "Left body controller: epb motor current";
CM_ SG_ 626 VCLEFT_epbmApplyVoltage "Left body controller: epbm apply voltage";
CM_ SG_ 626 VCLEFT_epbmReleaseVoltage "Left body controller: epbm release voltage";
CM_ SG_ 626 VCLEFT_summonFaultReason "Electronic Parking Brake Monitors error code associated with previous summon failure.";
CM_ SG_ 626 VCLEFT_epbSummonState "Electronic Parking Brake Monitors reading of Electronic Parking Brake's summon state.";
CM_ SG_ 626 VCLEFT_epbmSummonState "Electronic Parking Brake Monitors summon state.";
CM_ SG_ 626 VCLEFT_epbUnitStatus "Electronic Parking Brake Monitors reading of Electronic Parking Brake's state.";
CM_ SG_ 626 VCLEFT_epbmFaultStatus "Electronic Parking Brake Monitors fault state.";
CM_ SG_ 626 VCLEFT_epbFaultStatus "Electronic Parking Brake Monitors reading of Electronic Parking Brake's fault state.";
CM_ SG_ 626 VCLEFT_epbmSystemStatus "Electronic Parking Brake Monitors reading of Electronic Parking Brake's state.";
CM_ BO_ 1140 "Left body controller message: epbm status";
CM_ SG_ 1140 VCLEFT_cdpRequestState "If the Electronic Parking Brake makes a Controlled Deceleration for Parking Brake request, when cdpOkayToRequest is EPB_CDP_REQUEST_INVALID, cdpRequestState shall transition to EPB_CDP_REQUEST_INVALID, untill the Electronic Parking Brake Monitor enters unitStatus PARKED. Stability Control listens to this signal to qualify Controlled Deceleration for Parking Brake requests from the Electronic Parking Brake.";
CM_ SG_ 1140 VCLEFT_epbmSystemStatusQF "Left body controller: epbm system status QF";
CM_ SG_ 1140 VCLEFT_epbmUnitStatus "Electronic Parking Brake Monitors state.";
CM_ SG_ 1140 VCLEFT_epbmCdpState "Left body controller: epbm cdp state";
CM_ SG_ 1140 VCLEFT_epbmStatusCounter "Left body controller: epbm status counter";
CM_ SG_ 1140 VCLEFT_epbmStatusChecksum "Left body controller: epbm status checksum";
CM_ BO_ 770 "Left body controller message: info";
CM_ SG_ 770 VCLEFT_infoIndex "Left body controller: info index";
CM_ SG_ 770 VCLEFT_infoBuildType "Left body controller: info build type";
CM_ SG_ 770 VCLEFT_infoBuildConfigId "Left body controller: info build config id";
CM_ SG_ 770 VCLEFT_infoHardwareId "Left body controller: info hardware id";
CM_ SG_ 770 VCLEFT_infoComponentId "Left body controller: info component id";
CM_ SG_ 770 VCLEFT_infoPcbaId "Left body controller: info pcba id";
CM_ SG_ 770 VCLEFT_infoAssemblyId "Left body controller: info assembly id; raw 255 = signal not available (SNA)";
CM_ SG_ 770 VCLEFT_infoUsageId "Left body controller: info usage id";
CM_ SG_ 770 VCLEFT_infoSubUsageId "Left body controller: info sub usage id";
CM_ SG_ 770 VCLEFT_infoAppCrc "Left body controller: info app crc";
CM_ SG_ 770 VCLEFT_infoAppGitHash "Left body controller: info app git hash";
CM_ SG_ 770 VCLEFT_infoBootGitHash "Left body controller: info boot git hash";
CM_ SG_ 770 VCLEFT_infoPlatformType "Left body controller: info platform type";
CM_ SG_ 770 VCLEFT_infoBootUdsProtoVersion "Left body controller: info boot uds proto version";
CM_ SG_ 770 VCLEFT_infoBootCrc "Left body controller: info boot crc";
BA_DEF_ BO_ "GenMsgCycleTime" INT 0 3600000;
BA_DEF_ BO_ "GenMsgSendType" ENUM "Cyclic","NotUsed","NotUsed","NotUsed","NotUsed","NotUsed","NotUsed","IfActive","NoMsgSendType","NotUsed";
BA_DEF_ BO_ "VFrameFormat" ENUM "StandardCAN","ExtendedCAN","reserved","J1939PG","reserved","reserved","reserved","reserved","reserved","reserved","reserved","reserved","reserved","reserved","StandardCAN_FD","ExtendedCAN_FD";
BA_DEF_ BO_ "CANFD_BRS" ENUM "0","1";
BA_DEF_ SG_ "GenSigSNA" STRING;
BA_DEF_ SG_ "SystemSignalLongSymbol" STRING;
BA_DEF_ SG_ "Confidence" ENUM "validated","plausible","layout-only","contradicted";
BA_DEF_DEF_ "GenMsgCycleTime" 0;
BA_DEF_DEF_ "GenMsgSendType" "NoMsgSendType";
BA_DEF_DEF_ "VFrameFormat" "StandardCAN";
BA_DEF_DEF_ "CANFD_BRS" "1";
BA_DEF_DEF_ "GenSigSNA" "";
BA_DEF_DEF_ "SystemSignalLongSymbol" "";
BA_DEF_DEF_ "Confidence" "layout-only";
BA_ "GenMsgCycleTime" BO_ 864 100;
BA_ "GenMsgSendType" BO_ 864 0;
BA_ "GenMsgCycleTime" BO_ 258 100;
BA_ "GenMsgSendType" BO_ 258 0;
BA_ "GenMsgCycleTime" BO_ 626 100;
BA_ "GenMsgSendType" BO_ 626 0;
BA_ "GenMsgCycleTime" BO_ 1140 100;
BA_ "GenMsgSendType" BO_ 1140 0;
BA_ "GenMsgCycleTime" BO_ 770 1000;
BA_ "GenMsgSendType" BO_ 770 0;
BA_ "SystemSignalLongSymbol" SG_ 2013 VCLEFT_a404_rightSteeringWheelSw "VCLEFT_a404_rightSteeringWheelSwitch";
BA_ "SystemSignalLongSymbol" SG_ 2013 VCLEFT_a405_leftSteeringWheelSwi "VCLEFT_a405_leftSteeringWheelSwitch";
BA_ "SystemSignalLongSymbol" SG_ 2013 VCLEFT_a405_rightSteeringWheelSw "VCLEFT_a405_rightSteeringWheelSwitch";
BA_ "SystemSignalLongSymbol" SG_ 2013 VCLEFT_a406_leftSteeringWheelSwi "VCLEFT_a406_leftSteeringWheelSwitch";
BA_ "SystemSignalLongSymbol" SG_ 2013 VCLEFT_a406_rightSteeringWheelSw "VCLEFT_a406_rightSteeringWheelSwitch";
BA_ "SystemSignalLongSymbol" SG_ 2013 VCLEFT_a407_leftSteeringWheelSwi "VCLEFT_a407_leftSteeringWheelSwitch";
BA_ "SystemSignalLongSymbol" SG_ 2013 VCLEFT_a407_rightSteeringWheelSw "VCLEFT_a407_rightSteeringWheelSwitch";
BA_ "SystemSignalLongSymbol" SG_ 2013 VCLEFT_a409_rightScrollWheelFaul "VCLEFT_a409_rightScrollWheelFault";
BA_ "SystemSignalLongSymbol" SG_ 2013 VCLEFT_a409_rightScrollWheelPrev "VCLEFT_a409_rightScrollWheelPrevious";
BA_ "SystemSignalLongSymbol" SG_ 2013 VCLEFT_a409_rightScrollWheelChal "VCLEFT_a409_rightScrollWheelChallenge";
BA_ "SystemSignalLongSymbol" SG_ 2013 VCLEFT_a410_rightScrollWheelFaul "VCLEFT_a410_rightScrollWheelFault";
BA_ "SystemSignalLongSymbol" SG_ 2013 VCLEFT_a411_rightScrollWheelFaul "VCLEFT_a411_rightScrollWheelFault";
BA_ "SystemSignalLongSymbol" SG_ 2013 VCLEFT_a414_rightHapticMotorFaul "VCLEFT_a414_rightHapticMotorFault";
BA_ "SystemSignalLongSymbol" SG_ 2013 VCLEFT_a415_leftVbatUndervoltage "VCLEFT_a415_leftVbatUndervoltageFault";
BA_ "SystemSignalLongSymbol" SG_ 2013 VCLEFT_a415_rightVbatUndervoltag "VCLEFT_a415_rightVbatUndervoltageFault";
BA_ "SystemSignalLongSymbol" SG_ 2013 VCLEFT_a415_leftVbatOvervoltageF "VCLEFT_a415_leftVbatOvervoltageFault";
BA_ "SystemSignalLongSymbol" SG_ 2013 VCLEFT_a415_rightVbatOvervoltage "VCLEFT_a415_rightVbatOvervoltageFault";
BA_ "SystemSignalLongSymbol" SG_ 2013 VCLEFT_a425_rightVisorLightStatu "VCLEFT_a425_rightVisorLightStatus";
BA_ "Confidence" SG_ 2013 VCLEFT_a426_seatMotorCurrent 1;
BA_ "Confidence" SG_ 2013 VCLEFT_a426_seatMotorPosReal 1;
BA_ "Confidence" SG_ 2013 VCLEFT_a426_seatMotorState 1;
BA_ "Confidence" SG_ 2013 VCLEFT_a426_seatSwitchBack 1;
BA_ "GenSigSNA" SG_ 2013 VCLEFT_a426_seatSwitchBack "0";
BA_ "Confidence" SG_ 2013 VCLEFT_a426_seatSwitchForward 1;
BA_ "GenSigSNA" SG_ 2013 VCLEFT_a426_seatSwitchForward "0";
BA_ "Confidence" SG_ 2013 VCLEFT_a426_cabinTmp 1;
BA_ "Confidence" SG_ 2013 VCLEFT_a427_seatMotorCurrent 1;
BA_ "Confidence" SG_ 2013 VCLEFT_a427_seatMotorPosReal 1;
BA_ "Confidence" SG_ 2013 VCLEFT_a427_seatMotorState 1;
BA_ "Confidence" SG_ 2013 VCLEFT_a427_seatSwitchBack 1;
BA_ "GenSigSNA" SG_ 2013 VCLEFT_a427_seatSwitchBack "0";
BA_ "Confidence" SG_ 2013 VCLEFT_a427_seatSwitchForward 1;
BA_ "GenSigSNA" SG_ 2013 VCLEFT_a427_seatSwitchForward "0";
BA_ "Confidence" SG_ 2013 VCLEFT_a427_cabinTmp 1;
BA_ "Confidence" SG_ 2013 VCLEFT_a428_seatMotorCurrent 1;
BA_ "Confidence" SG_ 2013 VCLEFT_a428_seatMotorPosReal 1;
BA_ "Confidence" SG_ 2013 VCLEFT_a428_seatMotorState 1;
BA_ "Confidence" SG_ 2013 VCLEFT_a428_seatSwitchBack 1;
BA_ "GenSigSNA" SG_ 2013 VCLEFT_a428_seatSwitchBack "0";
BA_ "Confidence" SG_ 2013 VCLEFT_a428_seatSwitchForward 1;
BA_ "GenSigSNA" SG_ 2013 VCLEFT_a428_seatSwitchForward "0";
BA_ "Confidence" SG_ 2013 VCLEFT_a428_cabinTmp 1;
BA_ "Confidence" SG_ 2013 VCLEFT_a429_seatMotorCurrent 1;
BA_ "Confidence" SG_ 2013 VCLEFT_a429_seatMotorPosReal 1;
BA_ "Confidence" SG_ 2013 VCLEFT_a429_seatMotorState 1;
BA_ "Confidence" SG_ 2013 VCLEFT_a429_seatSwitchBack 1;
BA_ "GenSigSNA" SG_ 2013 VCLEFT_a429_seatSwitchBack "0";
BA_ "Confidence" SG_ 2013 VCLEFT_a429_seatSwitchForward 1;
BA_ "GenSigSNA" SG_ 2013 VCLEFT_a429_seatSwitchForward "0";
BA_ "Confidence" SG_ 2013 VCLEFT_a429_cabinTmp 1;
BA_ "SystemSignalLongSymbol" SG_ 2013 VCLEFT_a430_leftRearDomeLightPow "VCLEFT_a430_leftRearDomeLightPowerSupplyStatus";
BA_ "SystemSignalLongSymbol" SG_ 2013 VCLEFT_a430_rightRearDomeLightPo "VCLEFT_a430_rightRearDomeLightPowerSupplyStatus";
BA_ "Confidence" SG_ 2013 VCLEFT_a447_endstopPositionMM 1;
BA_ "Confidence" SG_ 2013 VCLEFT_a447_motorType 1;
BA_ "Confidence" SG_ 2013 VCLEFT_a448_endstopPositionMM 1;
BA_ "Confidence" SG_ 2013 VCLEFT_a448_motorType 1;
BA_ "Confidence" SG_ 2013 VCLEFT_a453_liftgatePosition 1;
BA_ "Confidence" SG_ 2013 VCLEFT_a455_liftgateState 1;
BA_ "SystemSignalLongSymbol" SG_ 2013 VCLEFT_a466_hvac2RLeftAirwaveVer "VCLEFT_a466_hvac2RLeftAirwaveVerticalStall";
BA_ "SystemSignalLongSymbol" SG_ 2013 VCLEFT_a469_hvac2RLeftAirwaveLat "VCLEFT_a469_hvac2RLeftAirwaveLateralStall";
BA_ "SystemSignalLongSymbol" SG_ 2013 VCLEFT_a472_hvac2RRightAirwaveVe "VCLEFT_a472_hvac2RRightAirwaveVerticalStall";
BA_ "SystemSignalLongSymbol" SG_ 2013 VCLEFT_a475_hvac2RRightAirwaveLa "VCLEFT_a475_hvac2RRightAirwaveLateralStall";
BA_ "SystemSignalLongSymbol" SG_ 2013 VCLEFT_a480_deviceOvertemperatur "VCLEFT_a480_deviceOvertemperature";
BA_ "SystemSignalLongSymbol" SG_ 2013 VCLEFT_a482_underOrOverVoltageOr "VCLEFT_a482_underOrOverVoltageOrOverCurrent";
BA_ "Confidence" SG_ 2013 VCLEFT_a500_mismatchedState 1;
BA_ "Confidence" SG_ 2013 VCLEFT_a520_epbConfig 1;
BA_ "Confidence" SG_ 2013 VCLEFT_a520_gtwEpbConfig 1;
BA_ "Confidence" SG_ 2013 VCLEFT_a525_GTW_twelveVBatteryTy 1;
BA_ "SystemSignalLongSymbol" SG_ 2013 VCLEFT_a525_GTW_twelveVBatteryTy "VCLEFT_a525_GTW_twelveVBatteryType";
BA_ "Confidence" SG_ 2013 VCLEFT_a525_newLVBatteryType 1;
BA_ "Confidence" SG_ 2013 VCLEFT_a525_initialLVBatteryType 1;
BA_ "Confidence" SG_ 2013 VCLEFT_a536_trunkFoldFlatSwitchS 1;
BA_ "GenSigSNA" SG_ 2013 VCLEFT_a536_trunkFoldFlatSwitchS "0";
BA_ "SystemSignalLongSymbol" SG_ 2013 VCLEFT_a536_trunkFoldFlatSwitchS "VCLEFT_a536_trunkFoldFlatSwitchState";
BA_ "Confidence" SG_ 2013 VCLEFT_a536_trunkFoldFlatLeftSwi 1;
BA_ "SystemSignalLongSymbol" SG_ 2013 VCLEFT_a536_trunkFoldFlatLeftSwi "VCLEFT_a536_trunkFoldFlatLeftSwitchVoltage";
BA_ "Confidence" SG_ 2013 VCLEFT_a545_GTW_twelveVBatteryTy 1;
BA_ "SystemSignalLongSymbol" SG_ 2013 VCLEFT_a545_GTW_twelveVBatteryTy "VCLEFT_a545_GTW_twelveVBatteryType";
BA_ "Confidence" SG_ 2013 VCLEFT_a545_newLVBatteryType 1;
BA_ "SystemSignalLongSymbol" SG_ 2013 VCLEFT_a551_restrictDoorReleaseS "VCLEFT_a551_restrictDoorReleaseSignalFront";
BA_ "SystemSignalLongSymbol" SG_ 2013 VCLEFT_a551_interiorReleaseReqCo "VCLEFT_a551_interiorReleaseReqCountFront";
BA_ "SystemSignalLongSymbol" SG_ 2013 VCLEFT_a551_lastRequestSourceFro "VCLEFT_a551_lastRequestSourceFront";
BA_ "SystemSignalLongSymbol" SG_ 2013 VCLEFT_a551_restrictDoorRel_0001 "VCLEFT_a551_restrictDoorReleaseSignalRear";
BA_ "SystemSignalLongSymbol" SG_ 2013 VCLEFT_a551_interiorRelease_0001 "VCLEFT_a551_interiorReleaseReqCountRear";
BA_ "SystemSignalLongSymbol" SG_ 2013 VCLEFT_a551_lastRequestSourceRea "VCLEFT_a551_lastRequestSourceRear";
BA_ "SystemSignalLongSymbol" SG_ 2013 VCLEFT_a560_isRearwardEndstopUnc "VCLEFT_a560_isRearwardEndstopUncalibrated";
BA_ "SystemSignalLongSymbol" SG_ 2013 VCLEFT_a560_isAbsPosSensorUncali "VCLEFT_a560_isAbsPosSensorUncalibrated";
BA_ "Confidence" SG_ 2013 VCLEFT_a560_seatState 1;
BA_ "GenSigSNA" SG_ 2013 VCLEFT_a560_seatState "15";
BA_ "Confidence" SG_ 2013 VCLEFT_a560_motorType 1;
BA_ "Confidence" SG_ 2013 VCLEFT_a560_absPosSensState 1;
BA_ "Confidence" SG_ 2013 VCLEFT_a563_angle 1;
BA_ "Confidence" SG_ 2013 VCLEFT_a563_seatStatePrev 1;
BA_ "GenSigSNA" SG_ 2013 VCLEFT_a563_seatStatePrev "15";
BA_ "Confidence" SG_ 2013 VCLEFT_a563_obstacleDetectReason 1;
BA_ "SystemSignalLongSymbol" SG_ 2013 VCLEFT_a563_accelLookbackTripDep "VCLEFT_a563_accelLookbackTripDepth";
BA_ "Confidence" SG_ 2013 VCLEFT_a563_duty 1;
BA_ "Confidence" SG_ 2013 VCLEFT_a563_currentAbsFilt 1;
BA_ "Confidence" SG_ 2013 VCLEFT_a563_motorType 1;
BA_ "SystemSignalLongSymbol" SG_ 2013 VCLEFT_a563_absolutePosSensorFor "VCLEFT_a563_absolutePosSensorForward";
BA_ "Confidence" SG_ 2013 VCLEFT_a563_cabinTemp 1;
BA_ "SystemSignalLongSymbol" SG_ 2013 VCLEFT_a567_isRearwardEndstopUnc "VCLEFT_a567_isRearwardEndstopUncalibrated";
BA_ "SystemSignalLongSymbol" SG_ 2013 VCLEFT_a567_isAbsPosSensorUncali "VCLEFT_a567_isAbsPosSensorUncalibrated";
BA_ "Confidence" SG_ 2013 VCLEFT_a568_seatState 1;
BA_ "GenSigSNA" SG_ 2013 VCLEFT_a568_seatState "15";
BA_ "Confidence" SG_ 2013 VCLEFT_a570_seatHeatCurrent 1;
BA_ "Confidence" SG_ 2013 VCLEFT_a570_seatHeatTmp 1;
BA_ "Confidence" SG_ 2013 VCLEFT_a571_seatHeatCurrent 1;
BA_ "Confidence" SG_ 2013 VCLEFT_a571_seatHeatTmp 1;
BA_ "Confidence" SG_ 2013 VCLEFT_a572_seatHeatCurrent 1;
BA_ "Confidence" SG_ 2013 VCLEFT_a572_seatHeatTmp 1;
BA_ "Confidence" SG_ 2013 VCLEFT_a573_seatHeatCurrent 1;
BA_ "Confidence" SG_ 2013 VCLEFT_a573_seatHeatTmp 1;
BA_ "Confidence" SG_ 2013 VCLEFT_a579_gtwConfigType 1;
BA_ "Confidence" SG_ 2013 VCLEFT_a580_gtwConfigType 1;
BA_ "Confidence" SG_ 2013 VCLEFT_a585_ambientTemp 1;
BA_ "GenSigSNA" SG_ 2013 VCLEFT_a585_ambientTemp "0";
BA_ "Confidence" SG_ 2013 VCLEFT_a586_ambientTemp 1;
BA_ "GenSigSNA" SG_ 2013 VCLEFT_a586_ambientTemp "0";
BA_ "Confidence" SG_ 2013 VCLEFT_a599_GTW_twelveVBatteryTy 1;
BA_ "SystemSignalLongSymbol" SG_ 2013 VCLEFT_a599_GTW_twelveVBatteryTy "VCLEFT_a599_GTW_twelveVBatteryType";
BA_ "Confidence" SG_ 2013 VCLEFT_a599_newLVBatteryType 1;
BA_ "Confidence" SG_ 2013 VCLEFT_a599_initialLVBatteryType 1;
BA_ "Confidence" SG_ 864 VCLEFT_matrixIndex 1;
BA_ "Confidence" SG_ 864 VCLEFT_a001_WatchdogReset 1;
BA_ "Confidence" SG_ 864 VCLEFT_a002_PowerLossReset 1;
BA_ "Confidence" SG_ 864 VCLEFT_a003_SWAssertion 1;
BA_ "Confidence" SG_ 864 VCLEFT_a005_CANTXError 1;
BA_ "Confidence" SG_ 864 VCLEFT_a006_CANTX_cyclicError 1;
BA_ "Confidence" SG_ 864 VCLEFT_a010_ExtSupplyVoltError 1;
BA_ "Confidence" SG_ 864 VCLEFT_a012_CPUReset 1;
BA_ "Confidence" SG_ 864 VCLEFT_a013_AlertManagerFault 1;
BA_ "Confidence" SG_ 864 VCLEFT_a015_NVMMError 1;
BA_ "Confidence" SG_ 864 VCLEFT_a016_NVMMRecordError 1;
BA_ "Confidence" SG_ 864 VCLEFT_a017_NVMMStatusDbg 1;
BA_ "Confidence" SG_ 864 VCLEFT_a021_TaskSchedulerError 1;
BA_ "Confidence" SG_ 864 VCLEFT_a022_TaskInitError 1;
BA_ "Confidence" SG_ 864 VCLEFT_a029_CoreDump 1;
BA_ "Confidence" SG_ 864 VCLEFT_a030_ECULogUploadRequest 1;
BA_ "Confidence" SG_ 864 VCLEFT_a031_UDSActive 1;
BA_ "Confidence" SG_ 864 VCLEFT_a041_HighCPULoad 1;
BA_ "Confidence" SG_ 864 VCLEFT_a042_HighStackUsage 1;
BA_ "Confidence" SG_ 864 VCLEFT_a043_Task1msError 1;
BA_ "Confidence" SG_ 864 VCLEFT_a044_Task10msError 1;
BA_ "Confidence" SG_ 864 VCLEFT_a045_Task100msError 1;
BA_ "Confidence" SG_ 864 VCLEFT_a046_Task1000msError 1;
BA_ "Confidence" SG_ 864 VCLEFT_a057_HVP_MIA 1;
BA_ "Confidence" SG_ 864 VCLEFT_a058_inputRHighSyncDebug 1;
BA_ "Confidence" SG_ 864 VCLEFT_a059_inputResistanceHigh 1;
BA_ "Confidence" SG_ 864 VCLEFT_a060_engineeringBuild 1;
BA_ "Confidence" SG_ 864 VCLEFT_a061_XCPConnected 1;
BA_ "Confidence" SG_ 864 VCLEFT_a062_XCPWasConnected 1;
BA_ "Confidence" SG_ 864 VCLEFT_a063_SwitchFault 1;
BA_ "Confidence" SG_ 864 VCLEFT_a064_busSleepReqTimeout 1;
BA_ "Confidence" SG_ 864 VCLEFT_a065_emiosIsrRateLimitedD 1;
BA_ "SystemSignalLongSymbol" SG_ 864 VCLEFT_a065_emiosIsrRateLimitedD "VCLEFT_a065_emiosIsrRateLimitedDbg";
BA_ "Confidence" SG_ 864 VCLEFT_a066_emiosIsrShortPeriodD 1;
BA_ "SystemSignalLongSymbol" SG_ 864 VCLEFT_a066_emiosIsrShortPeriodD "VCLEFT_a066_emiosIsrShortPeriodDetectedDbg";
BA_ "Confidence" SG_ 864 VCLEFT_a082_VCRIGHT_IPC_MIA 1;
BA_ "Confidence" SG_ 864 VCLEFT_a083_VCLEFT_IPC_MIA 1;
BA_ "Confidence" SG_ 864 VCLEFT_a084_TPMS_MIA 1;
BA_ "Confidence" SG_ 864 VCLEFT_a085_CCCM_MIA 1;
BA_ "Confidence" SG_ 864 VCLEFT_a086_VCBATT_MIA 1;
BA_ "Confidence" SG_ 864 VCLEFT_a087_DIREL_MIA 1;
BA_ "Confidence" SG_ 864 VCLEFT_a088_DIRER_MIA 1;
BA_ "Confidence" SG_ 864 VCLEFT_a089_IBST_MIA 1;
BA_ "Confidence" SG_ 864 VCLEFT_a090_APS_MIA 1;
BA_ "Confidence" SG_ 864 VCLEFT_a091_CMPD_MIA 1;
BA_ "Confidence" SG_ 864 VCLEFT_a092_VCSEATD_MIA 1;
BA_ "Confidence" SG_ 864 VCLEFT_a093_VCSEATP_MIA 1;
BA_ "Confidence" SG_ 864 VCLEFT_a094_EPAS3P_MIA 1;
BA_ "Confidence" SG_ 864 VCLEFT_a095_CHG_MIA 1;
BA_ "Confidence" SG_ 864 VCLEFT_a096_OCS1P_MIA 1;
BA_ "Confidence" SG_ 864 VCLEFT_a097_CMP_MIA 1;
BA_ "Confidence" SG_ 864 VCLEFT_a098_DIR_MIA 1;
BA_ "Confidence" SG_ 864 VCLEFT_a099_PARK_MIA 1;
BA_ "Confidence" SG_ 864 VCLEFT_a100_CANbus_MIA 1;
BA_ "Confidence" SG_ 864 VCLEFT_a101_PM_MIA 1;
BA_ "Confidence" SG_ 864 VCLEFT_a102_PTC_MIA 1;
BA_ "Confidence" SG_ 864 VCLEFT_a103_CP_MIA 1;
BA_ "Confidence" SG_ 864 VCLEFT_a104_DAS_MIA 1;
BA_ "Confidence" SG_ 864 VCLEFT_a105_TAS_MIA 1;
BA_ "Confidence" SG_ 864 VCLEFT_a106_PCS_MIA 1;
BA_ "Confidence" SG_ 864 VCLEFT_a107_BMS_MIA 1;
BA_ "Confidence" SG_ 864 VCLEFT_a108_DIF_MIA 1;
BA_ "Confidence" SG_ 864 VCLEFT_a109_RCM_MIA 1;
BA_ "Confidence" SG_ 864 VCLEFT_a110_GTW_MIA 1;
BA_ "Confidence" SG_ 864 VCLEFT_a111_EPBR_MIA 1;
BA_ "Confidence" SG_ 864 VCLEFT_a112_EPBL_MIA 1;
BA_ "Confidence" SG_ 864 VCLEFT_a113_UI_MIA 1;
BA_ "Confidence" SG_ 864 VCLEFT_a114_ESP_MIA 1;
BA_ "Confidence" SG_ 864 VCLEFT_a115_VCSEC_MIA 1;
BA_ "Confidence" SG_ 864 VCLEFT_a116_VCRIGHT_MIA 1;
BA_ "Confidence" SG_ 864 VCLEFT_a117_VCLEFT_MIA 1;
BA_ "Confidence" SG_ 864 VCLEFT_a118_VCFRONT_MIA 1;
BA_ "Confidence" SG_ 864 VCLEFT_a119_SCCM_MIA 1;
BA_ "Confidence" SG_ 864 VCLEFT_a120_DI_DRIVE_MIA 1;
BA_ "Confidence" SG_ 864 VCLEFT_a121_ETC_MIA 1;
BA_ "Confidence" SG_ 864 VCLEFT_a122_ICR_MIA 1;
BA_ "Confidence" SG_ 864 VCLEFT_a123_AID_MIA 1;
BA_ "Confidence" SG_ 864 VCLEFT_a124_BB_MIA 1;
BA_ "Confidence" SG_ 864 VCLEFT_a125_RCU_MIA 1;
BA_ "Confidence" SG_ 864 VCLEFT_a129_blowerICLatchFault 1;
BA_ "Confidence" SG_ 864 VCLEFT_a130_blowerICWarning 1;
BA_ "Confidence" SG_ 864 VCLEFT_a131_blowerICTransFault 1;
BA_ "Confidence" SG_ 864 VCLEFT_a132_blowerSoftStall 1;
BA_ "Confidence" SG_ 864 VCLEFT_a133_blowerLowRPMCBang 1;
BA_ "Confidence" SG_ 864 VCLEFT_a134_SteerColUpDownUnCal 1;
BA_ "Confidence" SG_ 864 VCLEFT_a135_SteerColInOutUnCal 1;
BA_ "Confidence" SG_ 864 VCLEFT_a136_brakeSwitchMismatch 1;
BA_ "Confidence" SG_ 864 VCLEFT_a137_VCSECPowerCycled 1;
BA_ "Confidence" SG_ 864 VCLEFT_a138_consoleDoorAssist 1;
BA_ "Confidence" SG_ 864 VCLEFT_a139_BLERearPowerCycled 1;
BA_ "Confidence" SG_ 864 VCLEFT_a140_BLELeftPowerCycled 1;
BA_ "Confidence" SG_ 864 VCLEFT_a141_12VAuxPowerTrip 1;
BA_ "Confidence" SG_ 864 VCLEFT_a143_mirrorManuallyFolded 1;
BA_ "Confidence" SG_ 864 VCLEFT_a145_brakeSwitchStuck 1;
BA_ "Confidence" SG_ 864 VCLEFT_a148_brakePressInputMisma 1;
BA_ "SystemSignalLongSymbol" SG_ 864 VCLEFT_a148_brakePressInputMisma "VCLEFT_a148_brakePressInputMismatch";
BA_ "Confidence" SG_ 864 VCLEFT_a150_windowPinchFront 1;
BA_ "Confidence" SG_ 864 VCLEFT_a151_windowPinchRear 1;
BA_ "Confidence" SG_ 864 VCLEFT_a152_windowUncalFront 1;
BA_ "Confidence" SG_ 864 VCLEFT_a153_windowUncalRear 1;
BA_ "Confidence" SG_ 864 VCLEFT_a154_windowThermalFront 1;
BA_ "Confidence" SG_ 864 VCLEFT_a155_windowThermalRear 1;
BA_ "Confidence" SG_ 864 VCLEFT_a156_windowNoInputFront 1;
BA_ "Confidence" SG_ 864 VCLEFT_a157_windowNoInputRear 1;
BA_ "Confidence" SG_ 864 VCLEFT_a158_windowPinchOverideF 1;
BA_ "Confidence" SG_ 864 VCLEFT_a159_windowPinchOverideR 1;
BA_ "Confidence" SG_ 864 VCLEFT_a160_windowUndercurrentF 1;
BA_ "Confidence" SG_ 864 VCLEFT_a161_windowUndercurrentR 1;
BA_ "Confidence" SG_ 864 VCLEFT_a162_windowEncoderStallF 1;
BA_ "Confidence" SG_ 864 VCLEFT_a163_windowEncoderStallR 1;
BA_ "Confidence" SG_ 864 VCLEFT_a164_windowFactoryTest 1;
BA_ "Confidence" SG_ 864 VCLEFT_a165_windowFactoryTest2 1;
BA_ "Confidence" SG_ 864 VCLEFT_a166_windowDebug 1;
BA_ "Confidence" SG_ 864 VCLEFT_a167_windowDebugPinchF 1;
BA_ "Confidence" SG_ 864 VCLEFT_a168_windowDebugPinchR 1;
BA_ "Confidence" SG_ 864 VCLEFT_a169_windowCurrentPeakF 1;
BA_ "Confidence" SG_ 864 VCLEFT_a170_windowCurrentPeakR 1;
BA_ "Confidence" SG_ 864 VCLEFT_a172_SPI_MIA 1;
BA_ "Confidence" SG_ 864 VCLEFT_a173_windowBtnDoorOpen 1;
BA_ "Confidence" SG_ 864 VCLEFT_a175_windowSealDefectFron 1;
BA_ "SystemSignalLongSymbol" SG_ 864 VCLEFT_a175_windowSealDefectFron "VCLEFT_a175_windowSealDefectFront";
BA_ "Confidence" SG_ 864 VCLEFT_a176_windowSealDefectRear 1;
BA_ "Confidence" SG_ 864 VCLEFT_a180_frontDoorLatchRehome 1;
BA_ "Confidence" SG_ 864 VCLEFT_a181_rearDoorLatchRehome 1;
BA_ "Confidence" SG_ 864 VCLEFT_a182_emergencyLatchRel 1;
BA_ "Confidence" SG_ 864 VCLEFT_a183_doorStateFactoryTest 1;
BA_ "Confidence" SG_ 864 VCLEFT_a185_summonAborted 1;
BA_ "Confidence" SG_ 864 VCLEFT_a186_latchReleaseFailedF 1;
BA_ "Confidence" SG_ 864 VCLEFT_a187_latchReleaseFailedR 1;
BA_ "Confidence" SG_ 864 VCLEFT_a188_latchUnableToRearmF 1;
BA_ "Confidence" SG_ 864 VCLEFT_a189_latchUnableToRearmR 1;
BA_ "Confidence" SG_ 864 VCLEFT_a190_eFuseMgmtVbatFused 1;
BA_ "Confidence" SG_ 864 VCLEFT_a191_TLCOvercurrent 1;
BA_ "Confidence" SG_ 864 VCLEFT_a192_blowerGeneralFault 1;
BA_ "Confidence" SG_ 864 VCLEFT_a193_blowerMIA 1;
BA_ "Confidence" SG_ 864 VCLEFT_a194_blowerUnidentified 1;
BA_ "Confidence" SG_ 864 VCLEFT_a195_blowerIdentification 1;
BA_ "SystemSignalLongSymbol" SG_ 864 VCLEFT_a195_blowerIdentification "VCLEFT_a195_blowerIdentificationFailed";
BA_ "Confidence" SG_ 864 VCLEFT_a196_VEHCANOverterminate 1;
BA_ "Confidence" SG_ 864 VCLEFT_a197_VEHCANUndertrminate 1;
BA_ "Confidence" SG_ 864 VCLEFT_a200_motorPhantomEncoder 1;
BA_ "Confidence" SG_ 864 VCLEFT_a201_motorDutyEncDisabl 1;
BA_ "Confidence" SG_ 864 VCLEFT_a202_epbmUnderIStatic 1;
BA_ "Confidence" SG_ 864 VCLEFT_a203_epbmOverIStatic 1;
BA_ "Confidence" SG_ 864 VCLEFT_a204_epbmUnderIDyn 1;
BA_ "Confidence" SG_ 864 VCLEFT_a205_epbmOverIDyn 1;
BA_ "Confidence" SG_ 864 VCLEFT_a206_epbWrongDirection 1;
BA_ "Confidence" SG_ 864 VCLEFT_a207_epbmEnableWrong 1;
BA_ "Confidence" SG_ 864 VCLEFT_a208_epbFaulted 1;
BA_ "Confidence" SG_ 864 VCLEFT_a209_epbStateMisTime 1;
BA_ "Confidence" SG_ 864 VCLEFT_a210_epbStateTime 1;
BA_ "Confidence" SG_ 864 VCLEFT_a211_epbmUnderIStaticNew 1;
BA_ "Confidence" SG_ 864 VCLEFT_a212_epbmOverIStaticNew 1;
BA_ "Confidence" SG_ 864 VCLEFT_a213_epbmUnderIDynNew 1;
BA_ "Confidence" SG_ 864 VCLEFT_a214_epbmOverIDynNew 1;
BA_ "Confidence" SG_ 864 VCLEFT_a215_currentDesyncWarning 1;
BA_ "Confidence" SG_ 864 VCLEFT_a216_SPI_MIA_debugData1 1;
BA_ "Confidence" SG_ 864 VCLEFT_a217_SPI_MIA_debugData2 1;
BA_ "Confidence" SG_ 864 VCLEFT_a218_motorDriverFault 1;
BA_ "Confidence" SG_ 864 VCLEFT_a219_motorCurrentDropout 1;
BA_ "Confidence" SG_ 864 VCLEFT_a224_seatEncStallTrack 1;
BA_ "Confidence" SG_ 864 VCLEFT_a225_seatEncStallBack 1;
BA_ "Confidence" SG_ 864 VCLEFT_a226_seatEncStallTilt 1;
BA_ "Confidence" SG_ 864 VCLEFT_a227_seatEncStallLift 1;
BA_ "Confidence" SG_ 864 VCLEFT_a228_seatEncOverTrack 1;
BA_ "Confidence" SG_ 864 VCLEFT_a229_seatEncOverBack 1;
BA_ "Confidence" SG_ 864 VCLEFT_a230_seatEncOverTilt 1;
BA_ "Confidence" SG_ 864 VCLEFT_a231_seatEncOverLift 1;
BA_ "Confidence" SG_ 864 VCLEFT_a232_seatCurrUnderTrack 1;
BA_ "Confidence" SG_ 864 VCLEFT_a233_seatCurrUnderBack 1;
BA_ "Confidence" SG_ 864 VCLEFT_a234_seatCurrUnderTilt 1;
BA_ "Confidence" SG_ 864 VCLEFT_a235_seatCurrUnderLift 1;
BA_ "Confidence" SG_ 864 VCLEFT_a236_lumbarOverPresA 1;
BA_ "Confidence" SG_ 864 VCLEFT_a237_lumbarOverPresB 1;
BA_ "Confidence" SG_ 864 VCLEFT_a238_lumbarValveMIA 1;
BA_ "Confidence" SG_ 864 VCLEFT_a239_seatHeatIFront 1;
BA_ "Confidence" SG_ 864 VCLEFT_a240_seatHeatShortFront 1;
BA_ "Confidence" SG_ 864 VCLEFT_a241_seatHeatMIAFront 1;
BA_ "Confidence" SG_ 864 VCLEFT_a242_seatHeatIRearL 1;
BA_ "Confidence" SG_ 864 VCLEFT_a243_seatHeatShortRearL 1;
BA_ "Confidence" SG_ 864 VCLEFT_a244_seatHeatMIARearL 1;
BA_ "Confidence" SG_ 864 VCLEFT_a245_seatHeatIRearC 1;
BA_ "Confidence" SG_ 864 VCLEFT_a246_seatHeatShortRearC 1;
BA_ "Confidence" SG_ 864 VCLEFT_a247_seatHeatMIARearC 1;
BA_ "Confidence" SG_ 864 VCLEFT_a248_seatHeatIRearR 1;
BA_ "Confidence" SG_ 864 VCLEFT_a249_seatHeatShortRearR 1;
BA_ "Confidence" SG_ 864 VCLEFT_a250_seatHeatMIARearR 1;
BA_ "Confidence" SG_ 864 VCLEFT_a251_seatUncalTrack 1;
BA_ "Confidence" SG_ 864 VCLEFT_a252_seatUncalBack 1;
BA_ "Confidence" SG_ 864 VCLEFT_a253_seatUncalTilt 1;
BA_ "Confidence" SG_ 864 VCLEFT_a254_seatUncalLift 1;
BA_ "Confidence" SG_ 864 VCLEFT_a257_USBMIA 1;
BA_ "Confidence" SG_ 864 VCLEFT_a259_latchDisarmDelayF 1;
BA_ "Confidence" SG_ 864 VCLEFT_a260_latchDisarmDelayR 1;
BA_ "Confidence" SG_ 864 VCLEFT_a261_emergencyLatchRelRea 1;
BA_ "SystemSignalLongSymbol" SG_ 864 VCLEFT_a261_emergencyLatchRelRea "VCLEFT_a261_emergencyLatchRelRear";
BA_ "Confidence" SG_ 864 VCLEFT_a263_seatTrackStallDebug 1;
BA_ "Confidence" SG_ 864 VCLEFT_a264_seatBackStallDebug 1;
BA_ "Confidence" SG_ 864 VCLEFT_a265_seatTiltStallDebug 1;
BA_ "Confidence" SG_ 864 VCLEFT_a266_seatLiftStallDebug 1;
BA_ "Confidence" SG_ 864 VCLEFT_a267_seatTrackHCEncStlDbg 1;
BA_ "Confidence" SG_ 864 VCLEFT_a268_seatBackHCEncStlDbg 1;
BA_ "Confidence" SG_ 864 VCLEFT_a269_seatTiltHCEncStlDbg 1;
BA_ "Confidence" SG_ 864 VCLEFT_a270_seatLiftHCEncStlDbg 1;
BA_ "Confidence" SG_ 864 VCLEFT_a272_vhclPwrStateMsmtch 1;
BA_ "Confidence" SG_ 864 VCLEFT_a273_handleStuckActiveF 1;
BA_ "Confidence" SG_ 864 VCLEFT_a274_handleStuckActiveR 1;
BA_ "Confidence" SG_ 864 VCLEFT_a275_leftTurnLightFault 1;
BA_ "Confidence" SG_ 864 VCLEFT_a276_mirrorDebug 1;
BA_ "Confidence" SG_ 864 VCLEFT_a277_BLELeftUnderVoltage 1;
BA_ "Confidence" SG_ 864 VCLEFT_a278_BLERearUnderVoltage 1;
BA_ "Confidence" SG_ 864 VCLEFT_a279_VCSECUnderVoltage 1;
BA_ "Confidence" SG_ 864 VCLEFT_a280_latchDidNotDisarmF 1;
BA_ "Confidence" SG_ 864 VCLEFT_a281_latchDidNotDisarmR 1;
BA_ "Confidence" SG_ 864 VCLEFT_a282_latchUnexpectedArmF 1;
BA_ "Confidence" SG_ 864 VCLEFT_a283_latchUnexpectedArmR 1;
BA_ "Confidence" SG_ 864 VCLEFT_a284_blowerFbkSanity 1;
BA_ "Confidence" SG_ 864 VCLEFT_a285_blowerChipComms 1;
BA_ "Confidence" SG_ 864 VCLEFT_a286_windowSpeedInvalidF 1;
BA_ "Confidence" SG_ 864 VCLEFT_a287_windowSpeedInvalidR 1;
BA_ "Confidence" SG_ 864 VCLEFT_a288_handlePWMPeriodF 1;
BA_ "Confidence" SG_ 864 VCLEFT_a289_handlePWMPeriodR 1;
BA_ "Confidence" SG_ 864 VCLEFT_a290_occupancyFaultedFron 1;
BA_ "SystemSignalLongSymbol" SG_ 864 VCLEFT_a290_occupancyFaultedFron "VCLEFT_a290_occupancyFaultedFront";
BA_ "Confidence" SG_ 864 VCLEFT_a291_buckleFaultedFront 1;
BA_ "Confidence" SG_ 864 VCLEFT_a292_occupancyFaultedRear 1;
BA_ "SystemSignalLongSymbol" SG_ 864 VCLEFT_a292_occupancyFaultedRear "VCLEFT_a292_occupancyFaultedRearL";
BA_ "Confidence" SG_ 864 VCLEFT_a293_occupancyFaultedRear 1;
BA_ "SystemSignalLongSymbol" SG_ 864 VCLEFT_a293_occupancyFaultedRear "VCLEFT_a293_occupancyFaultedRearC";
BA_ "Confidence" SG_ 864 VCLEFT_a294_occupancyFaultedRear 1;
BA_ "SystemSignalLongSymbol" SG_ 864 VCLEFT_a294_occupancyFaultedRear "VCLEFT_a294_occupancyFaultedRearR";
BA_ "Confidence" SG_ 864 VCLEFT_a295_buckleFaultedRearL 1;
BA_ "Confidence" SG_ 864 VCLEFT_a296_buckleFaultedRearC 1;
BA_ "Confidence" SG_ 864 VCLEFT_a297_seatBelowMinPumpTmp 1;
BA_ "Confidence" SG_ 864 VCLEFT_a299_swcMIA 1;
BA_ "Confidence" SG_ 864 VCLEFT_a300_swcUnderVoltage 1;
BA_ "Confidence" SG_ 864 VCLEFT_a301_swcOverVoltage 1;
BA_ "Confidence" SG_ 864 VCLEFT_a302_blowerGeneralFault 1;
BA_ "Confidence" SG_ 864 VCLEFT_a303_eFuseMgmtWindowLift 1;
BA_ "Confidence" SG_ 864 VCLEFT_a304_frontIntHandleShorte 1;
BA_ "SystemSignalLongSymbol" SG_ 864 VCLEFT_a304_frontIntHandleShorte "VCLEFT_a304_frontIntHandleShorted";
BA_ "Confidence" SG_ 864 VCLEFT_a305_rearIntHandleShorted 1;
BA_ "Confidence" SG_ 864 VCLEFT_a306_handleDisconnectedF 1;
BA_ "Confidence" SG_ 864 VCLEFT_a307_handleDisconnectedR 1;
BA_ "Confidence" SG_ 864 VCLEFT_a308_sirenMIA 1;
BA_ "Confidence" SG_ 864 VCLEFT_a309_brakeSwitchFaulted 1;
BA_ "Confidence" SG_ 864 VCLEFT_a310_mirrorFoldStall 1;
BA_ "Confidence" SG_ 864 VCLEFT_a311_leftBrakeLightFault 1;
BA_ "Confidence" SG_ 864 VCLEFT_a312_leftTailLightFault 1;
BA_ "Confidence" SG_ 864 VCLEFT_a313_leftFootwellLightFau 1;
BA_ "SystemSignalLongSymbol" SG_ 864 VCLEFT_a313_leftFootwellLightFau "VCLEFT_a313_leftFootwellLightFault";
BA_ "Confidence" SG_ 864 VCLEFT_a314_leftMapPocketLightFa 1;
BA_ "SystemSignalLongSymbol" SG_ 864 VCLEFT_a314_leftMapPocketLightFa "VCLEFT_a314_leftMapPocketLightFault";
BA_ "Confidence" SG_ 864 VCLEFT_a315_leftInteriorTrunkLig 1;
BA_ "SystemSignalLongSymbol" SG_ 864 VCLEFT_a315_leftInteriorTrunkLig "VCLEFT_a315_leftInteriorTrunkLightFault";
BA_ "Confidence" SG_ 864 VCLEFT_a316_mirrorPrematureFoldS 1;
BA_ "SystemSignalLongSymbol" SG_ 864 VCLEFT_a316_mirrorPrematureFoldS "VCLEFT_a316_mirrorPrematureFoldStall";
BA_ "Confidence" SG_ 864 VCLEFT_a317_epbmLimpModeEnabled 1;
BA_ "Confidence" SG_ 864 VCLEFT_a318_trailerIncorrectConf 1;
BA_ "SystemSignalLongSymbol" SG_ 864 VCLEFT_a318_trailerIncorrectConf "VCLEFT_a318_trailerIncorrectConfig";
BA_ "Confidence" SG_ 864 VCLEFT_a319_brakePressPrimaryInp 1;
BA_ "SystemSignalLongSymbol" SG_ 864 VCLEFT_a319_brakePressPrimaryInp "VCLEFT_a319_brakePressPrimaryInputFaulted";
BA_ "Confidence" SG_ 864 VCLEFT_a320_windowReportCrackedA 1;
BA_ "SystemSignalLongSymbol" SG_ 864 VCLEFT_a320_windowReportCrackedA "VCLEFT_a320_windowReportCrackedAtTrimClear";
BA_ "Confidence" SG_ 864 VCLEFT_a321_windowRezeroedDebugF 1;
BA_ "Confidence" SG_ 864 VCLEFT_a322_windowRezeroedDebugR 1;
BA_ "Confidence" SG_ 864 VCLEFT_a323_mirrorCalibrated 1;
BA_ "Confidence" SG_ 864 VCLEFT_a324_mirrorHeatFault 1;
BA_ "Confidence" SG_ 864 VCLEFT_a325_hghtSnsrUnplgdFL 1;
BA_ "Confidence" SG_ 864 VCLEFT_a326_hghtSnsrUnplgdRL 1;
BA_ "Confidence" SG_ 864 VCLEFT_a327_hghtSnsrFaultFL 1;
BA_ "Confidence" SG_ 864 VCLEFT_a328_hghtSnsrFaultRL 1;
BA_ "Confidence" SG_ 864 VCLEFT_a329_noRideHeightCalib 1;
BA_ "Confidence" SG_ 864 VCLEFT_a330_shortDropFailedF 1;
BA_ "Confidence" SG_ 864 VCLEFT_a331_shortDropFailedR 1;
BA_ "Confidence" SG_ 864 VCLEFT_a332_intrusionSensorMIA 1;
BA_ "Confidence" SG_ 864 VCLEFT_a333_overheadConsoleMIA 1;
BA_ "Confidence" SG_ 864 VCLEFT_a334_overheadConsoleInter 1;
BA_ "SystemSignalLongSymbol" SG_ 864 VCLEFT_a334_overheadConsoleInter "VCLEFT_a334_overheadConsoleInternalFault";
BA_ "Confidence" SG_ 864 VCLEFT_a335_intrusionSensorInter 1;
BA_ "SystemSignalLongSymbol" SG_ 864 VCLEFT_a335_intrusionSensorInter "VCLEFT_a335_intrusionSensorInternalFault";
BA_ "Confidence" SG_ 864 VCLEFT_a336_windowDropRevThermal 1;
BA_ "SystemSignalLongSymbol" SG_ 864 VCLEFT_a336_windowDropRevThermal "VCLEFT_a336_windowDropRevThermalF";
BA_ "Confidence" SG_ 864 VCLEFT_a337_windowDropRevThermal 1;
BA_ "SystemSignalLongSymbol" SG_ 864 VCLEFT_a337_windowDropRevThermal "VCLEFT_a337_windowDropRevThermalR";
BA_ "Confidence" SG_ 864 VCLEFT_a338_trailerLightControll 1;
BA_ "SystemSignalLongSymbol" SG_ 864 VCLEFT_a338_trailerLightControll "VCLEFT_a338_trailerLightControllerMIA";
BA_ "Confidence" SG_ 864 VCLEFT_a339_trailerLeftTurnLight 1;
BA_ "SystemSignalLongSymbol" SG_ 864 VCLEFT_a339_trailerLeftTurnLight "VCLEFT_a339_trailerLeftTurnLightNotDetected";
BA_ "Confidence" SG_ 864 VCLEFT_a340_trailerRightTurnLigh 1;
BA_ "SystemSignalLongSymbol" SG_ 864 VCLEFT_a340_trailerRightTurnLigh "VCLEFT_a340_trailerRightTurnLightNotDetected";
BA_ "Confidence" SG_ 864 VCLEFT_a341_trailerLightFault 1;
BA_ "Confidence" SG_ 864 VCLEFT_a342_trailerLightControll 1;
BA_ "SystemSignalLongSymbol" SG_ 864 VCLEFT_a342_trailerLightControll "VCLEFT_a342_trailerLightControllerFault";
BA_ "Confidence" SG_ 864 VCLEFT_a345_chargePortPowerCycli 1;
BA_ "SystemSignalLongSymbol" SG_ 864 VCLEFT_a345_chargePortPowerCycli "VCLEFT_a345_chargePortPowerCycling";
BA_ "Confidence" SG_ 864 VCLEFT_a346_eFuseMgmtVbatFused2 1;
BA_ "Confidence" SG_ 864 VCLEFT_a347_nonContMonitorCleare 1;
BA_ "SystemSignalLongSymbol" SG_ 864 VCLEFT_a347_nonContMonitorCleare "VCLEFT_a347_nonContMonitorClearedDBG";
BA_ "Confidence" SG_ 864 VCLEFT_a348_CPSleepOvercurrent 1;
BA_ "Confidence" SG_ 864 VCLEFT_a349_CPSleepUndervoltage 1;
BA_ "Confidence" SG_ 864 VCLEFT_a350_ensOutOfRange 1;
BA_ "Confidence" SG_ 864 VCLEFT_a351_debugLiftgateCurrent 1;
BA_ "SystemSignalLongSymbol" SG_ 864 VCLEFT_a351_debugLiftgateCurrent "VCLEFT_a351_debugLiftgateCurrentSpike";
BA_ "Confidence" SG_ 864 VCLEFT_a352_liftgateClosingLatch 1;
BA_ "SystemSignalLongSymbol" SG_ 864 VCLEFT_a352_liftgateClosingLatch "VCLEFT_a352_liftgateClosingLatchEntryFailed";
BA_ "Confidence" SG_ 864 VCLEFT_a353_eFuseMgmtSteeringCol 1;
BA_ "SystemSignalLongSymbol" SG_ 864 VCLEFT_a353_eFuseMgmtSteeringCol "VCLEFT_a353_eFuseMgmtSteeringColumn";
BA_ "Confidence" SG_ 864 VCLEFT_a354_eFuseMgmtLiftGate 1;
BA_ "Confidence" SG_ 864 VCLEFT_a355_liftgateUnexpectedSt 1;
BA_ "SystemSignalLongSymbol" SG_ 864 VCLEFT_a355_liftgateUnexpectedSt "VCLEFT_a355_liftgateUnexpectedStop";
BA_ "Confidence" SG_ 864 VCLEFT_a356_liftgateFactoryTest 1;
BA_ "Confidence" SG_ 864 VCLEFT_a357_liftgateUncalibrated 1;
BA_ "Confidence" SG_ 864 VCLEFT_a358_debugLiftgateCurrent 1;
BA_ "SystemSignalLongSymbol" SG_ 864 VCLEFT_a358_debugLiftgateCurrent "VCLEFT_a358_debugLiftgateCurrentDropout";
BA_ "Confidence" SG_ 864 VCLEFT_a359_liftgateLatchExitNoP 1;
BA_ "SystemSignalLongSymbol" SG_ 864 VCLEFT_a359_liftgateLatchExitNoP "VCLEFT_a359_liftgateLatchExitNoPositionChange";
BA_ "Confidence" SG_ 864 VCLEFT_a360_detectedStationaryWh 1;
BA_ "SystemSignalLongSymbol" SG_ 864 VCLEFT_a360_detectedStationaryWh "VCLEFT_a360_detectedStationaryWhileMoving";
BA_ "Confidence" SG_ 864 VCLEFT_a361_stationaryThresholds 1;
BA_ "SystemSignalLongSymbol" SG_ 864 VCLEFT_a361_stationaryThresholds "VCLEFT_a361_stationaryThresholdsIncorrect";
BA_ "Confidence" SG_ 864 VCLEFT_a362_movingThresholdsInco 1;
BA_ "SystemSignalLongSymbol" SG_ 864 VCLEFT_a362_movingThresholdsInco "VCLEFT_a362_movingThresholdsIncorrect";
BA_ "Confidence" SG_ 864 VCLEFT_a363_liftgateOpenAngleSet 1;
BA_ "SystemSignalLongSymbol" SG_ 864 VCLEFT_a363_liftgateOpenAngleSet "VCLEFT_a363_liftgateOpenAngleSetReq";
BA_ "Confidence" SG_ 864 VCLEFT_a365_pitchUnlatchDisabled 1;
BA_ "Confidence" SG_ 864 VCLEFT_a366_liftgateLatchEntryDB 1;
BA_ "SystemSignalLongSymbol" SG_ 864 VCLEFT_a366_liftgateLatchEntryDB "VCLEFT_a366_liftgateLatchEntryDBG";
BA_ "Confidence" SG_ 864 VCLEFT_a370_seat2RowPitchUnlatch 1;
BA_ "SystemSignalLongSymbol" SG_ 864 VCLEFT_a370_seat2RowPitchUnlatch "VCLEFT_a370_seat2RowPitchUnlatched";
BA_ "Confidence" SG_ 864 VCLEFT_a371_seat2RowTrackUnlatch 1;
BA_ "SystemSignalLongSymbol" SG_ 864 VCLEFT_a371_seat2RowTrackUnlatch "VCLEFT_a371_seat2RowTrackUnlatched";
BA_ "Confidence" SG_ 864 VCLEFT_a372_seat2RowBackrestUnla 1;
BA_ "SystemSignalLongSymbol" SG_ 864 VCLEFT_a372_seat2RowBackrestUnla "VCLEFT_a372_seat2RowBackrestUnlatched";
BA_ "Confidence" SG_ 864 VCLEFT_a373_windowSwOpenReqInDog 1;
BA_ "SystemSignalLongSymbol" SG_ 864 VCLEFT_a373_windowSwOpenReqInDog "VCLEFT_a373_windowSwOpenReqInDogMode";
BA_ "Confidence" SG_ 864 VCLEFT_a374_trailerLightFaultMod 1;
BA_ "SystemSignalLongSymbol" SG_ 864 VCLEFT_a374_trailerLightFaultMod "VCLEFT_a374_trailerLightFaultModelY";
BA_ "Confidence" SG_ 864 VCLEFT_a375_windowPinchOverrideN 1;
BA_ "SystemSignalLongSymbol" SG_ 864 VCLEFT_a375_windowPinchOverrideN "VCLEFT_a375_windowPinchOverrideNudge";
BA_ "Confidence" SG_ 864 VCLEFT_a376_seat2RowBridgeCurren 1;
BA_ "SystemSignalLongSymbol" SG_ 864 VCLEFT_a376_seat2RowBridgeCurren "VCLEFT_a376_seat2RowBridgeCurrentExceeded";
BA_ "Confidence" SG_ 864 VCLEFT_a380_steerColThermalLimit 1;
BA_ "SystemSignalLongSymbol" SG_ 864 VCLEFT_a380_steerColThermalLimit "VCLEFT_a380_steerColThermalLimited";
BA_ "Confidence" SG_ 864 VCLEFT_a381_pitchEstimation1 1;
BA_ "Confidence" SG_ 864 VCLEFT_a382_pitchEstimation2 1;
BA_ "Confidence" SG_ 864 VCLEFT_a383_steerColInOutMotorSt 1;
BA_ "SystemSignalLongSymbol" SG_ 864 VCLEFT_a383_steerColInOutMotorSt "VCLEFT_a383_steerColInOutMotorStallCurrent";
BA_ "Confidence" SG_ 864 VCLEFT_a384_steerColUpDownMotorS 1;
BA_ "SystemSignalLongSymbol" SG_ 864 VCLEFT_a384_steerColUpDownMotorS "VCLEFT_a384_steerColUpDownMotorStallCurrent";
BA_ "Confidence" SG_ 864 VCLEFT_a385_steerColInOutMotorUn 1;
BA_ "SystemSignalLongSymbol" SG_ 864 VCLEFT_a385_steerColInOutMotorUn "VCLEFT_a385_steerColInOutMotorUnderCurrent";
BA_ "Confidence" SG_ 864 VCLEFT_a386_steerColUpDownMotorU 1;
BA_ "SystemSignalLongSymbol" SG_ 864 VCLEFT_a386_steerColUpDownMotorU "VCLEFT_a386_steerColUpDownMotorUnderCurrent";
BA_ "Confidence" SG_ 864 VCLEFT_a387_steerColInOutMotorEn 1;
BA_ "SystemSignalLongSymbol" SG_ 864 VCLEFT_a387_steerColInOutMotorEn "VCLEFT_a387_steerColInOutMotorEncoderStalled";
BA_ "Confidence" SG_ 864 VCLEFT_a388_steerColUpDownMotorE 1;
BA_ "SystemSignalLongSymbol" SG_ 864 VCLEFT_a388_steerColUpDownMotorE "VCLEFT_a388_steerColUpDownMotorEncoderStalled";
BA_ "Confidence" SG_ 864 VCLEFT_a389_steerColInOutEncoder 1;
BA_ "SystemSignalLongSymbol" SG_ 864 VCLEFT_a389_steerColInOutEncoder "VCLEFT_a389_steerColInOutEncoderOutOfRange";
BA_ "Confidence" SG_ 864 VCLEFT_a390_steerColUpDownEncode 1;
BA_ "SystemSignalLongSymbol" SG_ 864 VCLEFT_a390_steerColUpDownEncode "VCLEFT_a390_steerColUpDownEncoderOutOfRange";
BA_ "Confidence" SG_ 864 VCLEFT_a391_pitchEstimationImpla 1;
BA_ "SystemSignalLongSymbol" SG_ 864 VCLEFT_a391_pitchEstimationImpla "VCLEFT_a391_pitchEstimationImplausible";
BA_ "Confidence" SG_ 864 VCLEFT_a392_pitchEstimationGPSIm 1;
BA_ "SystemSignalLongSymbol" SG_ 864 VCLEFT_a392_pitchEstimationGPSIm "VCLEFT_a392_pitchEstimationGPSImprovedReinit";
BA_ "Confidence" SG_ 864 VCLEFT_a393_pitchEstimationNoGPS 1;
BA_ "SystemSignalLongSymbol" SG_ 864 VCLEFT_a393_pitchEstimationNoGPS "VCLEFT_a393_pitchEstimationNoGPSFusion";
BA_ "Confidence" SG_ 864 VCLEFT_a394_swsTouchTooNegativeD 1;
BA_ "SystemSignalLongSymbol" SG_ 864 VCLEFT_a394_swsTouchTooNegativeD "VCLEFT_a394_swsTouchTooNegativeDelta";
BA_ "Confidence" SG_ 864 VCLEFT_a395_swsTouchAdcCheckFail 1;
BA_ "Confidence" SG_ 864 VCLEFT_a396_swsTouchStuckFault 1;
BA_ "Confidence" SG_ 864 VCLEFT_a397_swsTouchOutOfRangeFa 1;
BA_ "SystemSignalLongSymbol" SG_ 864 VCLEFT_a397_swsTouchOutOfRangeFa "VCLEFT_a397_swsTouchOutOfRangeFault";
BA_ "Confidence" SG_ 864 VCLEFT_a398_swsTouchNvmFault 1;
BA_ "Confidence" SG_ 864 VCLEFT_a399_swsTouchNoisyBaselin 1;
BA_ "SystemSignalLongSymbol" SG_ 864 VCLEFT_a399_swsTouchNoisyBaselin "VCLEFT_a399_swsTouchNoisyBaselineInitialization";
BA_ "Confidence" SG_ 864 VCLEFT_a400_swsTouchDebouncedPro 1;
BA_ "SystemSignalLongSymbol" SG_ 864 VCLEFT_a400_swsTouchDebouncedPro "VCLEFT_a400_swsTouchDebouncedProcessingError";
BA_ "Confidence" SG_ 864 VCLEFT_a401_swsForceTestPatternV 1;
BA_ "SystemSignalLongSymbol" SG_ 864 VCLEFT_a401_swsForceTestPatternV "VCLEFT_a401_swsForceTestPatternViolation";
BA_ "Confidence" SG_ 864 VCLEFT_a402_swsForceOutOfRange 1;
BA_ "Confidence" SG_ 864 VCLEFT_a403_swsForceAdcCheckFail 1;
BA_ "Confidence" SG_ 864 VCLEFT_a404_swsForceI2cError 1;
BA_ "Confidence" SG_ 864 VCLEFT_a405_swsForceCalibrationF 1;
BA_ "SystemSignalLongSymbol" SG_ 864 VCLEFT_a405_swsForceCalibrationF "VCLEFT_a405_swsForceCalibrationFault";
BA_ "Confidence" SG_ 864 VCLEFT_a406_swsForceParametersFa 1;
BA_ "SystemSignalLongSymbol" SG_ 864 VCLEFT_a406_swsForceParametersFa "VCLEFT_a406_swsForceParametersFault";
BA_ "Confidence" SG_ 864 VCLEFT_a407_swsForceNvmFault 1;
BA_ "Confidence" SG_ 864 VCLEFT_a408_swsForceTouchSensorF 1;
BA_ "SystemSignalLongSymbol" SG_ 864 VCLEFT_a408_swsForceTouchSensorF "VCLEFT_a408_swsForceTouchSensorFault";
BA_ "Confidence" SG_ 864 VCLEFT_a409_swsScrollWheelPushFa 1;
BA_ "SystemSignalLongSymbol" SG_ 864 VCLEFT_a409_swsScrollWheelPushFa "VCLEFT_a409_swsScrollWheelPushFault";
BA_ "Confidence" SG_ 864 VCLEFT_a410_swsScrollWheelTiltFa 1;
BA_ "SystemSignalLongSymbol" SG_ 864 VCLEFT_a410_swsScrollWheelTiltFa "VCLEFT_a410_swsScrollWheelTiltFault";
BA_ "Confidence" SG_ 864 VCLEFT_a411_swsScrollWheelScroll 1;
BA_ "SystemSignalLongSymbol" SG_ 864 VCLEFT_a411_swsScrollWheelScroll "VCLEFT_a411_swsScrollWheelScrollFault";
BA_ "Confidence" SG_ 864 VCLEFT_a412_leftBrakeTailLightFa 1;
BA_ "SystemSignalLongSymbol" SG_ 864 VCLEFT_a412_leftBrakeTailLightFa "VCLEFT_a412_leftBrakeTailLightFault";
BA_ "Confidence" SG_ 864 VCLEFT_a414_swsHapticMotorFault 1;
BA_ "Confidence" SG_ 864 VCLEFT_a415_swsMiscFault 1;
BA_ "Confidence" SG_ 864 VCLEFT_a416_fohmTouchAdcCheckFai 1;
BA_ "SystemSignalLongSymbol" SG_ 864 VCLEFT_a416_fohmTouchAdcCheckFai "VCLEFT_a416_fohmTouchAdcCheckFail";
BA_ "Confidence" SG_ 864 VCLEFT_a417_fohmTouchOutOfRangeF 1;
BA_ "SystemSignalLongSymbol" SG_ 864 VCLEFT_a417_fohmTouchOutOfRangeF "VCLEFT_a417_fohmTouchOutOfRangeFault";
BA_ "Confidence" SG_ 864 VCLEFT_a418_fohmTouchVarianceFai 1;
BA_ "SystemSignalLongSymbol" SG_ 864 VCLEFT_a418_fohmTouchVarianceFai "VCLEFT_a418_fohmTouchVarianceFail";
BA_ "Confidence" SG_ 864 VCLEFT_a419_fohmTouchStuck 1;
BA_ "Confidence" SG_ 864 VCLEFT_a420_fohmTouchSensorsImpl 1;
BA_ "SystemSignalLongSymbol" SG_ 864 VCLEFT_a420_fohmTouchSensorsImpl "VCLEFT_a420_fohmTouchSensorsImplausible";
BA_ "Confidence" SG_ 864 VCLEFT_a421_fohmForceOutOfRangeF 1;
BA_ "SystemSignalLongSymbol" SG_ 864 VCLEFT_a421_fohmForceOutOfRangeF "VCLEFT_a421_fohmForceOutOfRangeFault";
BA_ "Confidence" SG_ 864 VCLEFT_a423_fohmForceI2cError 1;
BA_ "Confidence" SG_ 864 VCLEFT_a424_fohmAmberLEDFault 1;
BA_ "Confidence" SG_ 864 VCLEFT_a425_fohmVanityPowerSuppl 1;
BA_ "SystemSignalLongSymbol" SG_ 864 VCLEFT_a425_fohmVanityPowerSuppl "VCLEFT_a425_fohmVanityPowerSupplyFault";
BA_ "Confidence" SG_ 864 VCLEFT_a426_seatAbuseMotorWarn 1;
BA_ "Confidence" SG_ 864 VCLEFT_a427_seatAbuseMotorStop 1;
BA_ "Confidence" SG_ 864 VCLEFT_a428_seatAbuseBufferWarn 1;
BA_ "Confidence" SG_ 864 VCLEFT_a429_seatAbuseBufferFull 1;
BA_ "Confidence" SG_ 864 VCLEFT_a430_fohmRearDomeLightPow 1;
BA_ "SystemSignalLongSymbol" SG_ 864 VCLEFT_a430_fohmRearDomeLightPow "VCLEFT_a430_fohmRearDomeLightPowerSupplyFault";
BA_ "Confidence" SG_ 864 VCLEFT_a431_fohmVbatFault 1;
BA_ "Confidence" SG_ 864 VCLEFT_a432_fohmMiscFault 1;
BA_ "Confidence" SG_ 864 VCLEFT_a433_fohmForceCalibration 1;
BA_ "SystemSignalLongSymbol" SG_ 864 VCLEFT_a433_fohmForceCalibration "VCLEFT_a433_fohmForceCalibrationInvalid";
BA_ "Confidence" SG_ 864 VCLEFT_a434_swsScrollWheelPushDa 1;
BA_ "SystemSignalLongSymbol" SG_ 864 VCLEFT_a434_swsScrollWheelPushDa "VCLEFT_a434_swsScrollWheelPushData";
BA_ "Confidence" SG_ 864 VCLEFT_a435_swsNoReasonTouchFaul 1;
BA_ "SystemSignalLongSymbol" SG_ 864 VCLEFT_a435_swsNoReasonTouchFaul "VCLEFT_a435_swsNoReasonTouchFault";
BA_ "Confidence" SG_ 864 VCLEFT_a436_swsNoReasonForceFaul 1;
BA_ "SystemSignalLongSymbol" SG_ 864 VCLEFT_a436_swsNoReasonForceFaul "VCLEFT_a436_swsNoReasonForceFault";
BA_ "Confidence" SG_ 864 VCLEFT_a437_hvacRearLeftVertical 1;
BA_ "SystemSignalLongSymbol" SG_ 864 VCLEFT_a437_hvacRearLeftVertical "VCLEFT_a437_hvacRearLeftVerticalDriverFaulted";
BA_ "Confidence" SG_ 864 VCLEFT_a438_hvacRearLeftLateralD 1;
BA_ "SystemSignalLongSymbol" SG_ 864 VCLEFT_a438_hvacRearLeftLateralD "VCLEFT_a438_hvacRearLeftLateralDriverFaulted";
BA_ "Confidence" SG_ 864 VCLEFT_a439_hvacRearRightVertica 1;
BA_ "SystemSignalLongSymbol" SG_ 864 VCLEFT_a439_hvacRearRightVertica "VCLEFT_a439_hvacRearRightVerticalDriverFaulted";
BA_ "Confidence" SG_ 864 VCLEFT_a440_hvacRearRightLateral 1;
BA_ "SystemSignalLongSymbol" SG_ 864 VCLEFT_a440_hvacRearRightLateral "VCLEFT_a440_hvacRearRightLateralDriverFaulted";
BA_ "Confidence" SG_ 864 VCLEFT_a441_prndMIA 1;
BA_ "Confidence" SG_ 864 VCLEFT_a442_swsLongTouchEvent 1;
BA_ "Confidence" SG_ 864 VCLEFT_a444_drv8703Fault 1;
BA_ "Confidence" SG_ 864 VCLEFT_a445_drv8703SpiFaultDBG 1;
BA_ "Confidence" SG_ 864 VCLEFT_a446_trailerAuxReversePow 1;
BA_ "SystemSignalLongSymbol" SG_ 864 VCLEFT_a446_trailerAuxReversePow "VCLEFT_a446_trailerAuxReversePower";
BA_ "Confidence" SG_ 864 VCLEFT_a447_steeringColInOutEnds 1;
BA_ "SystemSignalLongSymbol" SG_ 864 VCLEFT_a447_steeringColInOutEnds "VCLEFT_a447_steeringColInOutEndstopCal";
BA_ "Confidence" SG_ 864 VCLEFT_a448_steeringColUpDownEnd 1;
BA_ "SystemSignalLongSymbol" SG_ 864 VCLEFT_a448_steeringColUpDownEnd "VCLEFT_a448_steeringColUpDownEndstopCal";
BA_ "Confidence" SG_ 864 VCLEFT_a451_wirelessChargerMIA 1;
BA_ "Confidence" SG_ 864 VCLEFT_a453_liftgatePinchDetecte 1;
BA_ "SystemSignalLongSymbol" SG_ 864 VCLEFT_a453_liftgatePinchDetecte "VCLEFT_a453_liftgatePinchDetected";
BA_ "Confidence" SG_ 864 VCLEFT_a454_wirelessChargerFault 1;
BA_ "Confidence" SG_ 864 VCLEFT_a455_liftgateUnexpectedSh 1;
BA_ "SystemSignalLongSymbol" SG_ 864 VCLEFT_a455_liftgateUnexpectedSh "VCLEFT_a455_liftgateUnexpectedShutfaceSwPressed";
BA_ "Confidence" SG_ 864 VCLEFT_a460_etcDebug 1;
BA_ "Confidence" SG_ 864 VCLEFT_a466_hvac2RLeftAirwaveVer 1;
BA_ "SystemSignalLongSymbol" SG_ 864 VCLEFT_a466_hvac2RLeftAirwaveVer "VCLEFT_a466_hvac2RLeftAirwaveVerticalFault";
BA_ "Confidence" SG_ 864 VCLEFT_a467_hvac2RLeftAirwaveVer 1;
BA_ "SystemSignalLongSymbol" SG_ 864 VCLEFT_a467_hvac2RLeftAirwaveVer "VCLEFT_a467_hvac2RLeftAirwaveVerticalWarning";
BA_ "Confidence" SG_ 864 VCLEFT_a468_hvac2RLeftAirwaveVer 1;
BA_ "SystemSignalLongSymbol" SG_ 864 VCLEFT_a468_hvac2RLeftAirwaveVer "VCLEFT_a468_hvac2RLeftAirwaveVerticalUncalib";
BA_ "Confidence" SG_ 864 VCLEFT_a469_hvac2RLeftAirwaveLat 1;
BA_ "SystemSignalLongSymbol" SG_ 864 VCLEFT_a469_hvac2RLeftAirwaveLat "VCLEFT_a469_hvac2RLeftAirwaveLateralFault";
BA_ "Confidence" SG_ 864 VCLEFT_a470_hvac2RLeftAirwaveLat 1;
BA_ "SystemSignalLongSymbol" SG_ 864 VCLEFT_a470_hvac2RLeftAirwaveLat "VCLEFT_a470_hvac2RLeftAirwaveLateralWarning";
BA_ "Confidence" SG_ 864 VCLEFT_a471_hvac2RLeftAirwaveLat 1;
BA_ "SystemSignalLongSymbol" SG_ 864 VCLEFT_a471_hvac2RLeftAirwaveLat "VCLEFT_a471_hvac2RLeftAirwaveLateralUncalib";
BA_ "Confidence" SG_ 864 VCLEFT_a472_hvac2RRightAirwaveVe 1;
BA_ "SystemSignalLongSymbol" SG_ 864 VCLEFT_a472_hvac2RRightAirwaveVe "VCLEFT_a472_hvac2RRightAirwaveVerticalFault";
BA_ "Confidence" SG_ 864 VCLEFT_a473_hvac2RRightAirwaveVe 1;
BA_ "SystemSignalLongSymbol" SG_ 864 VCLEFT_a473_hvac2RRightAirwaveVe "VCLEFT_a473_hvac2RRightAirwaveVerticalWarning";
BA_ "Confidence" SG_ 864 VCLEFT_a474_hvac2RRightAirwaveVe 1;
BA_ "SystemSignalLongSymbol" SG_ 864 VCLEFT_a474_hvac2RRightAirwaveVe "VCLEFT_a474_hvac2RRightAirwaveVerticalUncalib";
BA_ "Confidence" SG_ 864 VCLEFT_a475_hvac2RRightAirwaveLa 1;
BA_ "SystemSignalLongSymbol" SG_ 864 VCLEFT_a475_hvac2RRightAirwaveLa "VCLEFT_a475_hvac2RRightAirwaveLateralFault";
BA_ "Confidence" SG_ 864 VCLEFT_a476_hvac2RRightAirwaveLa 1;
BA_ "SystemSignalLongSymbol" SG_ 864 VCLEFT_a476_hvac2RRightAirwaveLa "VCLEFT_a476_hvac2RRightAirwaveLateralWarning";
BA_ "Confidence" SG_ 864 VCLEFT_a477_hvac2RRightAirwaveLa 1;
BA_ "SystemSignalLongSymbol" SG_ 864 VCLEFT_a477_hvac2RRightAirwaveLa "VCLEFT_a477_hvac2RRightAirwaveLateralUncalib";
BA_ "Confidence" SG_ 864 VCLEFT_a478_BPillarCameraHeaterF 1;
BA_ "SystemSignalLongSymbol" SG_ 864 VCLEFT_a478_BPillarCameraHeaterF "VCLEFT_a478_BPillarCameraHeaterFault";
BA_ "Confidence" SG_ 864 VCLEFT_a480_vnf1048Fault 1;
BA_ "Confidence" SG_ 864 VCLEFT_a481_vnf1048SelfTestFailu 1;
BA_ "SystemSignalLongSymbol" SG_ 864 VCLEFT_a481_vnf1048SelfTestFailu "VCLEFT_a481_vnf1048SelfTestFailure";
BA_ "Confidence" SG_ 864 VCLEFT_a482_NCV77XXFault 1;
BA_ "Confidence" SG_ 864 VCLEFT_a490_vehicleOccupiedOnOTA 1;
BA_ "SystemSignalLongSymbol" SG_ 864 VCLEFT_a490_vehicleOccupiedOnOTA "VCLEFT_a490_vehicleOccupiedOnOTAStart";
BA_ "Confidence" SG_ 864 VCLEFT_a498_canAuthenticationFai 1;
BA_ "SystemSignalLongSymbol" SG_ 864 VCLEFT_a498_canAuthenticationFai "VCLEFT_a498_canAuthenticationFailure";
BA_ "Confidence" SG_ 864 VCLEFT_a499_epbmInvalidateCdp 1;
BA_ "Confidence" SG_ 864 VCLEFT_a500_eFuseASICStateMismat 1;
BA_ "SystemSignalLongSymbol" SG_ 864 VCLEFT_a500_eFuseASICStateMismat "VCLEFT_a500_eFuseASICStateMismatch";
BA_ "Confidence" SG_ 864 VCLEFT_a501_vnf1048Configuration 1;
BA_ "SystemSignalLongSymbol" SG_ 864 VCLEFT_a501_vnf1048Configuration "VCLEFT_a501_vnf1048ConfigurationMismatch";
BA_ "Confidence" SG_ 864 VCLEFT_a520_configMismatch 1;
BA_ "Confidence" SG_ 864 VCLEFT_a521_seatHeatPadUnexpecte 1;
BA_ "SystemSignalLongSymbol" SG_ 864 VCLEFT_a521_seatHeatPadUnexpecte "VCLEFT_a521_seatHeatPadUnexpectedVoltage";
BA_ "Confidence" SG_ 864 VCLEFT_a522_trailerLightUnexpect 1;
BA_ "SystemSignalLongSymbol" SG_ 864 VCLEFT_a522_trailerLightUnexpect "VCLEFT_a522_trailerLightUnexpectedVoltage";
BA_ "Confidence" SG_ 864 VCLEFT_a523_eFuseThresholdsIncor 1;
BA_ "SystemSignalLongSymbol" SG_ 864 VCLEFT_a523_eFuseThresholdsIncor "VCLEFT_a523_eFuseThresholdsIncorrect";
BA_ "Confidence" SG_ 864 VCLEFT_a525_LVBatterySWMisconfig 1;
BA_ "SystemSignalLongSymbol" SG_ 864 VCLEFT_a525_LVBatterySWMisconfig "VCLEFT_a525_LVBatterySWMisconfiguration";
BA_ "Confidence" SG_ 864 VCLEFT_a526_pcbaOverTemperature 1;
BA_ "Confidence" SG_ 864 VCLEFT_a527_continuousFeedUnexpe 1;
BA_ "SystemSignalLongSymbol" SG_ 864 VCLEFT_a527_continuousFeedUnexpe "VCLEFT_a527_continuousFeedUnexpectedVoltage";
BA_ "Confidence" SG_ 864 VCLEFT_a528_unableToRunStuckOnTe 1;
BA_ "SystemSignalLongSymbol" SG_ 864 VCLEFT_a528_unableToRunStuckOnTe "VCLEFT_a528_unableToRunStuckOnTest";
BA_ "Confidence" SG_ 864 VCLEFT_a536_trunkFoldFlatSwitchF 1;
BA_ "SystemSignalLongSymbol" SG_ 864 VCLEFT_a536_trunkFoldFlatSwitchF "VCLEFT_a536_trunkFoldFlatSwitchFault";
BA_ "Confidence" SG_ 864 VCLEFT_a545_LVBatteryTypeUnknown 1;
BA_ "Confidence" SG_ 864 VCLEFT_a546_mirrorFoldTypeChange 1;
BA_ "SystemSignalLongSymbol" SG_ 864 VCLEFT_a546_mirrorFoldTypeChange "VCLEFT_a546_mirrorFoldTypeChanged";
BA_ "Confidence" SG_ 864 VCLEFT_a550_ambientTempDelta 1;
BA_ "Confidence" SG_ 864 VCLEFT_a551_interiorDoorRequestI 1;
BA_ "SystemSignalLongSymbol" SG_ 864 VCLEFT_a551_interiorDoorRequestI "VCLEFT_a551_interiorDoorRequestInhibited";
BA_ "Confidence" SG_ 864 VCLEFT_a554_RCM2_MIA 1;
BA_ "Confidence" SG_ 864 VCLEFT_a555_steeringWheelHeaterC 1;
BA_ "SystemSignalLongSymbol" SG_ 864 VCLEFT_a555_steeringWheelHeaterC "VCLEFT_a555_steeringWheelHeaterCompromised";
BA_ "Confidence" SG_ 864 VCLEFT_a560_2RowSeatUncalibrated 1;
BA_ "Confidence" SG_ 864 VCLEFT_a561_2RowSeatPositionNons 1;
BA_ "SystemSignalLongSymbol" SG_ 864 VCLEFT_a561_2RowSeatPositionNons "VCLEFT_a561_2RowSeatPositionNonsensical";
BA_ "Confidence" SG_ 864 VCLEFT_a562_2RowSeatAbsPosOffset 1;
BA_ "SystemSignalLongSymbol" SG_ 864 VCLEFT_a562_2RowSeatAbsPosOffset "VCLEFT_a562_2RowSeatAbsPosOffsetApplied";
BA_ "Confidence" SG_ 864 VCLEFT_a563_2RowSeatObstacleDete 1;
BA_ "SystemSignalLongSymbol" SG_ 864 VCLEFT_a563_2RowSeatObstacleDete "VCLEFT_a563_2RowSeatObstacleDetected";
BA_ "Confidence" SG_ 864 VCLEFT_a564_2RowSeatTempHigh 1;
BA_ "Confidence" SG_ 864 VCLEFT_a565_2RowSeatAbsPosSensor 1;
BA_ "SystemSignalLongSymbol" SG_ 864 VCLEFT_a565_2RowSeatAbsPosSensor "VCLEFT_a565_2RowSeatAbsPosSensorTransitionDbg";
BA_ "Confidence" SG_ 864 VCLEFT_a566_2RowSeatStatsFromLas 1;
BA_ "SystemSignalLongSymbol" SG_ 864 VCLEFT_a566_2RowSeatStatsFromLas "VCLEFT_a566_2RowSeatStatsFromLastStateDbg";
BA_ "Confidence" SG_ 864 VCLEFT_a567_2RowSeatRequestWhile 1;
BA_ "SystemSignalLongSymbol" SG_ 864 VCLEFT_a567_2RowSeatRequestWhile "VCLEFT_a567_2RowSeatRequestWhileUncalibrated";
BA_ "Confidence" SG_ 864 VCLEFT_a568_2RowSeatClashAvoidan 1;
BA_ "SystemSignalLongSymbol" SG_ 864 VCLEFT_a568_2RowSeatClashAvoidan "VCLEFT_a568_2RowSeatClashAvoidanceBlocked";
BA_ "Confidence" SG_ 864 VCLEFT_a569_2RowSeatOverfolded 1;
BA_ "Confidence" SG_ 864 VCLEFT_a570_seatHeatDisabledF 1;
BA_ "Confidence" SG_ 864 VCLEFT_a571_seatHeatDisabledRear 1;
BA_ "SystemSignalLongSymbol" SG_ 864 VCLEFT_a571_seatHeatDisabledRear "VCLEFT_a571_seatHeatDisabledRearL";
BA_ "Confidence" SG_ 864 VCLEFT_a572_seatHeatDisabledRear 1;
BA_ "SystemSignalLongSymbol" SG_ 864 VCLEFT_a572_seatHeatDisabledRear "VCLEFT_a572_seatHeatDisabledRearC";
BA_ "Confidence" SG_ 864 VCLEFT_a573_seatHeatDisabledRear 1;
BA_ "SystemSignalLongSymbol" SG_ 864 VCLEFT_a573_seatHeatDisabledRear "VCLEFT_a573_seatHeatDisabledRearR";
BA_ "Confidence" SG_ 864 VCLEFT_a576_liftgateStrutPositio 1;
BA_ "SystemSignalLongSymbol" SG_ 864 VCLEFT_a576_liftgateStrutPositio "VCLEFT_a576_liftgateStrutPositionMismatch";
BA_ "Confidence" SG_ 864 VCLEFT_a577_bsiHardwareIssue 1;
BA_ "Confidence" SG_ 864 VCLEFT_a578_RGBLightFault 1;
BA_ "Confidence" SG_ 864 VCLEFT_a579_leftSteeringWheelCtr 1;
BA_ "SystemSignalLongSymbol" SG_ 864 VCLEFT_a579_leftSteeringWheelCtr "VCLEFT_a579_leftSteeringWheelCtrlTypeMismatch";
BA_ "Confidence" SG_ 864 VCLEFT_a580_rightSteeringWheelCt 1;
BA_ "SystemSignalLongSymbol" SG_ 864 VCLEFT_a580_rightSteeringWheelCt "VCLEFT_a580_rightSteeringWheelCtrlTypeMismatch";
BA_ "Confidence" SG_ 864 VCLEFT_a581_reverseLightFault 1;
BA_ "Confidence" SG_ 864 VCLEFT_a583_doorRemoteUnlatchedF 1;
BA_ "SystemSignalLongSymbol" SG_ 864 VCLEFT_a583_doorRemoteUnlatchedF "VCLEFT_a583_doorRemoteUnlatchedFront";
BA_ "Confidence" SG_ 864 VCLEFT_a584_doorRemoteUnlatchedR 1;
BA_ "SystemSignalLongSymbol" SG_ 864 VCLEFT_a584_doorRemoteUnlatchedR "VCLEFT_a584_doorRemoteUnlatchedRear";
BA_ "Confidence" SG_ 864 VCLEFT_a585_doorRemoteUnlatchFai 1;
BA_ "SystemSignalLongSymbol" SG_ 864 VCLEFT_a585_doorRemoteUnlatchFai "VCLEFT_a585_doorRemoteUnlatchFailedFront";
BA_ "Confidence" SG_ 864 VCLEFT_a586_doorRemoteUnlatchFai 1;
BA_ "SystemSignalLongSymbol" SG_ 864 VCLEFT_a586_doorRemoteUnlatchFai "VCLEFT_a586_doorRemoteUnlatchFailedRear";
BA_ "Confidence" SG_ 864 VCLEFT_a599_LVBatteryTypeUnsuppo 1;
BA_ "SystemSignalLongSymbol" SG_ 864 VCLEFT_a599_LVBatteryTypeUnsuppo "VCLEFT_a599_LVBatteryTypeUnsupported";
BA_ "Confidence" SG_ 258 VCLEFT_doorClosureStatusFront 0;
BA_ "GenSigSNA" SG_ 258 VCLEFT_doorClosureStatusFront "0";
BA_ "Confidence" SG_ 258 VCLEFT_doorClosureStatusRear 0;
BA_ "GenSigSNA" SG_ 258 VCLEFT_doorClosureStatusRear "0";
BA_ "Confidence" SG_ 258 VCLEFT_frontLatchSwitch 0;
BA_ "Confidence" SG_ 258 VCLEFT_rearLatchSwitch 0;
BA_ "Confidence" SG_ 258 VCLEFT_frontHandlePulled 0;
BA_ "Confidence" SG_ 258 VCLEFT_rearHandlePulled 0;
BA_ "Confidence" SG_ 258 VCLEFT_frontRelActuatorSwitch 0;
BA_ "Confidence" SG_ 258 VCLEFT_rearRelActuatorSwitch 0;
BA_ "Confidence" SG_ 258 VCLEFT_frontLatchStatus 0;
BA_ "GenSigSNA" SG_ 258 VCLEFT_frontLatchStatus "0";
BA_ "Confidence" SG_ 258 VCLEFT_rearLatchStatus 0;
BA_ "GenSigSNA" SG_ 258 VCLEFT_rearLatchStatus "0";
BA_ "Confidence" SG_ 258 VCLEFT_lastDoorReqSourceFront 0;
BA_ "Confidence" SG_ 258 VCLEFT_lastDoorReqSourceRear 0;
BA_ "Confidence" SG_ 258 VCLEFT_frontIntSwitchPressed 0;
BA_ "Confidence" SG_ 258 VCLEFT_rearIntSwitchPressed 0;
BA_ "Confidence" SG_ 258 VCLEFT_mirrorTiltXPosition 0;
BA_ "Confidence" SG_ 258 VCLEFT_mirrorTiltYPosition 0;
BA_ "Confidence" SG_ 258 VCLEFT_mirrorState 0;
BA_ "Confidence" SG_ 258 VCLEFT_mirrorFoldState 0;
BA_ "Confidence" SG_ 258 VCLEFT_mirrorRecallState 0;
BA_ "Confidence" SG_ 258 VCLEFT_mirrorHeatState 0;
BA_ "GenSigSNA" SG_ 258 VCLEFT_mirrorHeatState "0";
BA_ "Confidence" SG_ 258 VCLEFT_rearHandlePulledPersist 0;
BA_ "Confidence" SG_ 258 VCLEFT_frontHandlePulledPersist 0;
BA_ "Confidence" SG_ 258 VCLEFT_mirrorDipped 0;
BA_ "Confidence" SG_ 626 VCLEFT_epbmDebugIndex 1;
BA_ "Confidence" SG_ 626 VCLEFT_epbmCaliperState 0;
BA_ "Confidence" SG_ 626 VCLEFT_epbmMotorEnabled 0;
BA_ "Confidence" SG_ 626 VCLEFT_epbMotorCurrent 0;
BA_ "Confidence" SG_ 626 VCLEFT_epbmApplyVoltage 0;
BA_ "Confidence" SG_ 626 VCLEFT_epbmReleaseVoltage 0;
BA_ "Confidence" SG_ 626 VCLEFT_summonFaultReason 1;
BA_ "Confidence" SG_ 626 VCLEFT_epbSummonState 1;
BA_ "Confidence" SG_ 626 VCLEFT_epbmSummonState 1;
BA_ "Confidence" SG_ 626 VCLEFT_epbUnitStatus 1;
BA_ "Confidence" SG_ 626 VCLEFT_epbmFaultStatus 1;
BA_ "Confidence" SG_ 626 VCLEFT_epbFaultStatus 1;
BA_ "Confidence" SG_ 626 VCLEFT_epbmSystemStatus 1;
BA_ "Confidence" SG_ 1140 VCLEFT_cdpRequestState 0;
BA_ "Confidence" SG_ 1140 VCLEFT_epbmSystemStatusQF 0;
BA_ "Confidence" SG_ 1140 VCLEFT_epbmUnitStatus 0;
BA_ "Confidence" SG_ 1140 VCLEFT_epbmCdpState 0;
BA_ "Confidence" SG_ 1140 VCLEFT_epbmStatusCounter 0;
BA_ "Confidence" SG_ 1140 VCLEFT_epbmStatusChecksum 0;
BA_ "Confidence" SG_ 770 VCLEFT_infoIndex 1;
BA_ "Confidence" SG_ 770 VCLEFT_infoBuildType 0;
BA_ "Confidence" SG_ 770 VCLEFT_infoBuildConfigId 0;
BA_ "Confidence" SG_ 770 VCLEFT_infoHardwareId 0;
BA_ "Confidence" SG_ 770 VCLEFT_infoComponentId 0;
BA_ "Confidence" SG_ 770 VCLEFT_infoPcbaId 0;
BA_ "Confidence" SG_ 770 VCLEFT_infoAssemblyId 0;
BA_ "GenSigSNA" SG_ 770 VCLEFT_infoAssemblyId "255";
BA_ "Confidence" SG_ 770 VCLEFT_infoUsageId 0;
BA_ "Confidence" SG_ 770 VCLEFT_infoSubUsageId 0;
BA_ "Confidence" SG_ 770 VCLEFT_infoAppCrc 0;
BA_ "Confidence" SG_ 770 VCLEFT_infoAppGitHash 0;
BA_ "Confidence" SG_ 770 VCLEFT_infoBootGitHash 0;
BA_ "Confidence" SG_ 770 VCLEFT_infoPlatformType 0;
BA_ "Confidence" SG_ 770 VCLEFT_infoBootUdsProtoVersion 0;
BA_ "Confidence" SG_ 770 VCLEFT_infoBootCrc 0;
VAL_ 2013 VCLEFT_a426_seatMotorState 5 "UNDEFINED" 4 "CALIBRATING" 3 "RECALLING" 2 "MOVING_DOWN" 1 "MOVING_UP" 0 "STOPPED" ;
VAL_ 2013 VCLEFT_a426_seatSwitchBack 3 "FAULT" 2 "ON" 1 "OFF" 0 "SNA" ;
VAL_ 2013 VCLEFT_a426_seatSwitchForward 3 "FAULT" 2 "ON" 1 "OFF" 0 "SNA" ;
VAL_ 2013 VCLEFT_a427_seatMotorState 5 "UNDEFINED" 4 "CALIBRATING" 3 "RECALLING" 2 "MOVING_DOWN" 1 "MOVING_UP" 0 "STOPPED" ;
VAL_ 2013 VCLEFT_a427_seatSwitchBack 3 "FAULT" 2 "ON" 1 "OFF" 0 "SNA" ;
VAL_ 2013 VCLEFT_a427_seatSwitchForward 3 "FAULT" 2 "ON" 1 "OFF" 0 "SNA" ;
VAL_ 2013 VCLEFT_a428_seatMotorState 5 "UNDEFINED" 4 "CALIBRATING" 3 "RECALLING" 2 "MOVING_DOWN" 1 "MOVING_UP" 0 "STOPPED" ;
VAL_ 2013 VCLEFT_a428_seatSwitchBack 3 "FAULT" 2 "ON" 1 "OFF" 0 "SNA" ;
VAL_ 2013 VCLEFT_a428_seatSwitchForward 3 "FAULT" 2 "ON" 1 "OFF" 0 "SNA" ;
VAL_ 2013 VCLEFT_a429_seatMotorState 5 "UNDEFINED" 4 "CALIBRATING" 3 "RECALLING" 2 "MOVING_DOWN" 1 "MOVING_UP" 0 "STOPPED" ;
VAL_ 2013 VCLEFT_a429_seatSwitchBack 3 "FAULT" 2 "ON" 1 "OFF" 0 "SNA" ;
VAL_ 2013 VCLEFT_a429_seatSwitchForward 3 "FAULT" 2 "ON" 1 "OFF" 0 "SNA" ;
VAL_ 2013 VCLEFT_a447_motorType 3 "NEXTEER" 2 "BOSCH_COMMON_TO_JE" 1 "JE" 0 "BOSCH" ;
VAL_ 2013 VCLEFT_a448_motorType 3 "NEXTEER" 2 "BOSCH_COMMON_TO_JE" 1 "JE" 0 "BOSCH" ;
VAL_ 2013 VCLEFT_a455_liftgateState 13 "PARTY_DANCE" 12 "LATCH_ENTRY" 11 "END_OF_TRAVEL" 10 "LATCH_EXIT" 9 "UNKNOWN" 8 "NOT_INSTALLED" 7 "LATCH_CLOSING" 6 "LATCH_OPENING" 5 "CLOSED" 4 "CLOSING" 3 "OPENING" 2 "BACKOFF" 1 "OFF" 0 "INIT" ;
VAL_ 2013 VCLEFT_a500_mismatchedState 7 "SELF_TEST" 6 "SELF_TEST_PREP" 5 "LOCKED" 4 "UNLOCKED" 3 "CONFIGURATION" 2 "WAKEUP" 1 "STANDBY" 0 "UNKNOWN" ;
VAL_ 2013 VCLEFT_a520_epbConfig 11 "CT_MANDO" 10 "MODEL3_ZF" 9 "MODELS_CERAMIC" 8 "MODELY_PERFORMANCE_V2" 7 "MODEL3_PERFORMANCE_V2" 6 "MODELX_BASE" 5 "MODELY_PERFORMANCE" 4 "MODELY_BASE" 3 "MODELS_BASE" 2 "MODEL3_PERFORMANCE" 1 "MODEL3_BASE" 0 "UNKNOWN" ;
VAL_ 2013 VCLEFT_a520_gtwEpbConfig 11 "CT_MANDO" 10 "MODEL3_ZF" 9 "MODELS_CERAMIC" 8 "MODELY_PERFORMANCE_V2" 7 "MODEL3_PERFORMANCE_V2" 6 "MODELX_BASE" 5 "MODELY_PERFORMANCE" 4 "MODELY_BASE" 3 "MODELS_BASE" 2 "MODEL3_PERFORMANCE" 1 "MODEL3_BASE" 0 "UNKNOWN" ;
VAL_ 2013 VCLEFT_a525_GTW_twelveVBatteryTy 3 "TESLA_16V_LI_ION" 2 "CATL_LI_ION" 1 "CLARIOS_B24_FLOODED" 0 "ATLASBX_B24_FLOODED" ;
VAL_ 2013 VCLEFT_a525_newLVBatteryType 5 "TESLA_48V_LI_ION" 4 "TESLA_16V_LI_ION" 3 "CATL_LI_ION" 2 "CLARIOS_B24_FLOODED" 1 "ATLASBX_B24_FLOODED" 0 "UNKNOWN" ;
VAL_ 2013 VCLEFT_a525_initialLVBatteryType 5 "TESLA_48V_LI_ION" 4 "TESLA_16V_LI_ION" 3 "CATL_LI_ION" 2 "CLARIOS_B24_FLOODED" 1 "ATLASBX_B24_FLOODED" 0 "UNKNOWN" ;
VAL_ 2013 VCLEFT_a536_trunkFoldFlatSwitchS 3 "FAULT" 2 "ON" 1 "OFF" 0 "SNA" ;
VAL_ 2013 VCLEFT_a545_GTW_twelveVBatteryTy 3 "TESLA_16V_LI_ION" 2 "CATL_LI_ION" 1 "CLARIOS_B24_FLOODED" 0 "ATLASBX_B24_FLOODED" ;
VAL_ 2013 VCLEFT_a545_newLVBatteryType 5 "TESLA_48V_LI_ION" 4 "TESLA_16V_LI_ION" 3 "CATL_LI_ION" 2 "CLARIOS_B24_FLOODED" 1 "ATLASBX_B24_FLOODED" 0 "UNKNOWN" ;
VAL_ 2013 VCLEFT_a560_seatState 15 "SNA" 12 "CALIBRATING_ABSOLUTE_SENSOR" 11 "CALIBRATING_ZERO_POSITION" 10 "WAITING_TO_CLEAR_FOR_UNFOLD" 9 "WAITING_TO_CLEAR_FOR_FOLD" 8 "MOVING_REARWARD_TO_POSITION" 7 "MOVING_FORWARD_TO_POSITION" 6 "UNFOLDING" 5 "FOLDING" 4 "ADJUSTING_REARWARD_FAST" 3 "ADJUSTING_FORWARD_FAST" 2 "ADJUSTING_REARWARD_COMFORT" 1 "ADJUSTING_FORWARD_COMFORT" 0 "STOPPED" ;
VAL_ 2013 VCLEFT_a560_motorType 1 "KEIPER" 0 "SHB_OR_UNKNOWN" ;
VAL_ 2013 VCLEFT_a560_absPosSensState 3 "DISCONNECTED" 2 "FORWARD" 1 "REARWARD" 0 "FAULTED" ;
VAL_ 2013 VCLEFT_a563_seatStatePrev 15 "SNA" 12 "CALIBRATING_ABSOLUTE_SENSOR" 11 "CALIBRATING_ZERO_POSITION" 10 "WAITING_TO_CLEAR_FOR_UNFOLD" 9 "WAITING_TO_CLEAR_FOR_FOLD" 8 "MOVING_REARWARD_TO_POSITION" 7 "MOVING_FORWARD_TO_POSITION" 6 "UNFOLDING" 5 "FOLDING" 4 "ADJUSTING_REARWARD_FAST" 3 "ADJUSTING_FORWARD_FAST" 2 "ADJUSTING_REARWARD_COMFORT" 1 "ADJUSTING_FORWARD_COMFORT" 0 "STOPPED" ;
VAL_ 2013 VCLEFT_a563_obstacleDetectReason 8 "MAX_SPEED_DIFF" 7 "SPEED_THRESHOLD" 6 "MEDIUM_CURRENT_THRESHOLD" 5 "ACCEL_LOOKBACK_COMP_ABS" 4 "ACCEL_LOOKBACK_UNCOMP_REL" 3 "ACCEL_LOOKBACK_UNCOMP_ABS" 2 "MOTOR_ENCODER_STALL" 1 "MOTOR_CURRENT_STALL" 0 "NONE" ;
VAL_ 2013 VCLEFT_a563_motorType 1 "KEIPER" 0 "SHB_OR_UNKNOWN" ;
VAL_ 2013 VCLEFT_a568_seatState 15 "SNA" 12 "CALIBRATING_ABSOLUTE_SENSOR" 11 "CALIBRATING_ZERO_POSITION" 10 "WAITING_TO_CLEAR_FOR_UNFOLD" 9 "WAITING_TO_CLEAR_FOR_FOLD" 8 "MOVING_REARWARD_TO_POSITION" 7 "MOVING_FORWARD_TO_POSITION" 6 "UNFOLDING" 5 "FOLDING" 4 "ADJUSTING_REARWARD_FAST" 3 "ADJUSTING_FORWARD_FAST" 2 "ADJUSTING_REARWARD_COMFORT" 1 "ADJUSTING_FORWARD_COMFORT" 0 "STOPPED" ;
VAL_ 2013 VCLEFT_a579_gtwConfigType 5 "TESLA_GEN5" 2 "KOSTAL" 1 "PREH" ;
VAL_ 2013 VCLEFT_a580_gtwConfigType 5 "TESLA_GEN5" 2 "KOSTAL" 1 "PREH" ;
VAL_ 2013 VCLEFT_a585_ambientTemp 0 "SNA" ;
VAL_ 2013 VCLEFT_a586_ambientTemp 0 "SNA" ;
VAL_ 2013 VCLEFT_a599_GTW_twelveVBatteryTy 3 "TESLA_16V_LI_ION" 2 "CATL_LI_ION" 1 "CLARIOS_B24_FLOODED" 0 "ATLASBX_B24_FLOODED" ;
VAL_ 2013 VCLEFT_a599_newLVBatteryType 5 "TESLA_48V_LI_ION" 4 "TESLA_16V_LI_ION" 3 "CATL_LI_ION" 2 "CLARIOS_B24_FLOODED" 1 "ATLASBX_B24_FLOODED" 0 "UNKNOWN" ;
VAL_ 2013 VCLEFT_a599_initialLVBatteryType 5 "TESLA_48V_LI_ION" 4 "TESLA_16V_LI_ION" 3 "CATL_LI_ION" 2 "CLARIOS_B24_FLOODED" 1 "ATLASBX_B24_FLOODED" 0 "UNKNOWN" ;
VAL_ 864 VCLEFT_matrixIndex 10 "AlertMatrix10" 9 "AlertMatrix9" 8 "AlertMatrix8" 7 "AlertMatrix7" 6 "AlertMatrix6" 5 "AlertMatrix5" 4 "AlertMatrix4" 3 "AlertMatrix3" 2 "AlertMatrix2" 1 "AlertMatrix1" 0 "AlertMatrix0" ;
VAL_ 258 VCLEFT_doorClosureStatusFront 8 "CLOSURE_STATUS_FAULT" 2 "CLOSURE_STATUS_CLOSED" 1 "CLOSURE_STATUS_OPEN" 0 "CLOSURE_STATUS_SNA" ;
VAL_ 258 VCLEFT_doorClosureStatusRear 8 "CLOSURE_STATUS_FAULT" 2 "CLOSURE_STATUS_CLOSED" 1 "CLOSURE_STATUS_OPEN" 0 "CLOSURE_STATUS_SNA" ;
VAL_ 258 VCLEFT_frontLatchStatus 8 "LATCH_FAULT" 7 "LATCH_DEFAULT" 6 "LATCH_TIMEOUT" 5 "LATCH_AJAR" 4 "LATCH_OPENING" 3 "LATCH_CLOSING" 2 "LATCH_CLOSED" 1 "LATCH_OPENED" 0 "LATCH_SNA" ;
VAL_ 258 VCLEFT_rearLatchStatus 8 "LATCH_FAULT" 7 "LATCH_DEFAULT" 6 "LATCH_TIMEOUT" 5 "LATCH_AJAR" 4 "LATCH_OPENING" 3 "LATCH_CLOSING" 2 "LATCH_CLOSED" 1 "LATCH_OPENED" 0 "LATCH_SNA" ;
VAL_ 258 VCLEFT_lastDoorReqSourceFront 4 "DOOR_REQUEST_SOURCE_ECU" 3 "DOOR_REQUEST_SOURCE_VCSEC" 2 "DOOR_REQUEST_SOURCE_EXTERIOR_HANDLE" 1 "DOOR_REQUEST_SOURCE_INTERIOR_BUTTON" 0 "DOOR_REQUEST_SOURCE_UNKNOWN" ;
VAL_ 258 VCLEFT_lastDoorReqSourceRear 4 "DOOR_REQUEST_SOURCE_ECU" 3 "DOOR_REQUEST_SOURCE_VCSEC" 2 "DOOR_REQUEST_SOURCE_EXTERIOR_HANDLE" 1 "DOOR_REQUEST_SOURCE_INTERIOR_BUTTON" 0 "DOOR_REQUEST_SOURCE_UNKNOWN" ;
VAL_ 258 VCLEFT_mirrorState 5 "MIRROR_STATE_CALIBRATION" 4 "MIRROR_STATE_RECALL" 3 "MIRROR_STATE_FOLD_UNFOLD" 2 "MIRROR_STATE_TILT_Y" 1 "MIRROR_STATE_TILT_X" 0 "MIRROR_STATE_IDLE" ;
VAL_ 258 VCLEFT_mirrorFoldState 4 "MIRROR_FOLD_STATE_UNFOLDING" 3 "MIRROR_FOLD_STATE_FOLDING" 2 "MIRROR_FOLD_STATE_UNFOLDED" 1 "MIRROR_FOLD_STATE_FOLDED" 0 "MIRROR_FOLD_STATE_UNKNOWN" ;
VAL_ 258 VCLEFT_mirrorRecallState 5 "MIRROR_RECALL_STATE_RECALLING_STOPPED" 4 "MIRROR_RECALL_STATE_RECALLING_FAILED" 3 "MIRROR_RECALL_STATE_RECALLING_COMPLETE" 2 "MIRROR_RECALL_STATE_RECALLING_AXIS_2" 1 "MIRROR_RECALL_STATE_RECALLING_AXIS_1" 0 "MIRROR_RECALL_STATE_INIT" ;
VAL_ 258 VCLEFT_mirrorHeatState 4 "HEATER_STATE_FAULT" 3 "HEATER_STATE_OFF_UNAVAILABLE" 2 "HEATER_STATE_OFF" 1 "HEATER_STATE_ON" 0 "HEATER_STATE_SNA" ;
VAL_ 626 VCLEFT_epbmDebugIndex 1 "TRANSITIONS" 0 "STATES" ;
VAL_ 626 VCLEFT_epbmCaliperState 6 "EPB_SAVED_CALIPERSTATE_WINCHMODE" 5 "EPB_SAVED_CALIPERSTATE_SERVICE" 4 "EPB_SAVED_CALIPERSTATE_OPEN" 3 "EPB_SAVED_CALIPERSTATE_PARK" 2 "EPB_SAVED_CALIPERSTATE_REAPPLY" 1 "EPB_SAVED_CALIPERSTATE_UNKNOWN" 0 "EPB_SAVED_CALIPERSTATE_UNSAVED" ;
VAL_ 626 VCLEFT_summonFaultReason 30 "EPB_SUMMONFAULT_MONITOR_TYPE_UNKNOWN" 29 "EPB_SUMMONFAULT_AP_MONITOR" 28 "EPB_SUMMONFAULT_REMOTE_DID_NOT_START" 27 "EPB_SUMMONFAULT_INVALID_REMOTE_STATE" 26 "EPB_SUMMONFAULT_START_IN_UNAVAILABLE" 25 "EPB_SUMMONFAULT_REMOTE_UNIT_FAULTED" 24 "EPB_SUMMONFAULT_LOCAL_UNIT_FAULTED" 23 "EPB_SUMMONFAULT_REMOTE_SUMMON_FAULTED" 22 "EPB_SUMMONFAULT_EPBREMOTE_MIA" 21 "EPB_SUMMONFAULT_PASSIVE_REQUEST" 20 "EPB_SUMMONFAULT_DI_STATE_INVALID" 19 "EPB_SUMMONFAULT_EPB_FAULT" 18 "EPB_SUMMONFAULT_MISMATCH" 17 "EPB_SUMMONFAULT_OOC" 16 "EPB_SUMMONFAULT_PM_REQUEST" 15 "EPB_SUMMONFAULT_PM_MIA" 14 "EPB_SUMMONFAULT_PARK_MIA" 13 "EPB_SUMMONFAULT_EXTERNAL" 12 "EPB_SUMMONFAULT_SPEED" 11 "EPB_SUMMONFAULT_EPBM_REQUEST" 10 "EPB_SUMMONFAULT_EAC_NOT_ALLOWED" 9 "EPB_SUMMONFAULT_VEH_CAN_FAULT" 8 "EPB_SUMMONFAULT_ESP_FAULT" 7 "EPB_SUMMONFAULT_DAS_FAULT" 6 "EPB_SUMMONFAULT_DI_APC_FAULT" 5 "EPB_SUMMONFAULT_DI_FAULT" 4 "EPB_SUMMONFAULT_EPBM_MIA" 3 "EPB_SUMMONFAULT_ESP_MIA" 2 "EPB_SUMMONFAULT_DAS_MIA" 1 "EPB_SUMMONFAULT_DI_MIA" 0 "EPB_SUMMONFAULT_NONE" ;
VAL_ 626 VCLEFT_epbSummonState 6 "EPB_SUMMON_UNAVAILABLE" 5 "EPB_SUMMON_FAULT" 4 "EPB_SUMMON_COMPLETE" 3 "EPB_SUMMON_ACTIVE" 2 "EPB_SUMMON_ARMED" 1 "EPB_SUMMON_IDLE" 0 "EPB_SUMMON_INIT" ;
VAL_ 626 VCLEFT_epbmSummonState 6 "EPB_SUMMON_UNAVAILABLE" 5 "EPB_SUMMON_FAULT" 4 "EPB_SUMMON_COMPLETE" 3 "EPB_SUMMON_ACTIVE" 2 "EPB_SUMMON_ARMED" 1 "EPB_SUMMON_IDLE" 0 "EPB_SUMMON_INIT" ;
VAL_ 626 VCLEFT_epbUnitStatus 23 "EPB_STATUS_COUNT" 22 "EPB_STATUS_AUTONOMY_OPEN" 21 "EPB_STATUS_FREE_ROLL_MODE" 20 "EPB_STATUS_DYNAMIC_PARKING" 19 "EPB_STATUS_EXTERNAL_PARKING" 18 "EPB_STATUS_RELEASING_FOR_EXTERNAL_PARK" 17 "EPB_STATUS_EXTERNAL_DYNAMIC" 16 "EPB_STATUS_SUMMON_PARKING" 15 "EPB_STATUS_SUMMON_RELEASING" 14 "EPB_STATUS_SUMMON" 13 "EPB_STATUS_WINCHMODE_PENDING" 12 "EPB_STATUS_PARK_PENDING" 11 "EPB_STATUS_SERVICE_RELEASING" 10 "EPB_STATUS_RELEASING" 9 "EPB_STATUS_DYNAMIC_APPLYING" 8 "EPB_STATUS_PARKING" 7 "EPB_STATUS_WINCHMODE_RELEASING" 6 "EPB_STATUS_WINCHMODE" 5 "EPB_STATUS_SERVICE" 4 "EPB_STATUS_START" 3 "EPB_STATUS_PARK" 2 "EPB_STATUS_DYNAMIC" 1 "EPB_STATUS_OPEN" 0 "EPB_STATUS_UNKNOWN" ;
VAL_ 626 VCLEFT_epbmFaultStatus 3 "EPB_STATUS_FAULT_IDLE" 2 "EPB_STATUS_FAULT" 1 "EPB_STATUS_RETRY" 0 "EPB_STATUS_NOMINAL" ;
VAL_ 626 VCLEFT_epbFaultStatus 3 "EPB_STATUS_FAULT_IDLE" 2 "EPB_STATUS_FAULT" 1 "EPB_STATUS_RETRY" 0 "EPB_STATUS_NOMINAL" ;
VAL_ 626 VCLEFT_epbmSystemStatus 8 "EPB_VEHICLE_STATUS_MISMATCH" 7 "EPB_VEHICLE_STATUS_FAULT_SECURE" 6 "EPB_VEHICLE_STATUS_FAULT" 5 "EPB_VEHICLE_STATUS_RELEASING" 4 "EPB_VEHICLE_STATUS_PARKING" 3 "EPB_VEHICLE_STATUS_DYNAMIC" 2 "EPB_VEHICLE_STATUS_PARKED" 1 "EPB_VEHICLE_STATUS_RELEASED" 0 "EPB_VEHICLE_STATUS_UNKNOWN" ;
VAL_ 1140 VCLEFT_cdpRequestState 1 "EPB_CDP_REQUEST_VALID" 0 "EPB_CDP_REQUEST_INVALID" ;
VAL_ 1140 VCLEFT_epbmSystemStatusQF 1 "EPBM_SYSTEM_STATUS_INVALID" 0 "EPBM_SYSTEM_STATUS_VALID" ;
VAL_ 1140 VCLEFT_epbmUnitStatus 23 "EPB_STATUS_COUNT" 22 "EPB_STATUS_AUTONOMY_OPEN" 21 "EPB_STATUS_FREE_ROLL_MODE" 20 "EPB_STATUS_DYNAMIC_PARKING" 19 "EPB_STATUS_EXTERNAL_PARKING" 18 "EPB_STATUS_RELEASING_FOR_EXTERNAL_PARK" 17 "EPB_STATUS_EXTERNAL_DYNAMIC" 16 "EPB_STATUS_SUMMON_PARKING" 15 "EPB_STATUS_SUMMON_RELEASING" 14 "EPB_STATUS_SUMMON" 13 "EPB_STATUS_WINCHMODE_PENDING" 12 "EPB_STATUS_PARK_PENDING" 11 "EPB_STATUS_SERVICE_RELEASING" 10 "EPB_STATUS_RELEASING" 9 "EPB_STATUS_DYNAMIC_APPLYING" 8 "EPB_STATUS_PARKING" 7 "EPB_STATUS_WINCHMODE_RELEASING" 6 "EPB_STATUS_WINCHMODE" 5 "EPB_STATUS_SERVICE" 4 "EPB_STATUS_START" 3 "EPB_STATUS_PARK" 2 "EPB_STATUS_DYNAMIC" 1 "EPB_STATUS_OPEN" 0 "EPB_STATUS_UNKNOWN" ;
VAL_ 1140 VCLEFT_epbmCdpState 2 "EPB_CDP_STATE_FAULT" 1 "EPB_CDP_STATE_VALID" 0 "EPB_CDP_STATE_UNKNOWN" ;
VAL_ 770 VCLEFT_infoIndex 255 "END" 41 "SUBCOMPONENT14" 40 "SUBCOMPONENT13" 39 "SUBCOMPONENT12" 38 "SUBCOMPONENT11" 37 "SUBCOMPONENT10" 36 "SUBCOMPONENT9" 35 "SUBCOMPONENT8" 34 "SUBCOMPONENT7" 33 "SUBCOMPONENT6" 32 "SUBCOMPONENT5" 31 "SUBCOMPONENT4" 24 "SUBCOMPONENT3" 23 "SUBCOMPONENT2" 20 "UDS_PROTOCOL_BOOTCRC" 19 "VERSION_DEPRECATED" 18 "BOOTLOADER_GITHASH" 17 "APP_GITHASH" 16 "SUBCOMPONENT1" 15 "BOOTLOADER_CRC" 14 "BOOTLOADER_SVN" 13 "APP_CRC" 11 "PCBAID_ASSYID_USAGEID" 10 "BUILD_HWID_COMPONENTID" 9 "DEPRECATED_9" 8 "DEPRECATED_8" 7 "DEPRECATED_7" 6 "DEPRECATED_6" 5 "DEPRECATED_5" 4 "DEPRECATED_4" 3 "DEPRECATED_3" 2 "DEPRECATED_2" 1 "DEPRECATED_1" 0 "DEPRECATED_0" ;
VAL_ 770 VCLEFT_infoBuildType 4 "INFO_MFG_BUILD" 3 "INFO_TRACEABLE_CI_BUILD" 2 "INFO_LOCAL_BUILD" 1 "INFO_PLATFORM_BUILD" 0 "INFO_UNKNOWN_BUILD" ;
VAL_ 770 VCLEFT_infoAssemblyId 255 "ASSEMBLY_SNA" 1 "ASSEMBLY1" ;
